VERSION ""

NS_ :

BS_:

BU_: TCM iBooster HCU CIM SCM Right_Hand_Control Left_Hand_Control GPS VCM IC_2 XM GMRS Radio_CANtool Diagnostic_Tool_Digital_Wrench Information_System_Controller_1 STEERING_CONTROLLER VEHICLE_SECURITY RADIO_Hub ABS Battery_Management_Cntrl_2 Battery_Management_Cntrl_1 Auxiliary_Power_Unit_2 Auxiliary_Power_Unit_1 Electric_Propulsion_Cntrl_Unit_4 Electric_Propulsion_Cntrl_Unit_3 Electric_Propulsion_Cntrl_Unit_2 Electric_Propulsion_Cntrl_Unit_1 ECM IC

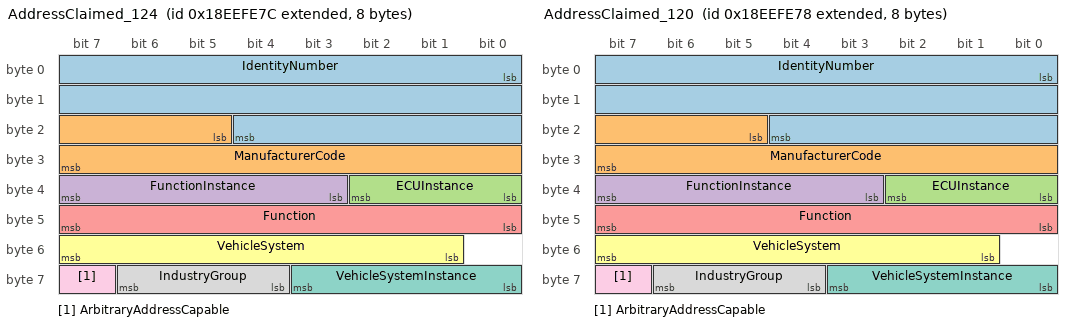
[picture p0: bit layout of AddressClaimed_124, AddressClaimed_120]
BO_ 2565799548 AddressClaimed_124: 8 GMRS
 SG_ IdentityNumber : 0|21@1+ (1,0) [0|2097151] "" Vector__XXX
 SG_ ManufacturerCode : 21|11@1+ (1,0) [0|2047] "" Vector__XXX
 SG_ ECUInstance : 32|3@1+ (1,0) [0|7] "" Vector__XXX
 SG_ FunctionInstance : 35|5@1+ (1,0) [0|31] "" Vector__XXX
 SG_ Function : 40|8@1+ (1,0) [0|255] "" Vector__XXX
 SG_ VehicleSystem : 49|7@1+ (1,0) [0|127] "" Vector__XXX
 SG_ VehicleSystemInstance : 56|4@1+ (1,0) [0|15] "" Vector__XXX
 SG_ IndustryGroup : 60|3@1+ (1,0) [0|7] "" Vector__XXX
 SG_ ArbitraryAddressCapable : 63|1@1+ (1,0) [0|0] "" Vector__XXX

BO_ 2565799544 AddressClaimed_120: 8 Radio_CANtool
 SG_ IdentityNumber : 0|21@1+ (1,0) [0|2097151] "" Vector__XXX
 SG_ ManufacturerCode : 21|11@1+ (1,0) [0|2047] "" Vector__XXX
 SG_ ECUInstance : 32|3@1+ (1,0) [0|7] "" Vector__XXX
 SG_ FunctionInstance : 35|5@1+ (1,0) [0|31] "" Vector__XXX
 SG_ Function : 40|8@1+ (1,0) [0|255] "" Vector__XXX
 SG_ VehicleSystem : 49|7@1+ (1,0) [0|127] "" Vector__XXX
 SG_ VehicleSystemInstance : 56|4@1+ (1,0) [0|15] "" Vector__XXX
 SG_ IndustryGroup : 60|3@1+ (1,0) [0|7] "" Vector__XXX
 SG_ ArbitraryAddressCapable : 63|1@1+ (1,0) [0|0] "" Vector__XXX

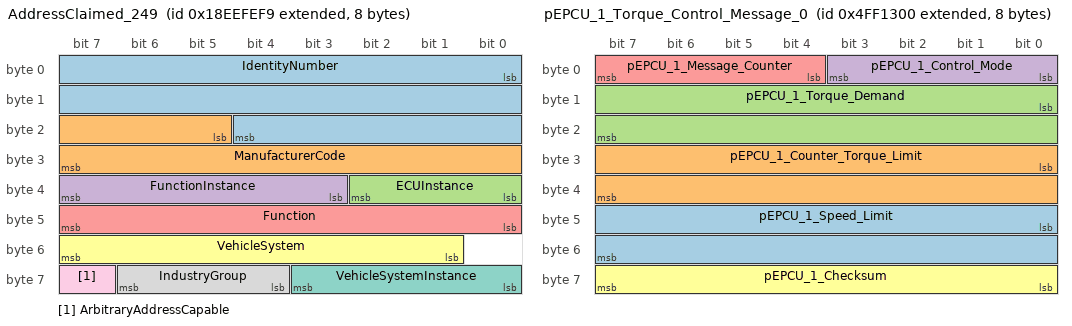
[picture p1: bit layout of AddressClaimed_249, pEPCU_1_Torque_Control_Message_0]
BO_ 2565799673 AddressClaimed_249: 8 Diagnostic_Tool_Digital_Wrench
 SG_ IdentityNumber : 0|21@1+ (1,0) [0|2097151] "" Vector__XXX
 SG_ ManufacturerCode : 21|11@1+ (1,0) [0|2047] "" Vector__XXX
 SG_ ECUInstance : 32|3@1+ (1,0) [0|7] "" Vector__XXX
 SG_ FunctionInstance : 35|5@1+ (1,0) [0|31] "" Vector__XXX
 SG_ Function : 40|8@1+ (1,0) [0|255] "" Vector__XXX
 SG_ VehicleSystem : 49|7@1+ (1,0) [0|127] "" Vector__XXX
 SG_ VehicleSystemInstance : 56|4@1+ (1,0) [0|15] "" Vector__XXX
 SG_ IndustryGroup : 60|3@1+ (1,0) [0|7] "" Vector__XXX
 SG_ ArbitraryAddressCapable : 63|1@1+ (1,0) [0|0] "" Vector__XXX

BO_ 2231309056 pEPCU_1_Torque_Control_Message_0: 8 ECM
 SG_ pEPCU_1_Speed_Limit : 40|16@1+ (1,-32768) [-32768|31488] "rpm" Vector__XXX
 SG_ pEPCU_1_Counter_Torque_Limit : 24|16@1+ (0.1,-3276.8) [-3276.8|3276.7] "Nm" Vector__XXX
 SG_ pEPCU_1_Torque_Demand : 8|16@1+ (0.1,-3276.8) [-3276.8|3276.7] "Nm" Vector__XXX
 SG_ pEPCU_1_Control_Mode : 0|4@1+ (1,0) [0|15] "" Vector__XXX
 SG_ pEPCU_1_Message_Counter : 4|4@1+ (1,0) [0|15] "" Vector__XXX
 SG_ pEPCU_1_Checksum : 56|8@1+ (1,0) [0|255] "" Vector__XXX

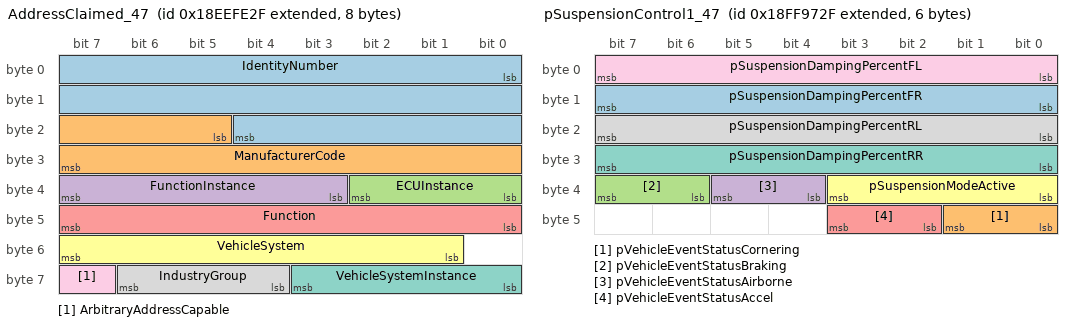
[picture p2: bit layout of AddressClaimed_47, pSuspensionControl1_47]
BO_ 2565799471 AddressClaimed_47: 8 SCM
 SG_ IdentityNumber : 0|21@1+ (1,0) [0|2097151] "" Vector__XXX
 SG_ ManufacturerCode : 21|11@1+ (1,0) [0|2047] "" Vector__XXX
 SG_ ECUInstance : 32|3@1+ (1,0) [0|7] "" Vector__XXX
 SG_ FunctionInstance : 35|5@1+ (1,0) [0|31] "" Vector__XXX
 SG_ Function : 40|8@1+ (1,0) [0|255] "" Vector__XXX
 SG_ VehicleSystem : 49|7@1+ (1,0) [0|127] "" Vector__XXX
 SG_ VehicleSystemInstance : 56|4@1+ (1,0) [0|15] "" Vector__XXX
 SG_ IndustryGroup : 60|3@1+ (1,0) [0|7] "" Vector__XXX
 SG_ ArbitraryAddressCapable : 63|1@1+ (1,0) [0|0] "" Vector__XXX

BO_ 2566887215 pSuspensionControl1_47: 6 SCM
 SG_ pSuspensionDampingPercentFR : 8|8@1+ (0.4,0) [0|100] "%" Vector__XXX
 SG_ pVehicleEventStatusCornering : 40|2@1+ (1,0) [0|3] "status" Vector__XXX
 SG_ pVehicleEventStatusBraking : 38|2@1+ (1,0) [0|3] "status" Vector__XXX
 SG_ pVehicleEventStatusAirborne : 36|2@1+ (1,0) [0|3] "status" Vector__XXX
 SG_ pVehicleEventStatusAccel : 42|2@1+ (1,0) [0|3] "status" Vector__XXX
 SG_ pSuspensionModeActive : 32|4@1+ (1,0) [0|15] "status" Vector__XXX
 SG_ pSuspensionDampingPercentRR : 24|8@1+ (0.4,0) [0|100] "%" Vector__XXX
 SG_ pSuspensionDampingPercentRL : 16|8@1+ (0.4,0) [0|100] "%" Vector__XXX
 SG_ pSuspensionDampingPercentFL : 0|8@1+ (0.4,0) [0|100] "%" Vector__XXX

BO_ 2432656705 pOperatorSwitchStatus_65: 8 Information_System_Controller_1
 SG_ pOperatorButton29 : 58|2@1+ (1,0) [0|3] "" Vector__XXX
 SG_ pOperatorButton1 : 0|2@1+ (1,0) [0|3] "" Vector__XXX
 SG_ pOperatorButton2 : 2|2@1+ (1,0) [0|3] "" Vector__XXX
 SG_ pOperatorButton3 : 4|2@1+ (1,0) [0|3] "" Vector__XXX
 SG_ pOperatorButton4 : 6|2@1+ (1,0) [0|3] "" Vector__XXX
 SG_ pOperatorButton5 : 8|2@1+ (1,0) [0|3] "" Vector__XXX
 SG_ pOperatorButton6 : 10|2@1+ (1,0) [0|3] "" Vector__XXX
 SG_ pOperatorButton7 : 12|2@1+ (1,0) [0|3] "" Vector__XXX
 SG_ pOperatorButton8 : 14|2@1+ (1,0) [0|3] "" Vector__XXX
 SG_ pOperatorButton9 : 16|2@1+ (1,0) [0|3] "" Vector__XXX
 SG_ pOperatorButton10 : 18|2@1+ (1,0) [0|3] "" Vector__XXX
 SG_ pOperatorButton11 : 20|2@1+ (1,0) [0|3] "" Vector__XXX
 SG_ pOperatorButton12 : 22|2@1+ (1,0) [0|3] "" Vector__XXX
 SG_ pOperatorButton13 : 24|2@1+ (1,0) [0|3] "" Vector__XXX
 SG_ pOperatorButton14 : 26|2@1+ (1,0) [0|3] "" Vector__XXX
 SG_ pOperatorButton15 : 28|2@1+ (1,0) [0|3] "" Vector__XXX
 SG_ pOperatorButton16 : 30|2@1+ (1,0) [0|3] "" Vector__XXX
 SG_ pOperatorButton17 : 32|2@1+ (1,0) [0|3] "" Vector__XXX
 SG_ pOperatorButton18 : 34|2@1+ (1,0) [0|3] "" Vector__XXX
 SG_ pOperatorButton19 : 36|2@1+ (1,0) [0|3] "" Vector__XXX
 SG_ pOperatorButton20 : 38|2@1+ (1,0) [0|3] "" Vector__XXX
 SG_ pOperatorButton21 : 40|2@1+ (1,0) [0|3] "" Vector__XXX
 SG_ pOperatorButton22 : 42|2@1+ (1,0) [0|3] "" Vector__XXX
 SG_ pOperatorButton23 : 44|2@1+ (1,0) [0|3] "" Vector__XXX
 SG_ pOperatorButton24 : 46|2@1+ (1,0) [0|3] "" Vector__XXX
 SG_ pOperatorButton25 : 48|2@1+ (1,0) [0|3] "" Vector__XXX
 SG_ pOperatorButton26 : 50|2@1+ (1,0) [0|3] "" Vector__XXX
 SG_ pOperatorButton27 : 52|2@1+ (1,0) [0|3] "" Vector__XXX
 SG_ pOperatorButton28 : 54|2@1+ (1,0) [0|3] "" Vector__XXX
 SG_ pSideStandStatus : 56|2@1+ (1,0) [0|3] "" Vector__XXX

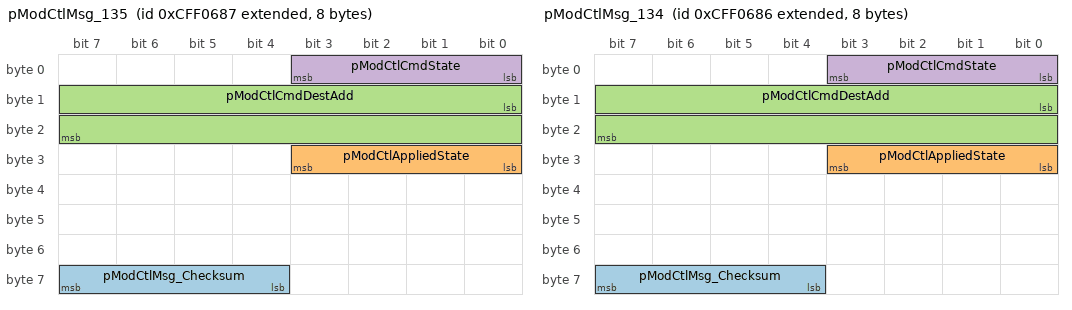
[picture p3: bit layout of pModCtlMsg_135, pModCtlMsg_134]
BO_ 2365523591 pModCtlMsg_135: 8 Left_Hand_Control
 SG_ pModCtlMsg_Checksum : 60|4@1+ (1,0) [0|0] "" Vector__XXX
 SG_ pModCtlAppliedState : 24|4@1+ (1,0) [0|0] "" Vector__XXX
 SG_ pModCtlCmdDestAdd : 8|16@1+ (1,0) [0|65535] "Address" Vector__XXX
 SG_ pModCtlCmdState : 0|4@1+ (1,0) [0|15] "" Vector__XXX

BO_ 2365523590 pModCtlMsg_134: 8 Right_Hand_Control
 SG_ pModCtlMsg_Checksum : 60|4@1+ (1,0) [0|0] "" Vector__XXX
 SG_ pModCtlAppliedState : 24|4@1+ (1,0) [0|0] "" Vector__XXX
 SG_ pModCtlCmdDestAdd : 8|16@1+ (1,0) [0|65535] "Address" Vector__XXX
 SG_ pModCtlCmdState : 0|4@1+ (1,0) [0|15] "" Vector__XXX

BO_ 2566844807 CruiseControlVehSpeed_135: 8 Left_Hand_Control
 SG_ pCruiseCntrlCounter : 50|4@1+ (1,0) [0|15] "" Vector__XXX
 SG_ TwoSpeedAxleSwitch : 0|2@1+ (1,0) [0|3] "" Vector__XXX
 SG_ ParkingBrakeSwitch : 2|2@1+ (1,0) [0|3] "" Vector__XXX
 SG_ Wheel_BasedVehicleSpeed : 8|16@1+ (0.00390625,0) [0|251] "km/h" Vector__XXX
 SG_ CruiseCtrlActive : 24|2@1+ (1,0) [0|3] "" Vector__XXX
 SG_ CruiseCtrlEnableSwitch : 26|2@1+ (1,0) [0|3] "" Vector__XXX
 SG_ BrakeSwitch : 28|2@1+ (1,0) [0|3] "" Vector__XXX
 SG_ ClutchSwitch : 30|2@1+ (1,0) [0|3] "" Vector__XXX
 SG_ CruiseCtrlSetSwitch : 32|2@1+ (1,0) [0|3] "" Vector__XXX
 SG_ CruiseCtrlCoastSwitch : 34|2@1+ (1,0) [0|3] "" Vector__XXX
 SG_ CruiseCtrlResumeSwitch : 36|2@1+ (1,0) [0|3] "" Vector__XXX
 SG_ CruiseCtrlAccelerateSwitch : 38|2@1+ (1,0) [0|3] "" Vector__XXX
 SG_ CruiseCtrlSetSpeed : 40|8@1+ (1,0) [0|250] "km/h" Vector__XXX
 SG_ pOdometerDriveBit : 6|2@1+ (1,0) [0|3] "" Vector__XXX
 SG_ CruiseCtrlPauseSw : 4|2@1+ (1,0) [0|3] "" Vector__XXX
 SG_ pCCChecksum : 56|8@1+ (1,0) [0|255] "" Vector__XXX
 SG_ pCruiseEnableStatus : 48|4@1+ (1,0) [0|15] "" Vector__XXX

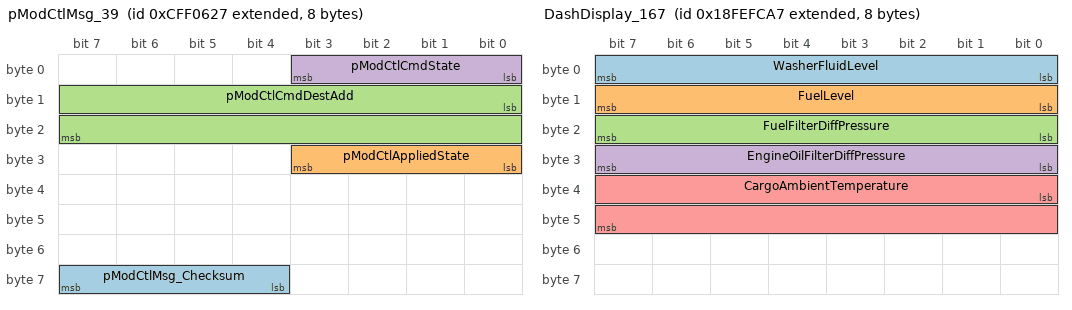
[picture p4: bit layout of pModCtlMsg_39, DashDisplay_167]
BO_ 2365523495 pModCtlMsg_39: 8 VCM
 SG_ pModCtlMsg_Checksum : 60|4@1+ (1,0) [0|0] "" Vector__XXX
 SG_ pModCtlAppliedState : 24|4@1+ (1,0) [0|0] "" Vector__XXX
 SG_ pModCtlCmdDestAdd : 8|16@1+ (1,0) [0|65535] "Address" Vector__XXX
 SG_ pModCtlCmdState : 0|4@1+ (1,0) [0|15] "" Vector__XXX

BO_ 2563833511 CabIlluminationMessage_167: 8 IC_2
 SG_ IlluminationBrightnessPercent : 0|8@1+ (0.4,0) [0|100] "%" Vector__XXX
 SG_ SwitchBacklightIlluminPercent : 8|8@1+ (0.4,0) [0|100] "%" Vector__XXX

BO_ 2566847655 DashDisplay_167: 8 IC_2
 SG_ WasherFluidLevel : 0|8@1+ (0.4,0) [0|100] "%" Vector__XXX
 SG_ FuelLevel : 8|8@1+ (0.4,0) [0|100] "%" Vector__XXX
 SG_ FuelFilterDiffPressure : 16|8@1+ (2,0) [0|500] "kPa" Vector__XXX
 SG_ EngineOilFilterDiffPressure : 24|8@1+ (0.5,0) [0|125] "kPa" Vector__XXX
 SG_ CargoAmbientTemperature : 32|16@1+ (0.03125,-273) [-273|1735] "°C" Vector__XXX

BO_ 2566834727 DM1_39: 22 VCM
 SG_ DTC5 : 144|32@1+ (1,0) [0|4294967295] "" Vector__XXX
 SG_ DTC4 : 112|32@1+ (1,0) [0|4294967295] "" Vector__XXX
 SG_ DTC3 : 80|32@1+ (1,0) [0|4294967295] "" Vector__XXX
 SG_ DTC2 : 48|32@1+ (1,0) [0|4294967295] "" Vector__XXX
 SG_ DTC1 : 16|32@1+ (1,0) [0|4294967295] "" Vector__XXX
 SG_ DM_FlashRedStopLamp : 12|2@1+ (1,0) [0|3] "" Vector__XXX
 SG_ DM_FlashProtectLamp : 8|2@1+ (1,0) [0|3] "" Vector__XXX
 SG_ DM_FlashMalfuncIndicatorLamp : 14|2@1+ (1,0) [0|3] "" Vector__XXX
 SG_ DM_FlashAmberWarningLamp : 10|2@1+ (1,0) [0|3] "" Vector__XXX
 SG_ DM_ProtectLampStatus : 0|2@1+ (1,0) [0|3] "" Vector__XXX
 SG_ DM_RedStopLampState : 4|2@1+ (1,0) [0|3] "" Vector__XXX
 SG_ DM_AmberWrningLmpStatus : 2|2@1+ (1,0) [0|3] "" Vector__XXX
 SG_ DM_MalfuncnIndicatorLampStatus : 6|2@1+ (1,0) [0|3] "" Vector__XXX

BO_ 2566832449 HiResVehicleDist_65_65: 8 Information_System_Controller_1
 SG_ HighResolTotalVehicleDistance : 0|32@1+ (0.005,0) [0|21055406] "km" Vector__XXX
 SG_ HighResolTripDistance : 32|32@1+ (0.005,0) [0|21055406] "km" Vector__XXX

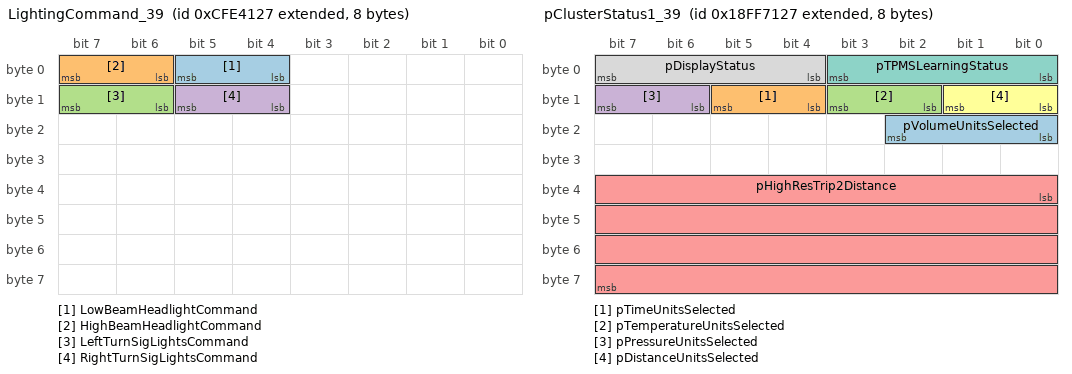
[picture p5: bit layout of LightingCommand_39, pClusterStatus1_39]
BO_ 2365473063 LightingCommand_39: 8 VCM
 SG_ LowBeamHeadlightCommand : 4|2@1+ (1,0) [0|3] "" Vector__XXX
 SG_ HighBeamHeadlightCommand : 6|2@1+ (1,0) [0|3] "" Vector__XXX
 SG_ LeftTurnSigLightsCommand : 14|2@1+ (1,0) [0|3] "" Vector__XXX
 SG_ RightTurnSigLightsCommand : 12|2@1+ (1,0) [0|3] "" Vector__XXX

BO_ 2633883431 FrontWheelDriveStatus_39: 8 VCM
 SG_ FrtWheelDriveActuatorStatus : 0|2@1+ (1,0) [0|3] "" Vector__XXX

BO_ 2566877479 pClusterStatus1_39: 8 VCM
 SG_ pVolumeUnitsSelected : 16|3@1+ (1,0) [0|7] "" Vector__XXX
 SG_ pTimeUnitsSelected : 12|2@1+ (1,0) [0|3] "" Vector__XXX
 SG_ pTemperatureUnitsSelected : 10|2@1+ (1,0) [0|3] "" Vector__XXX
 SG_ pPressureUnitsSelected : 14|2@1+ (1,0) [0|3] "" Vector__XXX
 SG_ pHighResTrip2Distance : 32|32@1+ (0.005,0) [0|21055406] "km" Vector__XXX
 SG_ pDistanceUnitsSelected : 8|2@1+ (1,0) [0|3] "" Vector__XXX
 SG_ pTPMSLearningStatus : 0|4@1+ (1,0) [0|15] "" Vector__XXX
 SG_ pDisplayStatus : 4|4@1+ (1,0) [0|15] "" Vector__XXX

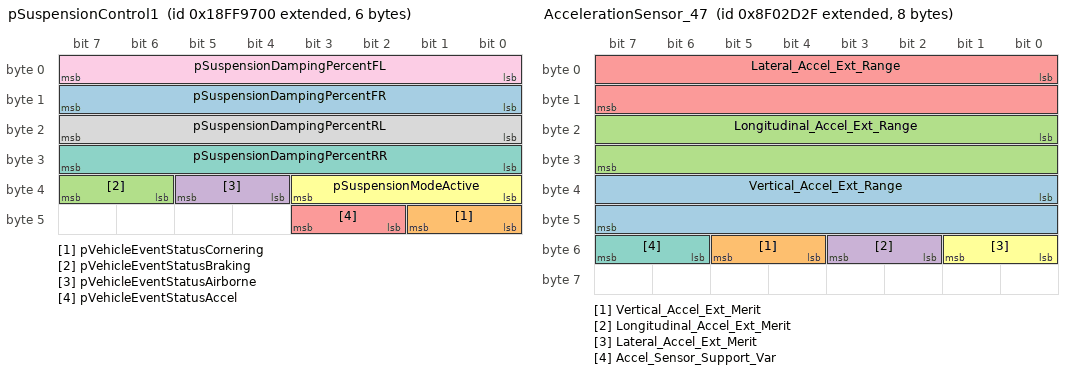
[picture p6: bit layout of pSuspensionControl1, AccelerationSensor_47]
BO_ 2566887168 pSuspensionControl1: 6 ECM
 SG_ pSuspensionDampingPercentFR : 8|8@1+ (0.4,0) [0|100] "%" Vector__XXX
 SG_ pVehicleEventStatusCornering : 40|2@1+ (1,0) [0|3] "status" Vector__XXX
 SG_ pVehicleEventStatusBraking : 38|2@1+ (1,0) [0|3] "status" Vector__XXX
 SG_ pVehicleEventStatusAirborne : 36|2@1+ (1,0) [0|3] "status" Vector__XXX
 SG_ pVehicleEventStatusAccel : 42|2@1+ (1,0) [0|3] "status" Vector__XXX
 SG_ pSuspensionModeActive : 32|4@1+ (1,0) [0|15] "status" Vector__XXX
 SG_ pSuspensionDampingPercentRR : 24|8@1+ (0.4,0) [0|100] "%" Vector__XXX
 SG_ pSuspensionDampingPercentRL : 16|8@1+ (0.4,0) [0|100] "%" Vector__XXX
 SG_ pSuspensionDampingPercentFL : 0|8@1+ (0.4,0) [0|100] "%" Vector__XXX

BO_ 2431708455 EngineStartCtl_ENGSC: 8 VCM
 SG_ MessageCounter_EngStartCtl : 53|4@1+ (1,0) [0|15] "Count" Vector__XXX
 SG_ MessageChecksum_EngStartCtl : 56|8@1+ (1,0) [0|255] "" Vector__XXX
 SG_ EngineStarter2Feedback : 13|3@1+ (1,0) [0|7] "" Vector__XXX
 SG_ EngineStarter1Feedback : 10|3@1+ (1,0) [0|7] "" Vector__XXX
 SG_ EngineStartAbortReq : 8|2@1+ (1,0) [0|3] "" Vector__XXX
 SG_ TransShiftSelectRequVehDir : 5|3@1+ (1,0) [0|7] "" Vector__XXX
 SG_ EngineStartReq : 0|2@1+ (1,0) [0|3] "" Vector__XXX
 SG_ EngineStartConsent : 2|3@1+ (1,0) [0|7] "" Vector__XXX

BO_ 2297441583 AccelerationSensor_47: 8 SCM
 SG_ Vertical_Accel_Ext_Range : 32|16@1+ (0.01,-320) [-320|322.55] "m/s2" Vector__XXX
 SG_ Vertical_Accel_Ext_Merit : 52|2@1+ (1,0) [0|3] "" Vector__XXX
 SG_ Longitudinal_Accel_Ext_Range : 16|16@1+ (0.01,-320) [-320|322.55] "m/s2" Vector__XXX
 SG_ Longitudinal_Accel_Ext_Merit : 50|2@1+ (1,0) [0|3] "" Vector__XXX
 SG_ Lateral_Accel_Ext_Range : 0|16@1+ (0.01,-320) [-320|322.55] "m/s2" Vector__XXX
 SG_ Lateral_Accel_Ext_Merit : 48|2@1+ (1,0) [0|3] "" Vector__XXX
 SG_ Accel_Sensor_Support_Var : 54|2@1+ (1,0) [0|3] "" Vector__XXX

BO_ 2432656774 pOperatorSwitchStatus_134: 8 Right_Hand_Control
 SG_ pOperatorButton29 : 58|2@1+ (1,0) [0|3] "" Vector__XXX
 SG_ pOperatorButton1 : 0|2@1+ (1,0) [0|3] "" Vector__XXX
 SG_ pOperatorButton2 : 2|2@1+ (1,0) [0|3] "" Vector__XXX
 SG_ pOperatorButton3 : 4|2@1+ (1,0) [0|3] "" Vector__XXX
 SG_ pOperatorButton4 : 6|2@1+ (1,0) [0|3] "" Vector__XXX
 SG_ pOperatorButton5 : 8|2@1+ (1,0) [0|3] "" Vector__XXX
 SG_ pOperatorButton6 : 10|2@1+ (1,0) [0|3] "" Vector__XXX
 SG_ pOperatorButton7 : 12|2@1+ (1,0) [0|3] "" Vector__XXX
 SG_ pOperatorButton8 : 14|2@1+ (1,0) [0|3] "" Vector__XXX
 SG_ pOperatorButton9 : 16|2@1+ (1,0) [0|3] "" Vector__XXX
 SG_ pOperatorButton10 : 18|2@1+ (1,0) [0|3] "" Vector__XXX
 SG_ pOperatorButton11 : 20|2@1+ (1,0) [0|3] "" Vector__XXX
 SG_ pOperatorButton12 : 22|2@1+ (1,0) [0|3] "" Vector__XXX
 SG_ pOperatorButton13 : 24|2@1+ (1,0) [0|3] "" Vector__XXX
 SG_ pOperatorButton14 : 26|2@1+ (1,0) [0|3] "" Vector__XXX
 SG_ pOperatorButton15 : 28|2@1+ (1,0) [0|3] "" Vector__XXX
 SG_ pOperatorButton16 : 30|2@1+ (1,0) [0|3] "" Vector__XXX
 SG_ pOperatorButton17 : 32|2@1+ (1,0) [0|3] "" Vector__XXX
 SG_ pOperatorButton18 : 34|2@1+ (1,0) [0|3] "" Vector__XXX
 SG_ pOperatorButton19 : 36|2@1+ (1,0) [0|3] "" Vector__XXX
 SG_ pOperatorButton20 : 38|2@1+ (1,0) [0|3] "" Vector__XXX
 SG_ pOperatorButton21 : 40|2@1+ (1,0) [0|3] "" Vector__XXX
 SG_ pOperatorButton22 : 42|2@1+ (1,0) [0|3] "" Vector__XXX
 SG_ pOperatorButton23 : 44|2@1+ (1,0) [0|3] "" Vector__XXX
 SG_ pOperatorButton24 : 46|2@1+ (1,0) [0|3] "" Vector__XXX
 SG_ pOperatorButton25 : 48|2@1+ (1,0) [0|3] "" Vector__XXX
 SG_ pOperatorButton26 : 50|2@1+ (1,0) [0|3] "" Vector__XXX
 SG_ pOperatorButton27 : 52|2@1+ (1,0) [0|3] "" Vector__XXX
 SG_ pOperatorButton28 : 54|2@1+ (1,0) [0|3] "" Vector__XXX
 SG_ pSideStandStatus : 56|2@1+ (1,0) [0|3] "" Vector__XXX

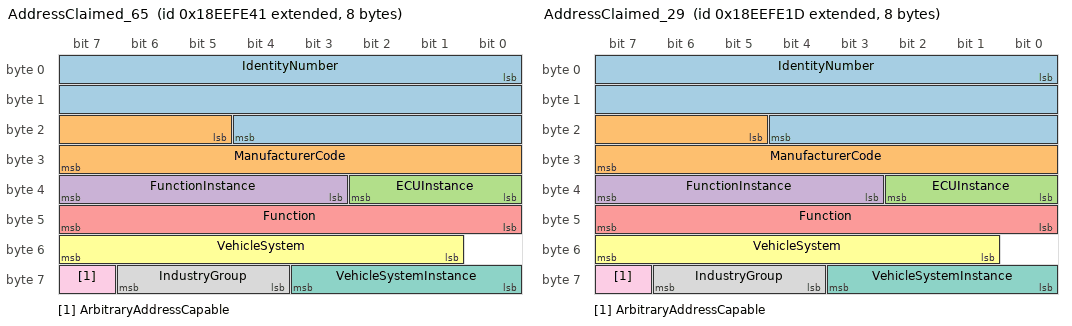
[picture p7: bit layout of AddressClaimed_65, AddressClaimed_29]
BO_ 2565799489 AddressClaimed_65: 8 Information_System_Controller_1
 SG_ IdentityNumber : 0|21@1+ (1,0) [0|2097151] "" Vector__XXX
 SG_ ManufacturerCode : 21|11@1+ (1,0) [0|2047] "" Vector__XXX
 SG_ ECUInstance : 32|3@1+ (1,0) [0|7] "" Vector__XXX
 SG_ FunctionInstance : 35|5@1+ (1,0) [0|31] "" Vector__XXX
 SG_ Function : 40|8@1+ (1,0) [0|255] "" Vector__XXX
 SG_ VehicleSystem : 49|7@1+ (1,0) [0|127] "" Vector__XXX
 SG_ VehicleSystemInstance : 56|4@1+ (1,0) [0|15] "" Vector__XXX
 SG_ IndustryGroup : 60|3@1+ (1,0) [0|7] "" Vector__XXX
 SG_ ArbitraryAddressCapable : 63|1@1+ (1,0) [0|0] "" Vector__XXX

BO_ 2565799453 AddressClaimed_29: 8 VEHICLE_SECURITY
 SG_ IdentityNumber : 0|21@1+ (1,0) [0|2097151] "" Vector__XXX
 SG_ ManufacturerCode : 21|11@1+ (1,0) [0|2047] "" Vector__XXX
 SG_ ECUInstance : 32|3@1+ (1,0) [0|7] "" Vector__XXX
 SG_ FunctionInstance : 35|5@1+ (1,0) [0|31] "" Vector__XXX
 SG_ Function : 40|8@1+ (1,0) [0|255] "" Vector__XXX
 SG_ VehicleSystem : 49|7@1+ (1,0) [0|127] "" Vector__XXX
 SG_ VehicleSystemInstance : 56|4@1+ (1,0) [0|15] "" Vector__XXX
 SG_ IndustryGroup : 60|3@1+ (1,0) [0|7] "" Vector__XXX
 SG_ ArbitraryAddressCapable : 63|1@1+ (1,0) [0|0] "" Vector__XXX

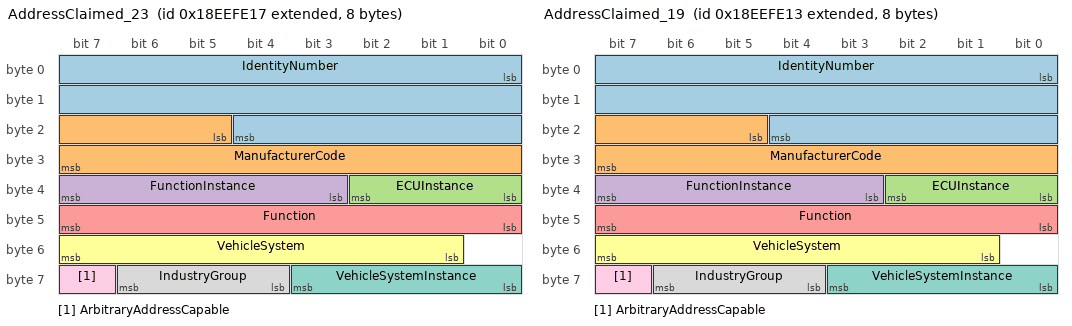
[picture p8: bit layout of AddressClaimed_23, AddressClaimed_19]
BO_ 2565799447 AddressClaimed_23: 8 IC
 SG_ IdentityNumber : 0|21@1+ (1,0) [0|2097151] "" Vector__XXX
 SG_ ManufacturerCode : 21|11@1+ (1,0) [0|2047] "" Vector__XXX
 SG_ ECUInstance : 32|3@1+ (1,0) [0|7] "" Vector__XXX
 SG_ FunctionInstance : 35|5@1+ (1,0) [0|31] "" Vector__XXX
 SG_ Function : 40|8@1+ (1,0) [0|255] "" Vector__XXX
 SG_ VehicleSystem : 49|7@1+ (1,0) [0|127] "" Vector__XXX
 SG_ VehicleSystemInstance : 56|4@1+ (1,0) [0|15] "" Vector__XXX
 SG_ IndustryGroup : 60|3@1+ (1,0) [0|7] "" Vector__XXX
 SG_ ArbitraryAddressCapable : 63|1@1+ (1,0) [0|0] "" Vector__XXX

BO_ 2565799443 AddressClaimed_19: 8 STEERING_CONTROLLER
 SG_ IdentityNumber : 0|21@1+ (1,0) [0|2097151] "" Vector__XXX
 SG_ ManufacturerCode : 21|11@1+ (1,0) [0|2047] "" Vector__XXX
 SG_ ECUInstance : 32|3@1+ (1,0) [0|7] "" Vector__XXX
 SG_ FunctionInstance : 35|5@1+ (1,0) [0|31] "" Vector__XXX
 SG_ Function : 40|8@1+ (1,0) [0|255] "" Vector__XXX
 SG_ VehicleSystem : 49|7@1+ (1,0) [0|127] "" Vector__XXX
 SG_ VehicleSystemInstance : 56|4@1+ (1,0) [0|15] "" Vector__XXX
 SG_ IndustryGroup : 60|3@1+ (1,0) [0|7] "" Vector__XXX
 SG_ ArbitraryAddressCapable : 63|1@1+ (1,0) [0|0] "" Vector__XXX

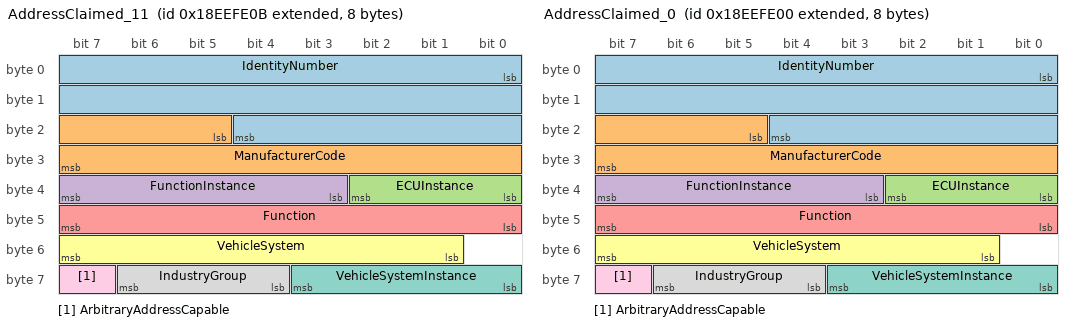
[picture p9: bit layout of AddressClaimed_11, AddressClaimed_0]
BO_ 2565799435 AddressClaimed_11: 8 ABS
 SG_ IdentityNumber : 0|21@1+ (1,0) [0|2097151] ""  Auxiliary_Power_Unit_1
 SG_ ManufacturerCode : 21|11@1+ (1,0) [0|2047] ""  Auxiliary_Power_Unit_1
 SG_ ECUInstance : 32|3@1+ (1,0) [0|7] ""  Auxiliary_Power_Unit_1
 SG_ FunctionInstance : 35|5@1+ (1,0) [0|31] ""  Auxiliary_Power_Unit_1
 SG_ Function : 40|8@1+ (1,0) [0|255] ""  Auxiliary_Power_Unit_1
 SG_ VehicleSystem : 49|7@1+ (1,0) [0|127] ""  Auxiliary_Power_Unit_1
 SG_ VehicleSystemInstance : 56|4@1+ (1,0) [0|15] ""  Auxiliary_Power_Unit_1
 SG_ IndustryGroup : 60|3@1+ (1,0) [0|7] ""  Auxiliary_Power_Unit_1
 SG_ ArbitraryAddressCapable : 63|1@1+ (1,0) [0|0] ""  Auxiliary_Power_Unit_1

BO_ 2565799424 AddressClaimed_0: 8 ECM
 SG_ IdentityNumber : 0|21@1+ (1,0) [0|2097151] "" Vector__XXX
 SG_ ManufacturerCode : 21|11@1+ (1,0) [0|2047] "" Vector__XXX
 SG_ ECUInstance : 32|3@1+ (1,0) [0|7] "" Vector__XXX
 SG_ FunctionInstance : 35|5@1+ (1,0) [0|31] "" Vector__XXX
 SG_ Function : 40|8@1+ (1,0) [0|255] "" Vector__XXX
 SG_ VehicleSystem : 49|7@1+ (1,0) [0|127] "" Vector__XXX
 SG_ VehicleSystemInstance : 56|4@1+ (1,0) [0|15] "" Vector__XXX
 SG_ IndustryGroup : 60|3@1+ (1,0) [0|7] "" Vector__XXX
 SG_ ArbitraryAddressCapable : 63|1@1+ (1,0) [0|0] "" Vector__XXX

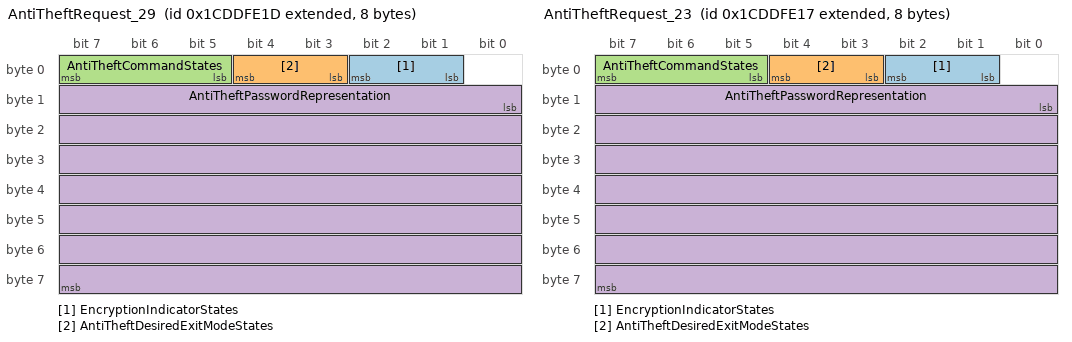
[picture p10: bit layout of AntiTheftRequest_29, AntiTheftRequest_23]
BO_ 2631794205 AntiTheftRequest_29: 8 VEHICLE_SECURITY
 SG_ EncryptionIndicatorStates : 1|2@1+ (1,0) [0|3] "" Vector__XXX
 SG_ AntiTheftDesiredExitModeStates : 3|2@1+ (1,0) [0|3] "" Vector__XXX
 SG_ AntiTheftCommandStates : 5|3@1+ (1,0) [0|7] "" Vector__XXX
 SG_ AntiTheftPasswordRepresentation : 8|56@1+ (1,0) [0|0] "" Vector__XXX

BO_ 2631794199 AntiTheftRequest_23: 8 IC
 SG_ EncryptionIndicatorStates : 1|2@1+ (1,0) [0|3] "" Vector__XXX
 SG_ AntiTheftDesiredExitModeStates : 3|2@1+ (1,0) [0|3] "" Vector__XXX
 SG_ AntiTheftCommandStates : 5|3@1+ (1,0) [0|7] "" Vector__XXX
 SG_ AntiTheftPasswordRepresentation : 8|56@1+ (1,0) [0|0] "" Vector__XXX

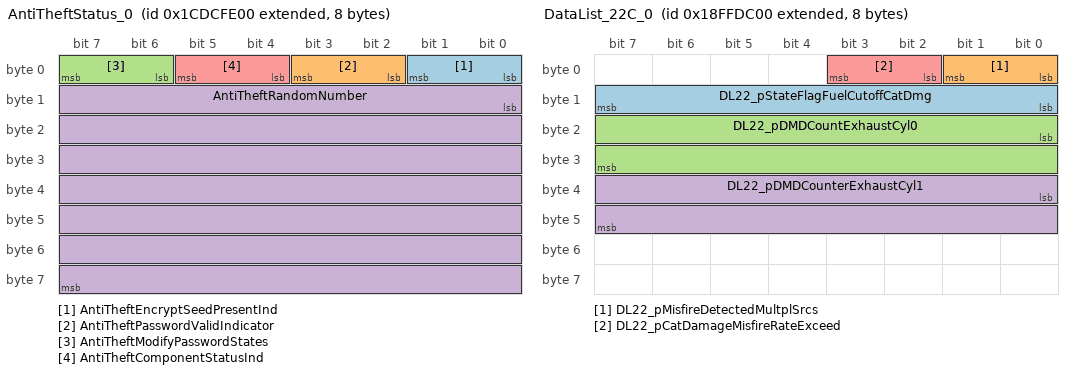
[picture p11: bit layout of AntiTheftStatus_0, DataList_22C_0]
BO_ 2631728640 AntiTheftStatus_0: 8 ECM
 SG_ AntiTheftEncryptSeedPresentInd : 0|2@1+ (1,0) [0|3] "" Vector__XXX
 SG_ AntiTheftPasswordValidIndicator : 2|2@1+ (1,0) [0|3] "" Vector__XXX
 SG_ AntiTheftModifyPasswordStates : 6|2@1+ (1,0) [0|3] "" Vector__XXX
 SG_ AntiTheftRandomNumber : 8|56@1+ (1,0) [0|0] "" Vector__XXX
 SG_ AntiTheftComponentStatusInd : 4|2@1+ (1,0) [0|3] "" Vector__XXX

BO_ 2561212031 TextDisplay_127: 8 RADIO_Hub
 SG_ TextDisplayInstructions : 0|4@1+ (1,0) [0|15] "" Vector__XXX
 SG_ TextDisplayCharacter : 24|40@1+ (1,0) [0|1099511627800] "ASCII" Vector__XXX
 SG_ TextDisplayIndex : 16|8@1+ (1,0) [0|250] "Count" Vector__XXX

BO_ 2566905088 DataList_21_00: 8 ECM
 SG_ DL21_pCyl1WeightedCatMisfireDmg : 16|16@1+ (1,0) [0|65535] "" Vector__XXX
 SG_ DL21_pCyl0WeightedCatMisfireDmg : 0|16@1+ (1,0) [0|65535] "" Vector__XXX

BO_ 2566904832 DataList_22C_0: 8 ECM
 SG_ DL22_pStateFlagFuelCutoffCatDmg : 8|8@1+ (1,0) [0|255] "Count" Vector__XXX
 SG_ DL22_pMisfireDetectedMultplSrcs : 0|2@1+ (1,0) [0|3] "" Vector__XXX
 SG_ DL22_pDMDCountExhaustCyl0 : 16|16@1+ (1,0) [0|65535] "" Vector__XXX
 SG_ DL22_pDMDCounterExhaustCyl1 : 32|16@1+ (1,0) [0|65535] "" Vector__XXX
 SG_ DL22_pCatDamageMisfireRateExceed : 2|2@1+ (1,0) [0|3] "" Vector__XXX

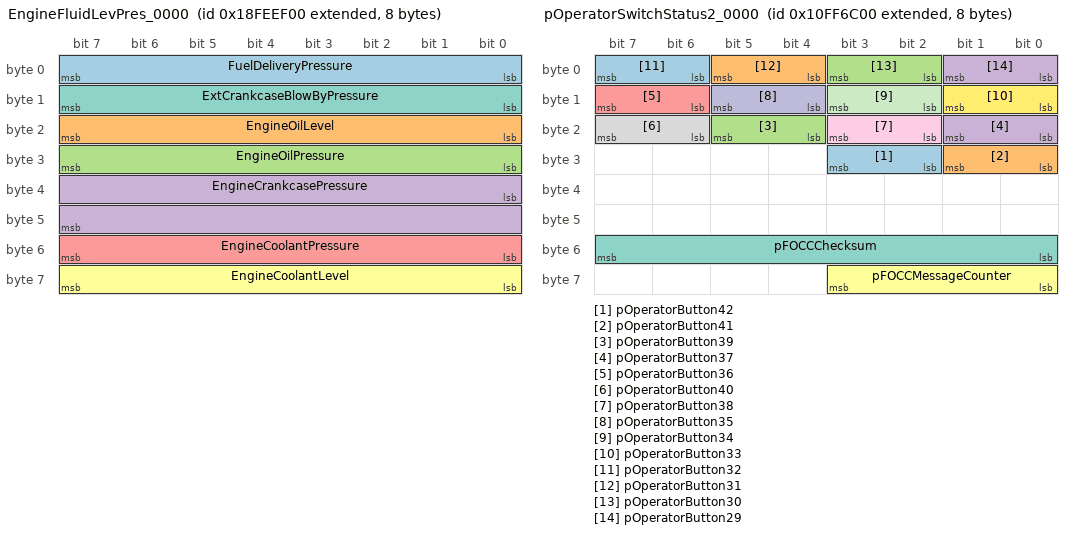
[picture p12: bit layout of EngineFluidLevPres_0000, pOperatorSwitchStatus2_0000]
BO_ 2566844160 EngineFluidLevPres_0000: 8 ECM
 SG_ FuelDeliveryPressure : 0|8@1+ (4,0) [0|1000] "kPa" Vector__XXX
 SG_ EngineOilLevel : 16|8@1+ (0.4,0) [0|100] "%" Vector__XXX
 SG_ EngineOilPressure : 24|8@1+ (4,0) [0|1000] "kPa" Vector__XXX
 SG_ EngineCrankcasePressure : 32|16@1+ (0.0078125,-250) [-250|251.99] "kPa" Vector__XXX
 SG_ EngineCoolantPressure : 48|8@1+ (2,0) [0|500] "kPa" Vector__XXX
 SG_ EngineCoolantLevel : 56|8@1+ (0.4,0) [0|100] "%" Vector__XXX
 SG_ ExtCrankcaseBlowByPressure : 8|8@1+ (0.05,0) [0|12.5] "kPa" Vector__XXX

BO_ 2432658432 pOperatorSwitchStatus2_0000: 8 ECM
 SG_ pOperatorButton42 : 26|2@1+ (1,0) [0|3] "" Vector__XXX
 SG_ pOperatorButton41 : 24|2@1+ (1,0) [0|3] "" Vector__XXX
 SG_ pOperatorButton39 : 20|2@1+ (1,0) [0|3] "" Vector__XXX
 SG_ pOperatorButton37 : 16|2@1+ (1,0) [0|3] "" Vector__XXX
 SG_ pOperatorButton36 : 14|2@1+ (1,0) [0|3] "" Vector__XXX
 SG_ pFOCCMessageCounter : 56|4@1+ (1,0) [0|15] "" Vector__XXX
 SG_ pFOCCChecksum : 48|8@1+ (1,0) [0|255] "" Vector__XXX
 SG_ pOperatorButton40 : 22|2@1+ (1,0) [0|3] "" Vector__XXX
 SG_ pOperatorButton38 : 18|2@1+ (1,0) [0|3] "" Vector__XXX
 SG_ pOperatorButton35 : 12|2@1+ (1,0) [0|3] "" Vector__XXX
 SG_ pOperatorButton34 : 10|2@1+ (1,0) [0|3] "" Vector__XXX
 SG_ pOperatorButton33 : 8|2@1+ (1,0) [0|3] "" Vector__XXX
 SG_ pOperatorButton32 : 6|2@1+ (1,0) [0|3] "" Vector__XXX
 SG_ pOperatorButton31 : 4|2@1+ (1,0) [0|3] "" Vector__XXX
 SG_ pOperatorButton30 : 2|2@1+ (1,0) [0|3] "" Vector__XXX
 SG_ pOperatorButton29 : 0|2@1+ (1,0) [0|3] "" Vector__XXX

BO_ 2633984512 pDriveSystemStatus_0: 8 ECM
 SG_ pHeatedGripEnable : 48|2@1+ (1,0) [0|3] "" Vector__XXX
 SG_ pSideStandStatus : 36|2@1+ (1,0) [0|3] "" Vector__XXX
 SG_ pTetherSwitchStatus : 46|2@1+ (1,0) [0|3] "" Vector__XXX
 SG_ pLowFuelIndicatorStatus : 10|2@1+ (1,0) [0|3] "" Vector__XXX
 SG_ pOperatorNotInOperatingStation : 38|2@1+ (1,0) [0|3] "" Vector__XXX
 SG_ pParkBrakeIndicatorStatus : 40|3@1+ (1,0) [0|7] "" Vector__XXX
 SG_ pADCRequested : 34|2@1+ (1,0) [0|3] "" Vector__XXX
 SG_ pAWDModeRequested : 32|2@1+ (1,0) [0|3] "" Vector__XXX
 SG_ pRWDModeRequested : 30|2@1+ (1,0) [0|3] "" Vector__XXX
 SG_ pTurfModeRequested : 28|2@1+ (1,0) [0|3] "" Vector__XXX
 SG_ pADCStatus : 0|2@1+ (1,0) [0|3] "" Vector__XXX
 SG_ pTreadleNeutralStatus : 2|2@1+ (1,0) [0|3] "" Vector__XXX
 SG_ pTreadleReverseStatus : 4|2@1+ (1,0) [0|3] "" Vector__XXX
 SG_ pSecurityLightStatus : 6|2@1+ (1,0) [0|3] "" Vector__XXX
 SG_ pHighBeamIndicatorStatus : 8|2@1+ (1,0) [0|3] "" Vector__XXX
 SG_ pHeatedGripsPercentage : 16|8@1+ (0.4,0) [0|100] "%" Vector__XXX
 SG_ pCruiseControlSetStatus : 24|2@1+ (1,0) [0|3] "" Vector__XXX
 SG_ pSeatBeltIndicatorStatus : 12|3@1+ (1,0) [0|7] "" Vector__XXX

BO_ 2566847511 DashDisplay_23: 8 IC
 SG_ WasherFluidLevel : 0|8@1+ (0.4,0) [0|100] "%" Vector__XXX
 SG_ FuelLevel : 8|8@1+ (0.4,0) [0|100] "%" Vector__XXX
 SG_ FuelFilterDiffPressure : 16|8@1+ (2,0) [0|500] "kPa" Vector__XXX
 SG_ EngineOilFilterDiffPressure : 24|8@1+ (0.5,0) [0|125] "kPa" Vector__XXX
 SG_ CargoAmbientTemperature : 32|16@1+ (0.03125,-273) [-273|1735] "°C" Vector__XXX

BO_ 2566845719 AmbientConditions_23: 8 IC
 SG_ DL_BarometricPressure : 0|16@1+ (0.007813,0) [0|511.99] "kPa" Vector__XXX
 SG_ CabInteriorTemperature : 8|16@1+ (0.03125,-273) [-273|1735] "°C" Vector__XXX
 SG_ AmbientAirTemperature : 24|16@1+ (0.03125,-273) [-273|1735] "°C" Vector__XXX
 SG_ EngineAirInletTemperature : 40|8@1+ (1,-40) [-40|210] "°C" Vector__XXX
 SG_ RoadSurfaceTemperature : 48|16@1+ (0.03125,-273) [-273|1734.96875] "°C" Vector__XXX

BO_ 2566847488 DashDisplay_0: 8 ECM
 SG_ WasherFluidLevel : 0|8@1+ (0.4,0) [0|100] "%" Vector__XXX
 SG_ FuelLevel : 8|8@1+ (0.4,0) [0|100] "%" Vector__XXX
 SG_ FuelFilterDiffPressure : 16|8@1+ (2,0) [0|500] "kPa" Vector__XXX
 SG_ EngineOilFilterDiffPressure : 24|8@1+ (0.5,0) [0|125] "kPa" Vector__XXX
 SG_ CargoAmbientTemperature : 32|16@1+ (0.03125,-273) [-273|1735] "°C" Vector__XXX

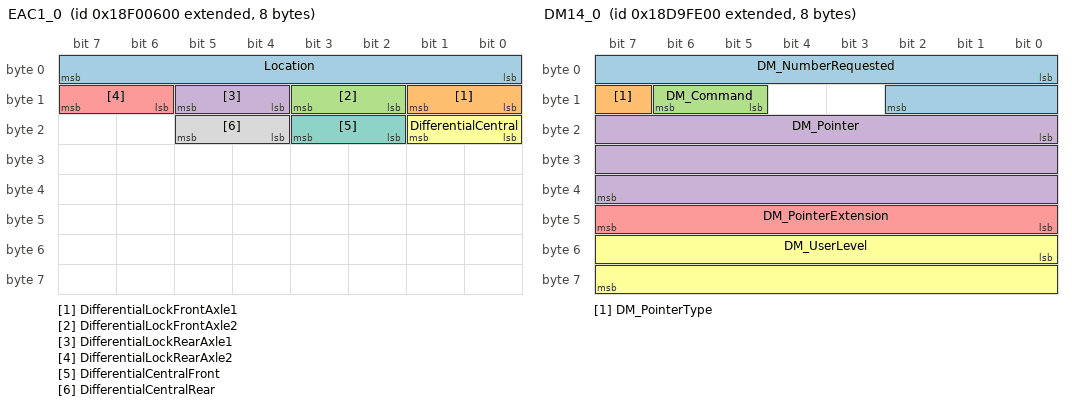
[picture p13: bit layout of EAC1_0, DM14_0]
BO_ 2565867008 EAC1_0: 8 ECM
 SG_ Location : 0|8@1+ (1,0) [0|255] "" Vector__XXX
 SG_ DifferentialLockFrontAxle1 : 8|2@1+ (1,0) [0|3] "" Vector__XXX
 SG_ DifferentialLockFrontAxle2 : 10|2@1+ (1,0) [0|3] "" Vector__XXX
 SG_ DifferentialLockRearAxle1 : 12|2@1+ (1,0) [0|3] "" Vector__XXX
 SG_ DifferentialLockRearAxle2 : 14|2@1+ (1,0) [0|3] "" Vector__XXX
 SG_ DifferentialCentral : 16|2@1+ (1,0) [0|3] "" Vector__XXX
 SG_ DifferentialCentralFront : 18|2@1+ (1,0) [0|3] "" Vector__XXX
 SG_ DifferentialCentralRear : 20|2@1+ (1,0) [0|3] "" Vector__XXX

BO_ 2566841600 EngineHoursRevolutions_0: 8 ECM
 SG_ EngTotalHoursOfOper : 0|32@1+ (0.05,0) [0|210554060.75] "h" Vector__XXX
 SG_ TotalEngineRevolutions : 32|32@1+ (1000,0) [0|4211081215000] "r" Vector__XXX

BO_ 2566832407 HiResVehicleDist_23: 8 IC
 SG_ HighResolTotalVehicleDistance : 0|32@1+ (0.005,0) [0|21055406] "km" Vector__XXX
 SG_ HighResolTripDistance : 32|32@1+ (0.005,0) [0|21055406] "km" Vector__XXX

BO_ 2566834688 DM1_0: 22 ECM
 SG_ DM_ProtectLampStatus : 0|2@1+ (1,0) [0|3] "" Vector__XXX
 SG_ DM_RedStopLampState : 4|2@1+ (1,0) [0|3] "" Vector__XXX
 SG_ DM_AmberWrningLmpStatus : 2|2@1+ (1,0) [0|3] "" Vector__XXX
 SG_ DM_MalfuncnIndicatorLampStatus : 6|2@1+ (1,0) [0|3] "" Vector__XXX
 SG_ DM_FlashRedStopLamp : 12|2@1+ (1,0) [0|3] "" Vector__XXX
 SG_ DM_FlashMalfuncIndicatorLamp : 14|2@1+ (1,0) [0|3] "" Vector__XXX
 SG_ DTC5 : 144|32@1+ (1,0) [0|4294967295] "" Vector__XXX
 SG_ DTC4 : 112|32@1+ (1,0) [0|4294967295] "" Vector__XXX
 SG_ DTC3 : 80|32@1+ (1,0) [0|4294967295] "" Vector__XXX
 SG_ DTC2 : 48|32@1+ (1,0) [0|4294967295] "" Vector__XXX
 SG_ DTC1 : 16|32@1+ (1,0) [0|4294967295] "" Vector__XXX
 SG_ DM_FlashProtectLamp : 8|2@1+ (1,0) [0|3] "" Vector__XXX
 SG_ DM_FlashAmberWarningLamp : 10|2@1+ (1,0) [0|3] "" Vector__XXX

BO_ 2564423168 DM14_0: 8 ECM
 SG_ DM_NumberRequested : 0|11@1+ (1,0) [0|2047] "" Vector__XXX
 SG_ DM_PointerType : 15|1@1+ (1,0) [0|1] "" Vector__XXX
 SG_ DM_Command : 13|2@1+ (1,0) [0|3] "" Vector__XXX
 SG_ DM_Pointer : 16|24@1+ (1,0) [0|16777215] "" Vector__XXX
 SG_ DM_PointerExtension : 40|8@1+ (1,0) [0|255] "" Vector__XXX
 SG_ DM_UserLevel : 48|16@1+ (1,0) [0|65535] "" Vector__XXX

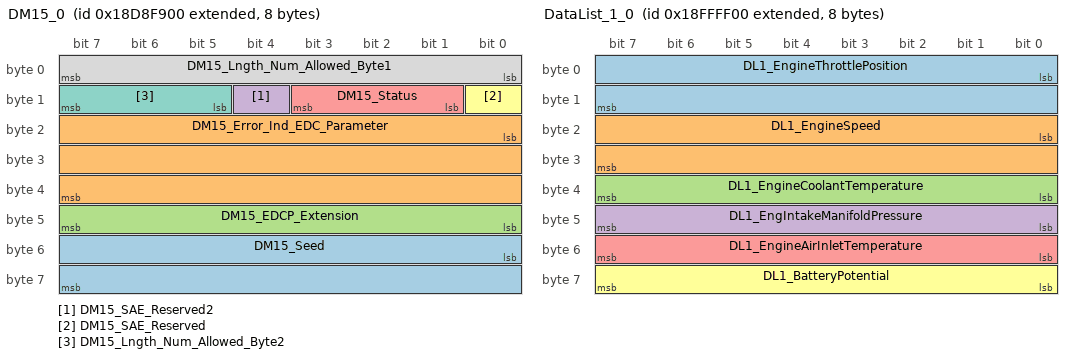
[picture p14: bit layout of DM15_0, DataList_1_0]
BO_ 2564356352 DM15_0: 8 ECM
 SG_ DM15_Seed : 48|16@1+ (1,0) [0|65535] "" Vector__XXX
 SG_ DM15_Error_Ind_EDC_Parameter : 16|24@1+ (1,0) [0|16777215] "" Vector__XXX
 SG_ DM15_EDCP_Extension : 40|8@1+ (1,0) [0|255] "" Vector__XXX
 SG_ DM15_SAE_Reserved2 : 12|1@1+ (1,0) [1|1] "" Vector__XXX
 SG_ DM15_Status : 9|3@1+ (1,0) [0|7] "" Vector__XXX
 SG_ DM15_SAE_Reserved : 8|1@1+ (1,0) [1|1] "" Vector__XXX
 SG_ DM15_Lngth_Num_Allowed_Byte2 : 13|3@1+ (1,0) [0|7] "" Vector__XXX
 SG_ DM15_Lngth_Num_Allowed_Byte1 : 0|8@1+ (1,0) [0|255] "" Vector__XXX

BO_ 2633883392 FrontWheelDriveStatus_0: 8 ECM
 SG_ FrtWheelDriveActuatorStatus : 0|2@1+ (1,0) [0|3] "" Vector__XXX

BO_ 2432656640 pOperatorSwitchStatus_0: 8 ECM
 SG_ pOperatorButton29 : 58|2@1+ (1,0) [0|3] "" Vector__XXX
 SG_ pOperatorButton1 : 0|2@1+ (1,0) [0|3] "" Vector__XXX
 SG_ pOperatorButton2 : 2|2@1+ (1,0) [0|3] "" Vector__XXX
 SG_ pOperatorButton3 : 4|2@1+ (1,0) [0|3] "" Vector__XXX
 SG_ pOperatorButton4 : 6|2@1+ (1,0) [0|3] "" Vector__XXX
 SG_ pOperatorButton5 : 8|2@1+ (1,0) [0|3] "" Vector__XXX
 SG_ pOperatorButton6 : 10|2@1+ (1,0) [0|3] "" Vector__XXX
 SG_ pOperatorButton7 : 12|2@1+ (1,0) [0|3] "" Vector__XXX
 SG_ pOperatorButton8 : 14|2@1+ (1,0) [0|3] "" Vector__XXX
 SG_ pOperatorButton9 : 16|2@1+ (1,0) [0|3] "" Vector__XXX
 SG_ pOperatorButton10 : 18|2@1+ (1,0) [0|3] "" Vector__XXX
 SG_ pOperatorButton11 : 20|2@1+ (1,0) [0|3] "" Vector__XXX
 SG_ pOperatorButton12 : 22|2@1+ (1,0) [0|3] "" Vector__XXX
 SG_ pOperatorButton13 : 24|2@1+ (1,0) [0|3] "" Vector__XXX
 SG_ pOperatorButton14 : 26|2@1+ (1,0) [0|3] "" Vector__XXX
 SG_ pOperatorButton15 : 28|2@1+ (1,0) [0|3] "" Vector__XXX
 SG_ pOperatorButton16 : 30|2@1+ (1,0) [0|3] "" Vector__XXX
 SG_ pOperatorButton17 : 32|2@1+ (1,0) [0|3] "" Vector__XXX
 SG_ pOperatorButton18 : 34|2@1+ (1,0) [0|3] "" Vector__XXX
 SG_ pOperatorButton19 : 36|2@1+ (1,0) [0|3] "" Vector__XXX
 SG_ pOperatorButton20 : 38|2@1+ (1,0) [0|3] "" Vector__XXX
 SG_ pOperatorButton21 : 40|2@1+ (1,0) [0|3] "" Vector__XXX
 SG_ pOperatorButton22 : 42|2@1+ (1,0) [0|3] "" Vector__XXX
 SG_ pOperatorButton23 : 44|2@1+ (1,0) [0|3] "" Vector__XXX
 SG_ pOperatorButton24 : 46|2@1+ (1,0) [0|3] "" Vector__XXX
 SG_ pOperatorButton25 : 48|2@1+ (1,0) [0|3] "" Vector__XXX
 SG_ pOperatorButton26 : 50|2@1+ (1,0) [0|3] "" Vector__XXX
 SG_ pOperatorButton27 : 52|2@1+ (1,0) [0|3] "" Vector__XXX
 SG_ pOperatorButton28 : 54|2@1+ (1,0) [0|3] "" Vector__XXX
 SG_ pSideStandStatus : 56|2@1+ (1,0) [0|3] "" Vector__XXX

BO_ 2365548032 pEngICS_0: 8 ECM
 SG_ pHighIdleState : 18|2@1+ (1,0) [0|3] "" Vector__XXX
 SG_ pEngineSpeed : 0|16@1+ (1,0) [0|64255] "rpm" Vector__XXX
 SG_ pStuckThrottle : 16|2@1+ (1,0) [0|3] "" Vector__XXX
 SG_ pFuelRange : 24|16@1+ (1,0) [0|64255] "km" Vector__XXX

BO_ 2566913792 DataList_1_0: 8 ECM
 SG_ DL1_EngineThrottlePosition : 0|16@1+ (0.01,0) [0|655.35] "V" Vector__XXX
 SG_ DL1_EngineSpeed : 16|16@1+ (1,0) [0|65535] "rpm" Vector__XXX
 SG_ DL1_EngineCoolantTemperature : 32|8@1+ (0.025,0) [0|6.375] "V" Vector__XXX
 SG_ DL1_EngIntakeManifoldPressure : 40|8@1+ (0.025,0) [0|6.375] "V" Vector__XXX
 SG_ DL1_EngineAirInletTemperature : 48|8@1+ (0.025,0) [0|6.375] "V" Vector__XXX
 SG_ DL1_BatteryPotential : 56|8@1+ (0.1,0) [0|25.5] "V" Vector__XXX

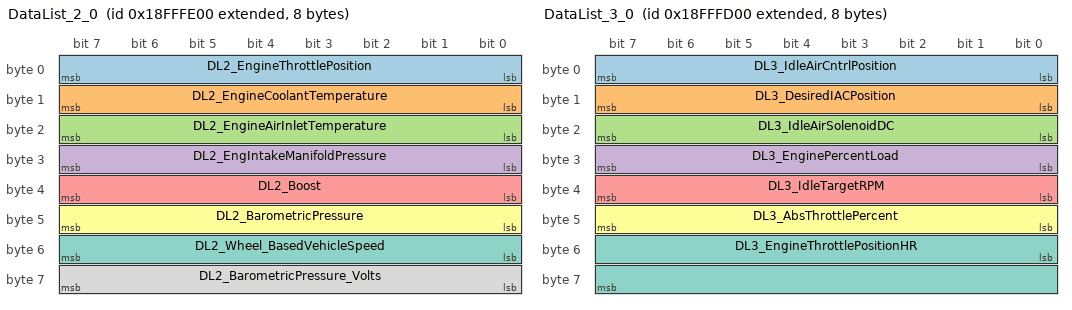
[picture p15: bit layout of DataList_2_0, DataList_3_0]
BO_ 2566913536 DataList_2_0: 8 ECM
 SG_ DL2_EngineThrottlePosition : 0|8@1+ (0.4,0) [0|100] "%" Vector__XXX
 SG_ DL2_EngineCoolantTemperature : 8|8@1+ (1,-40) [-40|210] "°C" Vector__XXX
 SG_ DL2_EngineAirInletTemperature : 16|8@1+ (1,-40) [-40|210] "°C" Vector__XXX
 SG_ DL2_EngIntakeManifoldPressure : 24|8@1+ (2,0) [0|500] "kPa" Vector__XXX
 SG_ DL2_Boost : 32|8@1+ (2,0) [0|500] "kPa" Vector__XXX
 SG_ DL2_BarometricPressure : 40|8@1+ (0.5,0) [0|125] "kPa" Vector__XXX
 SG_ DL2_Wheel_BasedVehicleSpeed : 48|8@1+ (1,0) [0|255] "km/h" Vector__XXX
 SG_ DL2_BarometricPressure_Volts : 56|8@1+ (0.025,0) [0|6.375] "V" Vector__XXX

BO_ 2566913280 DataList_3_0: 8 ECM
 SG_ DL3_IdleAirCntrlPosition : 0|8@1+ (1,0) [0|255] "Step" Vector__XXX
 SG_ DL3_DesiredIACPosition : 8|8@1+ (1,0) [0|255] "Step" Vector__XXX
 SG_ DL3_IdleAirSolenoidDC : 16|8@1+ (0.4,0) [0|102] "%" Vector__XXX
 SG_ DL3_EnginePercentLoad : 24|8@1+ (0.4,0) [0|102] "%" Vector__XXX
 SG_ DL3_IdleTargetRPM : 32|8@1+ (10,0) [0|2550] "RPM" Vector__XXX
 SG_ DL3_AbsThrottlePercent : 40|8@1+ (0.4,0) [0|102] "%" Vector__XXX
 SG_ DL3_EngineThrottlePositionHR : 48|16@1+ (0.001,0) [0|65.535] "V" Vector__XXX

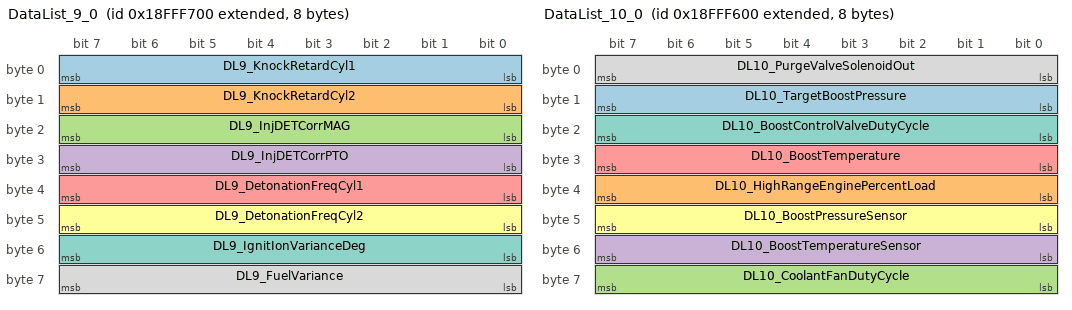
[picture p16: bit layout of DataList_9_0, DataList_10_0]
BO_ 2566911744 DataList_9_0: 8 ECM
 SG_ DL9_KnockRetardCyl1 : 0|8@1+ (1,0) [0|255] "Deg" Vector__XXX
 SG_ DL9_KnockRetardCyl2 : 8|8@1+ (1,0) [0|255] "Deg" Vector__XXX
 SG_ DL9_InjDETCorrMAG : 16|8@1+ (0.1,100) [100|125.5] "%" Vector__XXX
 SG_ DL9_InjDETCorrPTO : 24|8@1+ (0.1,100) [100|125.5] "%" Vector__XXX
 SG_ DL9_DetonationFreqCyl1 : 32|8@1+ (0.4,0) [0|102] "%" Vector__XXX
 SG_ DL9_DetonationFreqCyl2 : 40|8@1+ (0.4,0) [0|102] "%" Vector__XXX
 SG_ DL9_IgnitIonVarianceDeg : 48|8@1+ (0.2,-10) [-10|41] "Deg" Vector__XXX
 SG_ DL9_FuelVariance : 56|8@1+ (1,0) [0|255] "%" Vector__XXX

BO_ 2566911488 DataList_10_0: 8 ECM
 SG_ DL10_TargetBoostPressure : 8|8@1+ (2,0) [0|510] "kPa" Vector__XXX
 SG_ DL10_HighRangeEnginePercentLoad : 32|8@1+ (2,0) [0|510] "%" Vector__XXX
 SG_ DL10_CoolantFanDutyCycle : 56|8@1+ (0.4,0) [0|102] "%" Vector__XXX
 SG_ DL10_BoostTemperatureSensor : 48|8@1+ (0.025,0) [0|6.375] "Volts" Vector__XXX
 SG_ DL10_BoostTemperature : 24|8@1+ (1,-40) [-40|215] "degC" Vector__XXX
 SG_ DL10_BoostPressureSensor : 40|8@1+ (0.025,0) [0|6.375] "Volts" Vector__XXX
 SG_ DL10_BoostControlValveDutyCycle : 16|8@1+ (0.4,0) [0|102] "%" Vector__XXX
 SG_ DL10_PurgeValveSolenoidOut : 0|8@1+ (0.4,0) [0|102] "%" Vector__XXX

BO_ 2566909952 DataList_11_0: 8 ECM
 SG_ DL11_InterFanDriver1DutyCycle : 48|8@1+ (0.4,0) [0|102] "%" Vector__XXX
 SG_ DL11_EngineOilPressureSensor : 40|8@1+ (0.025,0) [0|6.375] "Volts" Vector__XXX
 SG_ DL11_EngineOilPressure : 32|8@1+ (4,0) [0|1020] "kPa" Vector__XXX
 SG_ DL11_EngRunTime : 0|16@1+ (2,0) [0|131070] "Min" Vector__XXX
 SG_ DL11_EngRunTimeKeyOn : 16|16@1+ (2,0) [0|131070] "Min" Vector__XXX

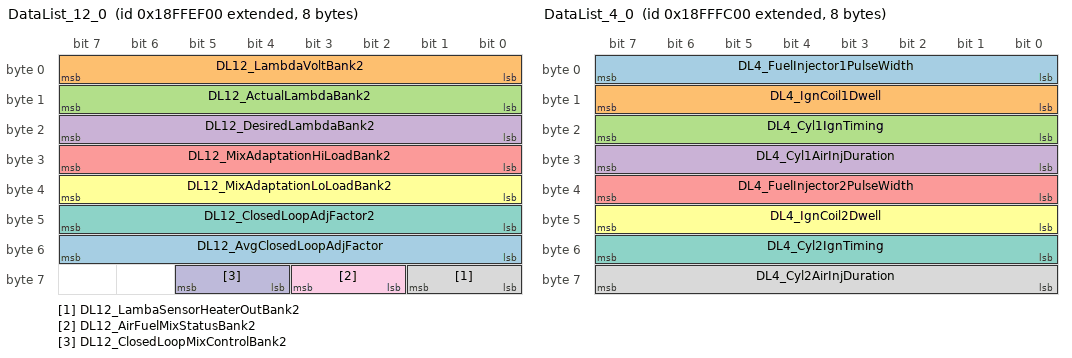
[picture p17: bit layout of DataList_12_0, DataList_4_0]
BO_ 2566909696 DataList_12_0: 8 ECM
 SG_ DL12_AvgClosedLoopAdjFactor : 48|8@1+ (0.0078125,0) [0|1.9921875] "" Vector__XXX
 SG_ DL12_LambdaVoltBank2 : 0|8@1+ (0.02,0) [0|5] "V" Vector__XXX
 SG_ DL12_ActualLambdaBank2 : 8|8@1+ (0.0078125,0) [0|1.95] "Ratio" Vector__XXX
 SG_ DL12_DesiredLambdaBank2 : 16|8@1+ (0.0078125,0) [0|1.9921875] "Ratio" Vector__XXX
 SG_ DL12_MixAdaptationHiLoadBank2 : 24|8@1+ (0.0078125,0) [0|1.9921875] "" Vector__XXX
 SG_ DL12_MixAdaptationLoLoadBank2 : 32|8@1+ (1,0) [0|0] "" Vector__XXX
 SG_ DL12_ClosedLoopAdjFactor2 : 40|8@1+ (0.0078125,0) [0|1.9921875] "Ratio" Vector__XXX
 SG_ DL12_LambaSensorHeaterOutBank2 : 56|2@1+ (1,0) [0|3] "" Vector__XXX
 SG_ DL12_AirFuelMixStatusBank2 : 58|2@1+ (1,0) [0|3] "" Vector__XXX
 SG_ DL12_ClosedLoopMixControlBank2 : 60|2@1+ (1,0) [0|3] "" Vector__XXX

BO_ 2566909440 DataList_13_0: 8 ECM
 SG_ DL13_PortInjector1Time : 0|16@1+ (1,0) [0|65535] "us" Vector__XXX
 SG_ DL13_CaseInjector1Time : 16|16@1+ (1,0) [0|65535] "us" Vector__XXX
 SG_ DL13_Cyl1IgnTiming : 32|8@1+ (1,-125) [-125|130] "Deg-BTDC" Vector__XXX
 SG_ DL13_Cyl1BaseIgnTiming : 40|8@1+ (1,-125) [-125|130] "Deg-BTDC" Vector__XXX
 SG_ DL13_Cyl1IgnCoilDwell : 48|16@1+ (1,0) [0|65535] "us" Vector__XXX

BO_ 2566909184 DataList_14_0: 8 ECM
 SG_ DL14_PortInjector2Time : 0|16@1+ (1,0) [0|65535] "us" Vector__XXX
 SG_ DL14_CaseInjector2Time : 16|16@1+ (1,0) [0|65535] "us" Vector__XXX
 SG_ DL14_Cyl2IgnTiming : 32|8@1+ (1,-125) [-125|130] "Deg-BTDC" Vector__XXX
 SG_ DL14_Cyl2BaseIgnTiming : 40|8@1+ (1,-125) [-125|130] "Deg-BTDC" Vector__XXX
 SG_ DL14_Cyl2IgnCoilDwell : 48|16@1+ (1,0) [0|65535] "us" Vector__XXX

BO_ 2566908928 DataList_15_0: 8 ECM
 SG_ DL15_ExhaustValveSetPWM : 32|8@1+ (0.4,0) [0|102] "%" Vector__XXX
 SG_ DL15_ExhaustTemperature : 0|16@1+ (1,0) [0|65535] "°C" Vector__XXX
 SG_ DL15_InjectorIgnitionSupplyVolt : 16|8@1+ (0.1,0) [0|25.5] "V" Vector__XXX
 SG_ DL15_ElecStartOptBattVolt : 24|8@1+ (0.1,0) [0|25.5] "V" Vector__XXX

BO_ 2566908672 DataList_16_0: 8 ECM
 SG_ DL16_PedalPosSensor1 : 0|16@1+ (0.01,0) [0|655.35] "V" Vector__XXX
 SG_ DL16_PedalPosSensor2 : 16|16@1+ (0.01,0) [0|655.35] "V" Vector__XXX

BO_ 2566913024 DataList_4_0: 8 ECM
 SG_ DL4_FuelInjector1PulseWidth : 0|8@1+ (1,0) [0|255] "ms" Vector__XXX
 SG_ DL4_IgnCoil1Dwell : 8|8@1+ (0.1,0) [0|25.5] "ms" Vector__XXX
 SG_ DL4_Cyl1IgnTiming : 16|8@1+ (1,-128) [-128|127] "Deg" Vector__XXX
 SG_ DL4_Cyl1AirInjDuration : 24|8@1+ (1,0) [0|255] "ms" Vector__XXX
 SG_ DL4_FuelInjector2PulseWidth : 32|8@1+ (1,0) [0|255] "ms" Vector__XXX
 SG_ DL4_IgnCoil2Dwell : 40|8@1+ (0.1,0) [0|25.5] "ms" Vector__XXX
 SG_ DL4_Cyl2IgnTiming : 48|8@1+ (1,-128) [-128|127] "Deg" Vector__XXX
 SG_ DL4_Cyl2AirInjDuration : 56|8@1+ (1,0) [0|255] "ms" Vector__XXX

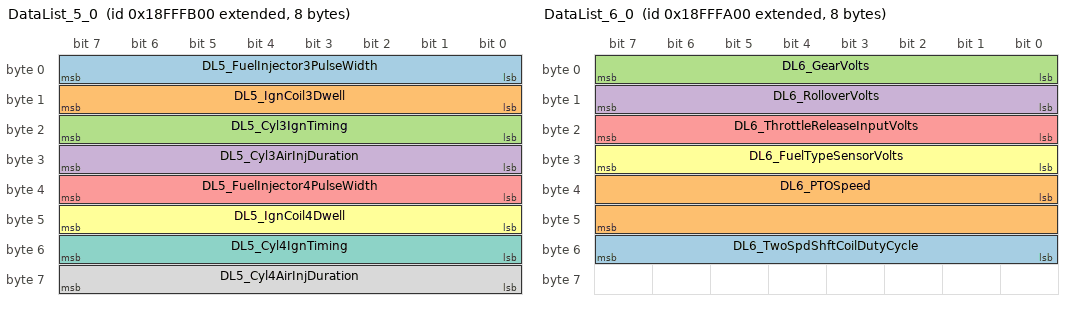
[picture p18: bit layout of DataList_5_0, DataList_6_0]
BO_ 2566912768 DataList_5_0: 8 ECM
 SG_ DL5_FuelInjector3PulseWidth : 0|8@1+ (1,0) [0|255] "ms" Vector__XXX
 SG_ DL5_IgnCoil3Dwell : 8|8@1+ (0.1,0) [0|25.5] "ms" Vector__XXX
 SG_ DL5_Cyl3IgnTiming : 16|8@1+ (1,-128) [-128|127] "Deg" Vector__XXX
 SG_ DL5_Cyl3AirInjDuration : 24|8@1+ (1,0) [0|255] "ms" Vector__XXX
 SG_ DL5_FuelInjector4PulseWidth : 32|8@1+ (1,0) [0|255] "ms" Vector__XXX
 SG_ DL5_IgnCoil4Dwell : 40|8@1+ (0.1,0) [0|25.5] "ms" Vector__XXX
 SG_ DL5_Cyl4IgnTiming : 48|8@1+ (1,-128) [-128|127] "Deg" Vector__XXX
 SG_ DL5_Cyl4AirInjDuration : 56|8@1+ (1,0) [0|255] "ms" Vector__XXX

BO_ 2566912512 DataList_6_0: 8 ECM
 SG_ DL6_TwoSpdShftCoilDutyCycle : 48|8@1+ (0.4,0) [0|100] "%" Vector__XXX
 SG_ DL6_PTOSpeed : 32|16@1+ (1,0) [0|65535] "RPM" Vector__XXX
 SG_ DL6_GearVolts : 0|8@1+ (0.1,0) [0|25.5] "V" Vector__XXX
 SG_ DL6_RolloverVolts : 8|8@1+ (0.025,0) [0|6.375] "V" Vector__XXX
 SG_ DL6_ThrottleReleaseInputVolts : 16|8@1+ (0.1,0) [0|25.5] "V" Vector__XXX
 SG_ DL6_FuelTypeSensorVolts : 24|8@1+ (0.1,0) [0|25.5] "V" Vector__XXX

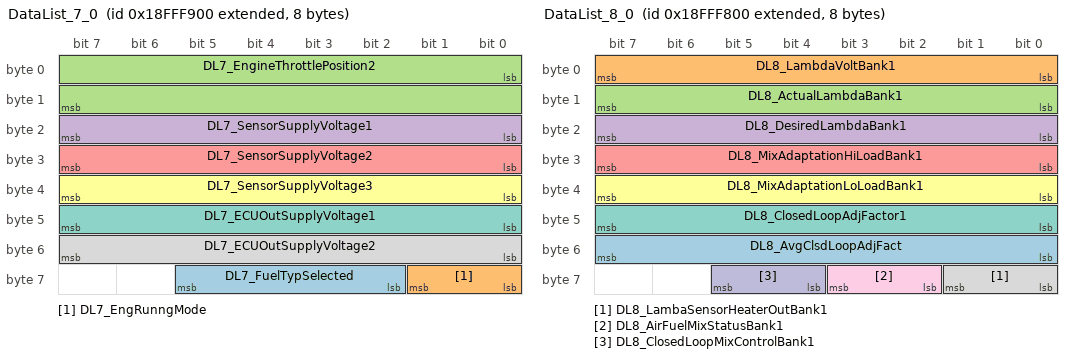
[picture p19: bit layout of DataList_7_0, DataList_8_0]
BO_ 2566912256 DataList_7_0: 8 ECM
 SG_ DL7_FuelTypSelected : 58|4@1+ (1,0) [0|15] "" Vector__XXX
 SG_ DL7_EngRunngMode : 56|2@1- (1,0) [0|3] "" Vector__XXX
 SG_ DL7_EngineThrottlePosition2 : 0|16@1+ (0.01,0) [0|655.35] "V" Vector__XXX
 SG_ DL7_SensorSupplyVoltage1 : 16|8@1+ (0.05,0) [0|12.75] "V" Vector__XXX
 SG_ DL7_SensorSupplyVoltage2 : 24|8@1+ (0.05,0) [0|12.75] "V" Vector__XXX
 SG_ DL7_SensorSupplyVoltage3 : 32|8@1+ (0.05,0) [0|12.75] "V" Vector__XXX
 SG_ DL7_ECUOutSupplyVoltage1 : 40|8@1+ (0.05,0) [0|12.75] "V" Vector__XXX
 SG_ DL7_ECUOutSupplyVoltage2 : 48|8@1+ (0.05,0) [0|12.75] "V" Vector__XXX

BO_ 2566912000 DataList_8_0: 8 ECM
 SG_ DL8_AvgClsdLoopAdjFact : 48|8@1+ (0.0078125,0) [0|1.9921875] "Ratio" Vector__XXX
 SG_ DL8_LambdaVoltBank1 : 0|8@1+ (0.02,0) [0|5.1] "" Vector__XXX
 SG_ DL8_ActualLambdaBank1 : 8|8@1+ (0.0078125,0) [0|1.9921875] "Ratio" Vector__XXX
 SG_ DL8_DesiredLambdaBank1 : 16|8@1+ (0.0078125,0) [0|1.9921875] "Ratio" Vector__XXX
 SG_ DL8_MixAdaptationHiLoadBank1 : 24|8@1+ (0.0078125,0) [0|1.9921875] "" Vector__XXX
 SG_ DL8_MixAdaptationLoLoadBank1 : 32|8@1+ (0.0078125,0) [0|1.9921875] "" Vector__XXX
 SG_ DL8_ClosedLoopAdjFactor1 : 40|8@1+ (0.0078125,0) [0|1.9921875] "Ratio" Vector__XXX
 SG_ DL8_LambaSensorHeaterOutBank1 : 56|2@1+ (1,0) [0|3] "" Vector__XXX
 SG_ DL8_AirFuelMixStatusBank1 : 58|2@1+ (1,0) [0|3] "" Vector__XXX
 SG_ DL8_ClosedLoopMixControlBank1 : 60|2@1+ (1,0) [0|3] "" Vector__XXX

BO_ 2566911232 FlagItems_1_0: 8 ECM
 SG_ FI1_IntercoolerPumpDriverCircuit : 46|2@1+ (1,0) [0|3] "" Vector__XXX
 SG_ FI1_FuelPullSolenoidStatus : 60|2@1+ (1,0) [0|3] "" Vector__XXX
 SG_ FI1_ClutchSwitchInput2 : 62|2@1+ (1,0) [0|3] "" Vector__XXX
 SG_ FI1_FuelPumpDriverCkt : 0|2@1+ (1,0) [0|3] "" Vector__XXX
 SG_ FI1_RolloverSwitch : 2|2@1+ (1,0) [0|3] "" Vector__XXX
 SG_ FI1_CrankSensorSignal : 4|2@1+ (1,0) [0|3] "" Vector__XXX
 SG_ FI1_CamSensorSignal : 6|2@1+ (1,0) [0|3] "" Vector__XXX
 SG_ FI1_RPMLimitActive : 8|2@1+ (1,0) [0|3] "" Vector__XXX
 SG_ FI1_IdleSwitch : 10|2@1+ (1,0) [0|3] "" Vector__XXX
 SG_ FI1_CycleSynchro : 12|2@1+ (1,0) [0|3] "" Vector__XXX
 SG_ FI1_IdleSpeedControlStatus : 14|2@1+ (1,0) [0|3] "" Vector__XXX
 SG_ FI1_IgnitionSwitchInput : 16|2@1+ (1,0) [0|3] "" Vector__XXX
 SG_ FI1_RunStopSwitchInput : 18|2@1+ (1,0) [0|3] "" Vector__XXX
 SG_ FI1_StartSwitchInput : 20|2@1+ (1,0) [0|3] "" Vector__XXX
 SG_ FI1_ThrottleSafetySwInput : 22|2@1+ (1,0) [0|3] "" Vector__XXX
 SG_ FI1_FanRelayOutput : 24|2@1+ (1,0) [0|3] "" Vector__XXX
 SG_ FI1_IntercoolerFanOutput : 26|2@1+ (1,0) [0|3] "" Vector__XXX
 SG_ FI1_ReverseAlarmOutput : 28|2@1+ (1,0) [0|3] "" Vector__XXX
 SG_ FI1_MainRelayOutput : 30|2@1+ (1,0) [0|3] "" Vector__XXX
 SG_ FI1_StartSolenoidOutput : 32|2@1+ (1,0) [0|3] "" Vector__XXX
 SG_ FI1_IgnitionRelayOutput : 34|2@1+ (1,0) [0|3] "" Vector__XXX
 SG_ FI1_ChassisRelayOutput : 36|2@1+ (1,0) [0|3] "" Vector__XXX
 SG_ FI1_StarterEnableOutput : 38|2@1+ (1,0) [0|3] "" Vector__XXX
 SG_ FI1_ExhaustValveOutput : 40|2@1+ (1,0) [0|3] "" Vector__XXX
 SG_ FI1_BatteryChargeRelayOutput : 42|2@1+ (1,0) [0|3] "" Vector__XXX
 SG_ FI1_HeaterAccRelay : 44|2@1+ (1,0) [0|3] "" Vector__XXX
 SG_ FI1_ClutchSwitchInput : 56|2@1+ (1,0) [0|3] "" Vector__XXX
 SG_ FI1_MILLampOutput : 48|2@1+ (1,0) [0|3] "" Vector__XXX
 SG_ FI1_OverTempLampOutput : 50|2@1+ (1,0) [0|3] "" Vector__XXX
 SG_ FI1_KnockDetLampOutput : 52|2@1+ (1,0) [0|3] "" Vector__XXX
 SG_ FI1_ElecOilPumpDrvrCirc : 58|2@1+ (1,0) [0|3] "" Vector__XXX

CM_ BO_ 2565799548 "Used to claim an address by a module.";
CM_ BO_ 2565799544 "Used to claim an address by a module.";
CM_ BO_ 2565799673 "Used to claim an address by a module.";
CM_ SG_ 2231309056 pEPCU_1_Speed_Limit "Checksum ensures data is valid before use.";
CM_ SG_ 2231309056 pEPCU_1_Counter_Torque_Limit "Checksum ensures data is valid before use.";
CM_ SG_ 2231309056 pEPCU_1_Torque_Demand "Checksum ensures data is valid before use.";
CM_ SG_ 2231309056 pEPCU_1_Control_Mode "Checksum ensures data is valid before use.";
CM_ SG_ 2231309056 pEPCU_1_Message_Counter "Checksum ensures data is valid before use.";
CM_ SG_ 2231309056 pEPCU_1_Checksum "Checksum ensures data is valid before use.";
CM_ BO_ 2565799471 "Used to claim an address by a module.";
CM_ SG_ 2566887215 pVehicleEventStatusCornering "Vehicle cornering event detection status.";
CM_ SG_ 2566887215 pVehicleEventStatusBraking "Vehicle braking event detection status.";
CM_ SG_ 2566887215 pVehicleEventStatusAirborne "Vehicle airborne event detection status.";
CM_ SG_ 2566887215 pVehicleEventStatusAccel "Vehicle airborne event detection status.";
CM_ SG_ 2566887215 pSuspensionModeActive "Indicates which suspension mode is active.";
CM_ SG_ 2566887215 pSuspensionDampingPercentRR "The calculated percent of full damping range commanded to the rear right shock.";
CM_ SG_ 2566887215 pSuspensionDampingPercentRL "The calculated percent of full damping range commanded to the rear left shock.";
CM_ SG_ 2566887215 pSuspensionDampingPercentFL "The calculated percent of full damping range commanded to the front left shock.";
CM_ BO_ 2432656705 "Indicates the status of multiple operator controlled switches.";
CM_ SG_ 2432656705 pOperatorButton29 "Drive Mode - 1()";
CM_ SG_ 2432656705 pOperatorButton1 "Instrument Cluster Control - 1";
CM_ SG_ 2432656705 pOperatorButton2 "Instrument Cluster Control  - 2";
CM_ SG_ 2432656705 pOperatorButton3 "Headlamp - 1 (Low)";
CM_ SG_ 2432656705 pOperatorButton4 "Headlamp - 2 (High)";
CM_ SG_ 2432656705 pOperatorButton5 "Headlamp - 3 (Driving)";
CM_ SG_ 2432656705 pOperatorButton6 "Turn - 1 (Left)";
CM_ SG_ 2432656705 pOperatorButton7 "Turn - 2 (Right)";
CM_ SG_ 2432656705 pOperatorButton8 "Turn - 3 (Cancel)";
CM_ SG_ 2432656705 pOperatorButton9 "Hazard";
CM_ SG_ 2432656705 pOperatorButton10 "Cruise - 1 (On)";
CM_ SG_ 2432656705 pOperatorButton11 "Cruise - 2 (Set)";
CM_ SG_ 2432656705 pOperatorButton12 "Cruise - 3 (Accel)";
CM_ SG_ 2432656705 pOperatorButton13 "Horn";
CM_ SG_ 2432656705 pOperatorButton14 "Start";
CM_ SG_ 2432656705 pOperatorButton15 "Warmer - 1";
CM_ SG_ 2432656705 pOperatorButton16 "Warmer - 2";
CM_ SG_ 2432656705 pOperatorButton17 "Warmer - 3";
CM_ SG_ 2432656705 pOperatorButton18 "Warmer - 4";
CM_ SG_ 2432656705 pOperatorButton19 "Windshield Wiper";
CM_ SG_ 2432656705 pOperatorButton20 "Engine On";
CM_ SG_ 2432656705 pOperatorButton21 "Reverse";
CM_ SG_ 2432656705 pOperatorButton22 "Homelink 1";
CM_ SG_ 2432656705 pOperatorButton23 "Homelink 2";
CM_ SG_ 2432656705 pOperatorButton24 "Throttle Safety Switch - 1";
CM_ SG_ 2432656705 pOperatorButton25 "Windshield - 1 (Up)";
CM_ SG_ 2432656705 pOperatorButton26 "Windshield - 2 (Down)";
CM_ SG_ 2432656705 pOperatorButton27 "Hand Brake Switch";
CM_ SG_ 2432656705 pOperatorButton28 "Clutch Switch";
CM_ SG_ 2432656705 pSideStandStatus "Status of the side stand switch of a motorcycle";
CM_ SG_ 2365523591 pModCtlCmdState "The commanded control mode that the EPS unit will operate in";
CM_ SG_ 2365523590 pModCtlCmdState "The commanded control mode that the EPS unit will operate in";
CM_ BO_ 2566844807 "Cruise Control Status and Vehicle Speed Information";
CM_ SG_ 2566844807 pCruiseCntrlCounter "Rolling Counter (ensures updated message is used).";
CM_ SG_ 2566844807 TwoSpeedAxleSwitch "Switch signal which indicates the current axle range.";
CM_ SG_ 2566844807 ParkingBrakeSwitch "Switch signal which indicates when the parking brake is set. In general the switch actuated by the operator's park brake control,
whether a pedal, lever, or other control mechanism.";
CM_ SG_ 2566844807 Wheel_BasedVehicleSpeed "Speed of the vehicle as calculated from wheel or tailshaft speed.";
CM_ SG_ 2566844807 CruiseCtrlActive "Cruise control is switched on.  It is not ensured that the engine is controlled by cruise control, as in the case of a large driver's demand the engine is controlled by the driver while
cruise control is active.";
CM_ SG_ 2566844807 CruiseCtrlEnableSwitch "Switch signal which indicates that it is possible to manage the cruise control function";
CM_ SG_ 2566844807 BrakeSwitch "Switch signal which indicates that the driver operated brake foot pedal is being pressed";
CM_ SG_ 2566844807 ClutchSwitch "Switch signal which indicates that the clutch pedal is being pressed.  It is necessary for a safe drivetrain behavior that the clutch switch is set before the clutch is opened (cruise control function).";
CM_ SG_ 2566844807 CruiseCtrlSetSwitch "Switch signal of the cruise control activator which indicates that the activator is in the position 'set'.";
CM_ SG_ 2566844807 CruiseCtrlCoastSwitch "Switch signal of the cruise control activator which indicates that the activator is in the position 'coast'";
CM_ SG_ 2566844807 CruiseCtrlResumeSwitch "Switch signal of the cruise control activator which indicates that the activator is in the position 'resume'";
CM_ SG_ 2566844807 CruiseCtrlAccelerateSwitch "Switch signal of the cruise control activator which indicates that the activator is in the position 'accelerate'";
CM_ SG_ 2566844807 CruiseCtrlSetSpeed "Value of set (chosen) velocity of velocity control system.";
CM_ SG_ 2566844807 pOdometerDriveBit "Alternate state (A->B, B->A) each time the vehicle has moved a defined distance (currently 40m).";
CM_ SG_ 2566844807 CruiseCtrlPauseSw "Switch signal which indicates the positon of the Cruise Control Pause Switch used on Remote Cruise Control applications. The Cruise Control Pause Switch signal temporarily
disables the Cruise Control function.";
CM_ SG_ 2566844807 pCCChecksum "XOR of bytes 0-6 (ensures data is valid before use)";
CM_ SG_ 2566844807 pCruiseEnableStatus "The Cruise Control System has been enabled by the operator.  (Amber Light)";
CM_ SG_ 2365523495 pModCtlCmdState "The commanded control mode that the EPS unit will operate in";
CM_ BO_ 2563833511 "This message contains information that controls illumination devices inside the vehicle's cab.";
CM_ SG_ 2563833511 IlluminationBrightnessPercent "Commanded backlight brightness level for all cab displays.";
CM_ SG_ 2563833511 SwitchBacklightIlluminPercent "Commanded switch backlight brightness level for all operator control switches. This is separate from the cab display
illumination Brightness Percent parameter.";
CM_ SG_ 2566847655 WasherFluidLevel "Not approved for use at Polaris at this time.";
CM_ SG_ 2566847655 FuelLevel "Ratio of volume of fuel to the total volume of fuel storage container.";
CM_ SG_ 2566847655 FuelFilterDiffPressure "Not approved for use at Polaris at this time.";
CM_ SG_ 2566847655 EngineOilFilterDiffPressure "Not approved for use at Polaris at this time.";
CM_ SG_ 2566847655 CargoAmbientTemperature "Not approved for use at Polaris at this time.";
CM_ BO_ 2566834727 "Active diagnostic trouble codes";
CM_ SG_ 2566834727 DTC5 "Diagnostic Trouble Code";
CM_ SG_ 2566834727 DTC4 "Diagnostic Trouble Code";
CM_ SG_ 2566834727 DTC3 "Diagnostic Trouble Code";
CM_ SG_ 2566834727 DTC2 "Diagnostic Trouble Code";
CM_ SG_ 2566834727 DTC1 "Diagnostic Trouble Code";
CM_ SG_ 2566834727 DM_FlashRedStopLamp "Flash status of the Red Stop Lamp";
CM_ SG_ 2566834727 DM_FlashProtectLamp "Flash status of the Stop Protect Lamp";
CM_ SG_ 2566834727 DM_FlashMalfuncIndicatorLamp "Flash status of the Malfunction Indicator Lamp";
CM_ SG_ 2566834727 DM_FlashAmberWarningLamp "Flash status of the Amber Warning Lamp";
CM_ SG_ 2566834727 DM_ProtectLampStatus "This lamp is used to relay trouble code informatio that is reporting a problem with a vehicle system that is most
probably not electronic subsystem related.";
CM_ SG_ 2566834727 DM_RedStopLampState "This lamp is uesed to relay trouble code information that is of a severe enought condition that it warrants stopping the vehicle.";
CM_ SG_ 2566834727 DM_AmberWrningLmpStatus "This lamp is used to relay trouble code information that is reporting a problem with the vehicle system but the vehicle need
not be immediately stopped.";
CM_ SG_ 2566834727 DM_MalfuncnIndicatorLampStatus "A lamp used to relay only emissions-related trouble code information.";
CM_ BO_ 2566832449 "High Resolution Vehicle and Trip 1 distance";
CM_ SG_ 2566832449 HighResolTotalVehicleDistance "Accumulated distance traveled by the vehicle during its operation";
CM_ SG_ 2566832449 HighResolTripDistance "Distance traveled during all or part of a journey";
CM_ BO_ 2365473063 "The lighting command message has been defined as a global message from the vehicle to all lighting controllers on the
tractor and attached implements.";
CM_ SG_ 2365473063 LowBeamHeadlightCommand "Command to activate or de-activate the tractor low beam head light lamps.";
CM_ SG_ 2365473063 HighBeamHeadlightCommand "Command to activate or de-activate the tractor high beam head light lamps.";
CM_ SG_ 2365473063 LeftTurnSigLightsCommand "Command to activate or de-activate left turn signal lights";
CM_ SG_ 2365473063 RightTurnSigLightsCommand "Command to activate or de-activate right turn signal lights on the tractor and all connected implements";
CM_ BO_ 2633883431 "Front wheel drive ECU information.";
CM_ SG_ 2633883431 FrtWheelDriveActuatorStatus "Feedback on the front wheel drive actuator.";
CM_ BO_ 2566877479 "Instrument Cluster Information";
CM_ SG_ 2566877479 pVolumeUnitsSelected "Active display volume units beased on user selection or auto-configuration.";
CM_ SG_ 2566877479 pTimeUnitsSelected "Active display time units beased on user selection or auto-configuration.";
CM_ SG_ 2566877479 pTemperatureUnitsSelected "Active display temperature units beased on user selection or auto-configuration.";
CM_ SG_ 2566877479 pPressureUnitsSelected "Active display pressure units beased on user selection or auto-configuration.";
CM_ SG_ 2566877479 pHighResTrip2Distance "Secondary distance travled during all or part of a journey.";
CM_ SG_ 2566877479 pDistanceUnitsSelected "Active display distance units beased on user selection or auto-configuration.";
CM_ SG_ 2566877479 pTPMSLearningStatus "Status of the Tire Pressure Monitor System learning process.";
CM_ SG_ 2566877479 pDisplayStatus "Status of the radio display to the radio stating what the display is showing";
CM_ SG_ 2566887168 pVehicleEventStatusCornering "Vehicle cornering event detection status.";
CM_ SG_ 2566887168 pVehicleEventStatusBraking "Vehicle braking event detection status.";
CM_ SG_ 2566887168 pVehicleEventStatusAirborne "Vehicle airborne event detection status.";
CM_ SG_ 2566887168 pVehicleEventStatusAccel "Vehicle airborne event detection status.";
CM_ SG_ 2566887168 pSuspensionModeActive "Indicates which suspension mode is active.";
CM_ SG_ 2566887168 pSuspensionDampingPercentRR "The calculated percent of full damping range commanded to the rear right shock.";
CM_ SG_ 2566887168 pSuspensionDampingPercentRL "The calculated percent of full damping range commanded to the rear left shock.";
CM_ SG_ 2566887168 pSuspensionDampingPercentFL "The calculated percent of full damping range commanded to the front left shock.";
CM_ BO_ 2431708455 "Electronic engine controller #1";
CM_ SG_ 2431708455 MessageCounter_EngStartCtl "Message counter to allow detection of data integrity issues.";
CM_ SG_ 2431708455 MessageChecksum_EngStartCtl "The message checksum is used to verify the signal path from the transmitting device to the receiving device.";
CM_ SG_ 2431708455 EngineStarter2Feedback "There are several phases in a starting action and different reasons why a start cannot take place.";
CM_ SG_ 2431708455 EngineStarter1Feedback "There are several phases in a starting action and different reasons why a start cannot take place.";
CM_ SG_ 2431708455 EngineStartAbortReq "Indicates the sender’s desire to abort an engine start.";
CM_ SG_ 2431708455 TransShiftSelectRequVehDir "This parameter indicates the direction selected by the operator via the active transmission shift selector.";
CM_ SG_ 2431708455 EngineStartReq "Indicates the sender’s desire to start the engine.";
CM_ SG_ 2431708455 EngineStartConsent "Indicates the sender’s consent to start the engine for different start types.";
CM_ BO_ 2297441583 "The acceleration sensor message shall provide a measurement of the vehicle’s acceleration in the lateral, longitudinal, and vertical axes.";
CM_ BO_ 2432656774 "Indicates the status of multiple operator controlled switches.";
CM_ SG_ 2432656774 pOperatorButton29 "Drive Mode - 1()";
CM_ SG_ 2432656774 pOperatorButton1 "Instrument Cluster Control - 1";
CM_ SG_ 2432656774 pOperatorButton2 "Instrument Cluster Control  - 2";
CM_ SG_ 2432656774 pOperatorButton3 "Headlamp - 1 (Low)";
CM_ SG_ 2432656774 pOperatorButton4 "Headlamp - 2 (High)";
CM_ SG_ 2432656774 pOperatorButton5 "Headlamp - 3 (Driving)";
CM_ SG_ 2432656774 pOperatorButton6 "Turn - 1 (Left)";
CM_ SG_ 2432656774 pOperatorButton7 "Turn - 2 (Right)";
CM_ SG_ 2432656774 pOperatorButton8 "Turn - 3 (Cancel)";
CM_ SG_ 2432656774 pOperatorButton9 "Hazard";
CM_ SG_ 2432656774 pOperatorButton10 "Cruise - 1 (On)";
CM_ SG_ 2432656774 pOperatorButton11 "Cruise - 2 (Set)";
CM_ SG_ 2432656774 pOperatorButton12 "Cruise - 3 (Accel)";
CM_ SG_ 2432656774 pOperatorButton13 "Horn";
CM_ SG_ 2432656774 pOperatorButton14 "Start";
CM_ SG_ 2432656774 pOperatorButton15 "Warmer - 1";
CM_ SG_ 2432656774 pOperatorButton16 "Warmer - 2";
CM_ SG_ 2432656774 pOperatorButton17 "Warmer - 3";
CM_ SG_ 2432656774 pOperatorButton18 "Warmer - 4";
CM_ SG_ 2432656774 pOperatorButton19 "Windshield Wiper";
CM_ SG_ 2432656774 pOperatorButton20 "Engine On";
CM_ SG_ 2432656774 pOperatorButton21 "Reverse";
CM_ SG_ 2432656774 pOperatorButton22 "Homelink 1";
CM_ SG_ 2432656774 pOperatorButton23 "Homelink 2";
CM_ SG_ 2432656774 pOperatorButton24 "Throttle Safety Switch - 1";
CM_ SG_ 2432656774 pOperatorButton25 "Windshield - 1 (Up)";
CM_ SG_ 2432656774 pOperatorButton26 "Windshield - 2 (Down)";
CM_ SG_ 2432656774 pOperatorButton27 "Hand Brake Switch";
CM_ SG_ 2432656774 pOperatorButton28 "Clutch Switch";
CM_ SG_ 2432656774 pSideStandStatus "Status of the side stand switch of a motorcycle";
CM_ BO_ 2565799489 "Used to claim an address by a module.";
CM_ BO_ 2565799453 "Used to claim an address by a module.";
CM_ BO_ 2565799447 "Used to claim an address by a module.";
CM_ BO_ 2565799443 "Used to claim an address by a module.";
CM_ BO_ 2565799435 "Used to claim an address by a module.";
CM_ BO_ 2565799424 "Used to claim an address by a module.";
CM_ BO_ 2631794205 "Used by the interface device to lock or unlock the lockabe/unlockable device.";
CM_ SG_ 2631794205 EncryptionIndicatorStates "This parameter is used to indicate if a random number of seed is being requested, or if an encrypted password is being provided
to the component.";
CM_ SG_ 2631794205 AntiTheftDesiredExitModeStates "This parameter is used to specify the desired triggers that are to be used by the component  in deciding when
to transition to the locked states.";
CM_ SG_ 2631794205 AntiTheftCommandStates "This parameter is used to identify the specific requests being sent to the component.";
CM_ SG_ 2631794205 AntiTheftPasswordRepresentation "This parameter is the 7-byte numeric code that is generated based on the encryption algorithm,
the password supplied by the end user, and the random number seed giben by the component.
";
CM_ BO_ 2631794199 "Used by the interface device to lock or unlock the lockabe/unlockable device.";
CM_ SG_ 2631794199 EncryptionIndicatorStates "This parameter is used to indicate if a random number of seed is being requested, or if an encrypted password is being provided
to the component.";
CM_ SG_ 2631794199 AntiTheftDesiredExitModeStates "This parameter is used to specify the desired triggers that are to be used by the component  in deciding when
to transition to the locked states.";
CM_ SG_ 2631794199 AntiTheftCommandStates "This parameter is used to identify the specific requests being sent to the component.";
CM_ SG_ 2631794199 AntiTheftPasswordRepresentation "This parameter is the 7-byte numeric code that is generated based on the encryption algorithm,
the password supplied by the end user, and the random number seed giben by the component.
";
CM_ BO_ 2631728640 "Used by the device to be locked/unlocked to communicate status and lock/unlock the device.";
CM_ SG_ 2631728640 AntiTheftEncryptSeedPresentInd "Indicates the presence of the encryption seed random number.";
CM_ SG_ 2631728640 AntiTheftPasswordValidIndicator "Indicates the presence of a validated password.";
CM_ SG_ 2631728640 AntiTheftModifyPasswordStates "This parameter is used to indicate whether a password request was successfully performed, or if the
request could not be perform due to system constraints or if the request was not a valid request.";
CM_ SG_ 2631728640 AntiTheftRandomNumber "A 7-byte random numeric code provieded by the component in response to an anti-theft request.";
CM_ SG_ 2631728640 AntiTheftComponentStatusInd "Indicates wheter or not the component can be started.";
CM_ BO_ 2561212031 "Text Display";
CM_ SG_ 2561212031 TextDisplayInstructions "This parameter describes the status for the display how to show the information.";
CM_ SG_ 2561212031 TextDisplayCharacter "From 1 up to 200 characters to be presented on a display. Up to 4 characters can be displayed without using Transport
Protocol.";
CM_ SG_ 2561212031 TextDisplayIndex "Used for overwriting consecutive bytes of a displayed string when byte 1 Text Display Instructions state is set for
overwrite substring mode.";
CM_ BO_ 2566844160 "Engine Fluid Pressures and Levels";
CM_ SG_ 2566844160 FuelDeliveryPressure "Not approved for use at Polaris at this time.";
CM_ SG_ 2566844160 EngineOilLevel "Ratio of current volume of engine sump oil to maximum required volume.";
CM_ SG_ 2566844160 EngineOilPressure "Gauge pressure of the oil in the engine lubrication system as provided by the oil pump.";
CM_ SG_ 2566844160 EngineCrankcasePressure "Gauge pressure inside engine crankcase.";
CM_ SG_ 2566844160 EngineCoolantPressure "Gauge pressure of liquid found in engine cooling system.";
CM_ SG_ 2566844160 EngineCoolantLevel "Ratio of volume of liquid found in engine cooling system to total cooling system volume. Typical monitoring locatin is in the coolant expansion tank.";
CM_ SG_ 2566844160 ExtCrankcaseBlowByPressure "Not approved for use at Polaris at this time.

(Differential crankcase blow-by pressure as measured through a tube with a venturi.)";
CM_ BO_ 2432658432 "Indicates the status of multiple operator controlled switches.";
CM_ SG_ 2432658432 pOperatorButton42 "Momentary Driveline Right Press";
CM_ SG_ 2432658432 pOperatorButton41 "Momentary Driveline Left Press";
CM_ SG_ 2432658432 pOperatorButton39 "Work Mode Switch Status";
CM_ SG_ 2432658432 pOperatorButton37 "Work Group Switch Status";
CM_ SG_ 2432658432 pOperatorButton36 "Tilt Lock Switch Status";
CM_ SG_ 2432658432 pFOCCMessageCounter "Rolling Counter (ensures updated message is used).";
CM_ SG_ 2432658432 pFOCCChecksum "XOR of bytes 0-6 (ensures data is valid before use). ";
CM_ SG_ 2432658432 pOperatorButton40 "Foot On Cruise Control Switch";
CM_ SG_ 2432658432 pOperatorButton38 "Operator Present Switch";
CM_ SG_ 2432658432 pOperatorButton35 "Driver's Net Engagement";
CM_ SG_ 2432658432 pOperatorButton34 "Driver's Seatbelt Engagement";
CM_ SG_ 2432658432 pOperatorButton33 "PTO Mode Switch (RPM control)";
CM_ SG_ 2432658432 pOperatorButton32 "Drive Mode - 4()";
CM_ SG_ 2432658432 pOperatorButton31 "Drive Mode - 3()";
CM_ SG_ 2432658432 pOperatorButton30 "Drive Mode - 2()";
CM_ SG_ 2432658432 pOperatorButton29 "Drive Mode - 1()";
CM_ BO_ 2633984512 "Status of Drive System Information";
CM_ SG_ 2633984512 pHeatedGripEnable "Indicates if the controller broadcasting this SPN is calibrated to support vehicle speed limit 3";
CM_ SG_ 2633984512 pSideStandStatus "Status of the side stand switch of a motorcycle";
CM_ SG_ 2633984512 pTetherSwitchStatus "Status of the Tether Switch";
CM_ SG_ 2633984512 pLowFuelIndicatorStatus "Broadcasting the status of the fuel level for user indication.";
CM_ SG_ 2633984512 pOperatorNotInOperatingStation "Status of Operator presence in a vehicle";
CM_ SG_ 2633984512 pParkBrakeIndicatorStatus "Broadcasting the status of the park brake for user indication";
CM_ SG_ 2633984512 pADCRequested "Broadcasting the status of the users request for ADC mode";
CM_ SG_ 2633984512 pAWDModeRequested "Broadcasting the status of the users request for AWD mode";
CM_ SG_ 2633984512 pRWDModeRequested "Broadcasting the status of the users request for RWD mode";
CM_ SG_ 2633984512 pTurfModeRequested "Broadcasting the status of the users request for TURF mode";
CM_ SG_ 2633984512 pADCStatus "Broadcasting the status of the ADC (active indicates the solenoid is powered)";
CM_ SG_ 2633984512 pTreadleNeutralStatus "Broadcasting the status of the switch indicating the treadle is/is not in the Neutral position";
CM_ SG_ 2633984512 pTreadleReverseStatus "Broadcasting the status of the switch indicating the treadle is/is not in the Reverse position";
CM_ SG_ 2633984512 pSecurityLightStatus "Broadcasting the status of the security system for user indication";
CM_ SG_ 2633984512 pHighBeamIndicatorStatus "Broadcasting the status of the high beam headlight for user indication";
CM_ SG_ 2633984512 pHeatedGripsPercentage "Heated Grips Percent On, 0% is Off and 100% is the maximum heat";
CM_ SG_ 2633984512 pCruiseControlSetStatus "Broadcasting the status of the Cruise Control Set Status for user indication";
CM_ SG_ 2633984512 pSeatBeltIndicatorStatus "Broadcasting the status of the seat belt for user indication";
CM_ SG_ 2566847511 WasherFluidLevel "Not approved for use at Polaris at this time.";
CM_ SG_ 2566847511 FuelLevel "Ratio of volume of fuel to the total volume of fuel storage container.";
CM_ SG_ 2566847511 FuelFilterDiffPressure "Not approved for use at Polaris at this time.";
CM_ SG_ 2566847511 EngineOilFilterDiffPressure "Not approved for use at Polaris at this time.";
CM_ SG_ 2566847511 CargoAmbientTemperature "Not approved for use at Polaris at this time.";
CM_ SG_ 2566845719 CabInteriorTemperature "Not approved for use at Polaris at this time.";
CM_ SG_ 2566845719 AmbientAirTemperature "Temperature of air surrounding vehicle.";
CM_ SG_ 2566845719 EngineAirInletTemperature "Temperature of air entering vehicle air induction system.";
CM_ SG_ 2566845719 RoadSurfaceTemperature "Indicated temperature of road surface over which the vehicle is operating.";
CM_ SG_ 2566847488 WasherFluidLevel "Not approved for use at Polaris at this time.";
CM_ SG_ 2566847488 FuelLevel "Ratio of volume of fuel to the total volume of fuel storage container.";
CM_ SG_ 2566847488 FuelFilterDiffPressure "Not approved for use at Polaris at this time.";
CM_ SG_ 2566847488 EngineOilFilterDiffPressure "Not approved for use at Polaris at this time.";
CM_ SG_ 2566847488 CargoAmbientTemperature "Not approved for use at Polaris at this time.";
CM_ BO_ 2565867008 "Electronic Axle Controller 1";
CM_ SG_ 2565867008 Location "To identify to which of several similar devices the information applies";
CM_ SG_ 2565867008 DifferentialLockFrontAxle1 "State used which indicates the condition of the front axle 1 differential lock. The differential locks are located as defined in firuge SPN564_A.";
CM_ SG_ 2565867008 DifferentialLockFrontAxle2 "Not approved for use at Polaris at this time.";
CM_ SG_ 2565867008 DifferentialLockRearAxle1 "Sate used which indicates the condition of the rear axle 1 differential lock. The differential locks are located as defined in figure SPN 564_A.";
CM_ SG_ 2565867008 DifferentialLockRearAxle2 "Not approved for use at Polaris at this time.";
CM_ SG_ 2565867008 DifferentialCentral "State used which indicates the condition of the central differential lock. The differential locks are located as defined in attached figure SPN564_A.";
CM_ SG_ 2565867008 DifferentialCentralFront "Not approved for use at Polaris at this time.";
CM_ SG_ 2565867008 DifferentialCentralRear "Not approved for use at Polaris at this time.";
CM_ SG_ 2566841600 EngTotalHoursOfOper "Accumulated time of operation of engine";
CM_ SG_ 2566841600 TotalEngineRevolutions "(Accumulated number of revolutions of engine crankshaft during its operation)";
CM_ SG_ 2566832407 HighResolTotalVehicleDistance "Accumulated distance traveled by the vehicle during its operation";
CM_ SG_ 2566832407 HighResolTripDistance "Distance traveled during all or part of a journey";
CM_ BO_ 2566834688 "Active diagnostic trouble codes";
CM_ SG_ 2566834688 DM_ProtectLampStatus "This lamp is used to relay trouble code informatio that is reporting a problem with a vehicle system that is most
probably not electronic subsystem related.";
CM_ SG_ 2566834688 DM_RedStopLampState "This lamp is uesed to relay trouble code information that is of a severe enought condition that it warrants stopping the vehicle.";
CM_ SG_ 2566834688 DM_AmberWrningLmpStatus "This lamp is used to relay trouble code information that is reporting a problem with the vehicle system but the vehicle need
not be immediately stopped.";
CM_ SG_ 2566834688 DM_MalfuncnIndicatorLampStatus "A lamp used to relay only emissions-related trouble code information.";
CM_ SG_ 2566834688 DM_FlashRedStopLamp "Flash status of the Red Stop Lamp";
CM_ SG_ 2566834688 DM_FlashMalfuncIndicatorLamp "Flash status of the Malfunction Indicator Lamp";
CM_ SG_ 2566834688 DTC5 "Diagnostic Trouble Code";
CM_ SG_ 2566834688 DTC4 "Diagnostic Trouble Code";
CM_ SG_ 2566834688 DTC3 "Diagnostic Trouble Code";
CM_ SG_ 2566834688 DTC2 "Diagnostic Trouble Code";
CM_ SG_ 2566834688 DTC1 "Diagnostic Trouble Code";
CM_ SG_ 2566834688 DM_FlashProtectLamp "Flash status of the Stop Protect Lamp";
CM_ SG_ 2566834688 DM_FlashAmberWarningLamp "Flash status of the Amber Warning Lamp";
CM_ BO_ 2564423168 "Memory Access Request";
CM_ SG_ 2564423168 DM_NumberRequested "Length/Number Requested";
CM_ SG_ 2564423168 DM_UserLevel "Key/User Level";
CM_ BO_ 2564356352 "Memory Access Response / Output State Control";
CM_ BO_ 2633883392 "Front wheel drive ECU information.";
CM_ SG_ 2633883392 FrtWheelDriveActuatorStatus "Feedback on the front wheel drive actuator.";
CM_ BO_ 2432656640 "Indicates the status of multiple operator controlled switches.";
CM_ SG_ 2432656640 pOperatorButton29 "Drive Mode - 1()";
CM_ SG_ 2432656640 pOperatorButton1 "Instrument Cluster Control - 1";
CM_ SG_ 2432656640 pOperatorButton2 "Instrument Cluster Control  - 2";
CM_ SG_ 2432656640 pOperatorButton3 "Headlamp - 1 (Low)";
CM_ SG_ 2432656640 pOperatorButton4 "Headlamp - 2 (High)";
CM_ SG_ 2432656640 pOperatorButton5 "Headlamp - 3 (Driving)";
CM_ SG_ 2432656640 pOperatorButton6 "Turn - 1 (Left)";
CM_ SG_ 2432656640 pOperatorButton7 "Turn - 2 (Right)";
CM_ SG_ 2432656640 pOperatorButton8 "Turn - 3 (Cancel)";
CM_ SG_ 2432656640 pOperatorButton9 "Hazard";
CM_ SG_ 2432656640 pOperatorButton10 "Cruise - 1 (On)";
CM_ SG_ 2432656640 pOperatorButton11 "Cruise - 2 (Set)";
CM_ SG_ 2432656640 pOperatorButton12 "Cruise - 3 (Accel)";
CM_ SG_ 2432656640 pOperatorButton13 "Horn";
CM_ SG_ 2432656640 pOperatorButton14 "Start";
CM_ SG_ 2432656640 pOperatorButton15 "Warmer - 1";
CM_ SG_ 2432656640 pOperatorButton16 "Warmer - 2";
CM_ SG_ 2432656640 pOperatorButton17 "Warmer - 3";
CM_ SG_ 2432656640 pOperatorButton18 "Warmer - 4";
CM_ SG_ 2432656640 pOperatorButton19 "Windshield Wiper";
CM_ SG_ 2432656640 pOperatorButton20 "Engine On";
CM_ SG_ 2432656640 pOperatorButton21 "Reverse";
CM_ SG_ 2432656640 pOperatorButton22 "Homelink 1";
CM_ SG_ 2432656640 pOperatorButton23 "Homelink 2";
CM_ SG_ 2432656640 pOperatorButton24 "Throttle Safety Switch - 1";
CM_ SG_ 2432656640 pOperatorButton25 "Windshield - 1 (Up)";
CM_ SG_ 2432656640 pOperatorButton26 "Windshield - 2 (Down)";
CM_ SG_ 2432656640 pOperatorButton27 "Hand Brake Switch";
CM_ SG_ 2432656640 pOperatorButton28 "Clutch Switch";
CM_ SG_ 2432656640 pSideStandStatus "Status of the side stand switch of a motorcycle";
CM_ BO_ 2365548032 "Engine Instrument Cluster Fast Update";
CM_ SG_ 2365548032 pHighIdleState "Indicates whether or not the engine control module has deliberately increased the idle RPM in order to boost system voltage.";
CM_ SG_ 2365548032 pEngineSpeed "Engine speed which includes RPM > 8000 rpm.";
CM_ SG_ 2365548032 pStuckThrottle "Signal which indicates whether or not the throttle is stuck open.";
CM_ SG_ 2365548032 pFuelRange "Distance vehicle can travel on fuel remaining in fuel tank";
CM_ BO_ 2566913792 "ECU Data List 1";
CM_ SG_ 2566913792 DL1_EngineThrottlePosition "The position of the valve used to regulate the supply of a fluid, usually air or fuel/air mixture, to an engine.";
CM_ SG_ 2566913792 DL1_EngineSpeed "Actual engine speed which is calculated over a minimum crankshaft angle of 720 degrees divided by
the number of cylinders";
CM_ SG_ 2566913792 DL1_EngineCoolantTemperature "Temperature of liquid found in engine coolant system.";
CM_ SG_ 2566913792 DL1_EngIntakeManifoldPressure "Pressure of pre-combustion air found in intake manifold of engine air supply system.";
CM_ SG_ 2566913792 DL1_EngineAirInletTemperature "Temperature of air entering vehicle air induction system.";
CM_ SG_ 2566913792 DL1_BatteryPotential "This parameter measures the first souce of battery potential as measured at the input of the ECM/actuator etc. coming from one or more batteries, irrespective of the distance between the component
and the battery.";
CM_ BO_ 2566913536 "ECU Data List 2";
CM_ SG_ 2566913536 DL2_EngineThrottlePosition "The position of the valve used to regulatethe supply of a fluid, usually air or fuel/air mixture, to an engine.";
CM_ SG_ 2566913536 DL2_EngineCoolantTemperature "Temperature of liquid found in engine coolant system.";
CM_ SG_ 2566913536 DL2_EngineAirInletTemperature "Temperature of air entering vehicle air induction system.";
CM_ SG_ 2566913536 DL2_EngIntakeManifoldPressure "Pressure of pre-combustion air found in intake manifold of engine air supply system.";
CM_ SG_ 2566913536 DL2_Boost "Gage pressure of air measured downstream on the compressor discharge side of the turbocharger.";
CM_ SG_ 2566913536 DL2_BarometricPressure "Absolute air pressure of the atmosphere.";
CM_ SG_ 2566913536 DL2_Wheel_BasedVehicleSpeed "Speed of the vehicle as calculated from wheel or tailshaft speed.";
CM_ SG_ 2566913536 DL2_BarometricPressure_Volts "Absolute air pressure of the atmosphere.";
CM_ BO_ 2566913280 "ECU Data List 3";
CM_ SG_ 2566913280 DL3_IdleAirCntrlPosition "Current position of the idle air control stepper motor.";
CM_ SG_ 2566913280 DL3_DesiredIACPosition "Desired position of the idle air control stepper motor (IAC).";
CM_ SG_ 2566913280 DL3_EnginePercentLoad "Engine percent load.";
CM_ SG_ 2566913280 DL3_IdleTargetRPM "Target RPM for idle.";
CM_ SG_ 2566913280 DL3_EngineThrottlePositionHR "The position of the valve used to regulate the supply of a fluid, usually air or fuel/air mixture, to an engine.";
CM_ BO_ 2566911744 "ECU Data List 9";
CM_ BO_ 2566911488 "ECU Data List 10";
CM_ BO_ 2566909952 "ECU Data List 11";
CM_ SG_ 2566909952 DL11_EngRunTime "Engine lifetime run time accumulator.";
CM_ SG_ 2566909952 DL11_EngRunTimeKeyOn "Engine run time since last key on.";
CM_ BO_ 2566909696 "ECU Data List 12";
CM_ BO_ 2566909440 "ECU Data List 13";
CM_ BO_ 2566909184 "ECU Data List 14";
CM_ BO_ 2566908928 "ECU Data List 15";
CM_ BO_ 2566908672 "ECU Data List 16";
CM_ BO_ 2566913024 "ECU Data List 4";
CM_ BO_ 2566912768 "ECU Data List 2";
CM_ BO_ 2566912512 "ECU Data List 6";
CM_ BO_ 2566912256 "ECU Data List 7";
CM_ SG_ 2566912256 DL7_FuelTypSelected "Fuel Type Selected";
CM_ SG_ 2566912256 DL7_EngRunngMode "Data List - Engine Running Mode";
CM_ SG_ 2566912256 DL7_EngineThrottlePosition2 "The position of the valve used to regulate the supply of a fluid, usually air or fuel/air mixture, to an engine.";
CM_ SG_ 2566912256 DL7_SensorSupplyVoltage1 "Snow: DC-SDI includes TPS & TMAP PWR; DI is TPS1";
CM_ SG_ 2566912256 DL7_SensorSupplyVoltage2 "Snow: DC-SDI is Ground Speed Sensor PWR; DI includes TPS2, BAP & TMAP PWR";
CM_ SG_ 2566912256 DL7_SensorSupplyVoltage3 "Snow: DI Ground Speed Sensor Power";
CM_ SG_ 2566912256 DL7_ECUOutSupplyVoltage1 "Snow: DI Ignition Supply PWR";
CM_ SG_ 2566912256 DL7_ECUOutSupplyVoltage2 "Snow: DC-SDI Injection Supply PWR";
CM_ BO_ 2566912000 "ECU Data List 8";
BA_DEF_ SG_  "GenSigSendType" ENUM  "Cyclic","OnWrite","OnWriteWithRepetition","OnChange","OnChangeWithRepetition","IfActive","IfActiveWithRepetition","NoSigSendType";
BA_DEF_ SG_  "GenSigStartValue" INT 0 10000;
BA_DEF_ SG_  "GenSigEVName" STRING ;
BA_DEF_ SG_  "SPN" INT 0 524287;
BA_DEF_ SG_  "SigType" ENUM  "Default","Range","RangeSigned","ASCII","Discrete","Control","ReferencePGN","DTC","StringDelimiter","StringLength","StringLengthControl","MessageCounter","MessageChecksum";
BA_DEF_ SG_  "GenSigILSupport" ENUM  "No","Yes";
BA_DEF_ BO_  "GenMsgCycleTimeFast" INT 0 3600000;
BA_DEF_ BO_  "GenMsgILSupport" ENUM  "No","Yes";
BA_DEF_ BO_  "J1939PGNameSecSrc0Dest3" STRING ;
BA_DEF_ BO_  "J1939PGRelationDest3Src0" INT 0 254;
BA_DEF_ BO_  "J1939PGtoECUSrc0Dest3" INT 0 254;
BA_DEF_ BO_  "J1939PGtoWSMSrc0Dest3" INT 0 254;
BA_DEF_ BO_  "J1939PGRelationSrc0Dest3" INT 0 254;
BA_DEF_ BO_  "J1939PGRepTypeSrc0Dest3" INT 0 4;
BA_DEF_ BO_  "J1939PGRepCycleSrc0Dest3" INT -1 65535;
BA_DEF_ BO_  "J1939PGPrioSrc0Dest3" INT 0 7;
BA_DEF_ BO_  "J1939PGRepetitionType" ENUM  "always","when active","on request";
BA_DEF_ BO_  "J1939PGRepetitionCycle" INT 0 65535;
BA_DEF_ BO_  "J1939PGPrio" INT 0 7;
BA_DEF_ BO_  "VFrameFormat" ENUM  "StandardCAN","ExtendedCAN","reserved","J1939PG";
BA_DEF_ BO_  "GenMsgCycleTime" INT 0 3600000;
BA_DEF_ BO_  "GenMsgRequestable" INT 0 1;
BA_DEF_ BO_  "GenMsgSendType" ENUM  "cyclic","spontaneous","cyclicIfActive","spontaneousWithDelay","cyclicAndSpontaneous","cyclicAndSpontaneousWithDelay","spontaneousWithRepetition","cyclicIfActiveAndSpontaneousWD";
BA_DEF_DEF_  "GenSigSendType" "NoSigSendType";
BA_DEF_DEF_  "GenSigStartValue" 0;
BA_DEF_DEF_  "GenSigEVName" "Env@Nodename_@Signame";
BA_DEF_DEF_  "SPN" 0;
BA_DEF_DEF_  "SigType" "Default";
BA_DEF_DEF_  "GenSigILSupport" "Yes";
BA_DEF_DEF_  "GenMsgCycleTimeFast" 0;
BA_DEF_DEF_  "GenMsgILSupport" "Yes";
BA_DEF_DEF_  "J1939PGNameSecSrc0Dest3" "(null)";
BA_DEF_DEF_  "J1939PGRelationDest3Src0" 254;
BA_DEF_DEF_  "J1939PGtoECUSrc0Dest3" -1;
BA_DEF_DEF_  "J1939PGtoWSMSrc0Dest3" -1;
BA_DEF_DEF_  "J1939PGRelationSrc0Dest3" 254;
BA_DEF_DEF_  "J1939PGRepTypeSrc0Dest3" 3;
BA_DEF_DEF_  "J1939PGRepCycleSrc0Dest3" -1;
BA_DEF_DEF_  "J1939PGPrioSrc0Dest3" 6;
BA_DEF_DEF_  "J1939PGRepetitionType" "always";
BA_DEF_DEF_  "J1939PGRepetitionCycle" 100;
BA_DEF_DEF_  "J1939PGPrio" 6;
BA_DEF_DEF_  "VFrameFormat" "J1939PG";
BA_DEF_DEF_  "GenMsgCycleTime" 0;
BA_DEF_DEF_  "GenMsgRequestable" 1;
BA_DEF_DEF_  "GenMsgSendType" "cyclic";
BA_ "GenMsgCycleTime" BO_ 2565799548 100;
BA_ "GenMsgCycleTime" BO_ 2565799544 100;
BA_ "GenMsgCycleTime" BO_ 2565799673 100;
BA_ "GenMsgCycleTime" BO_ 2231309056 5000;
BA_ "GenMsgSendType" BO_ 2231309056 4;
BA_ "GenMsgCycleTime" BO_ 2565799471 100;
BA_ "GenMsgCycleTimeFast" BO_ 2566887215 100;
BA_ "GenMsgCycleTime" BO_ 2566887215 100;
BA_ "GenMsgSendType" BO_ 2566887215 4;
BA_ "GenMsgCycleTime" BO_ 2432656705 100;
BA_ "GenMsgCycleTime" BO_ 2365523591 5000;
BA_ "GenMsgSendType" BO_ 2365523591 4;
BA_ "GenMsgCycleTime" BO_ 2365523590 5000;
BA_ "GenMsgSendType" BO_ 2365523590 4;
BA_ "GenMsgCycleTime" BO_ 2566844807 100;
BA_ "GenMsgCycleTime" BO_ 2365523495 5000;
BA_ "GenMsgSendType" BO_ 2365523495 4;
BA_ "GenMsgCycleTime" BO_ 2563833511 100;
BA_ "GenMsgCycleTime" BO_ 2566847655 1000;
BA_ "GenMsgCycleTime" BO_ 2566834727 100;
BA_ "GenMsgCycleTime" BO_ 2566832449 1000;
BA_ "GenMsgCycleTime" BO_ 2365473063 100;
BA_ "GenMsgCycleTime" BO_ 2633883431 500;
BA_ "GenMsgCycleTime" BO_ 2566877479 1000;
BA_ "GenMsgCycleTimeFast" BO_ 2566887168 100;
BA_ "GenMsgCycleTime" BO_ 2566887168 100;
BA_ "GenMsgSendType" BO_ 2566887168 4;
BA_ "GenMsgCycleTimeFast" BO_ 2431708455 20;
BA_ "GenMsgCycleTime" BO_ 2431708455 250;
BA_ "GenMsgSendType" BO_ 2431708455 4;
BA_ "J1939PGRepetitionCycle" BO_ 2297441583 10;
BA_ "GenMsgCycleTime" BO_ 2297441583 10;
BA_ "GenMsgCycleTime" BO_ 2432656774 100;
BA_ "GenMsgCycleTime" BO_ 2565799489 100;
BA_ "GenMsgCycleTime" BO_ 2565799453 100;
BA_ "GenMsgCycleTime" BO_ 2565799447 100;
BA_ "GenMsgCycleTime" BO_ 2565799443 100;
BA_ "GenMsgCycleTime" BO_ 2565799435 100;
BA_ "GenMsgCycleTime" BO_ 2565799424 100;
BA_ "GenMsgCycleTime" BO_ 2631794205 100;
BA_ "GenMsgCycleTime" BO_ 2631794199 100;
BA_ "GenMsgCycleTime" BO_ 2631728640 100;
BA_ "GenMsgCycleTime" BO_ 2561212031 100;
BA_ "GenMsgCycleTime" BO_ 2566844160 500;
BA_ "GenMsgCycleTime" BO_ 2432658432 100;
BA_ "GenMsgCycleTime" BO_ 2633984512 100;
BA_ "GenMsgCycleTime" BO_ 2566847511 1000;
BA_ "GenMsgCycleTime" BO_ 2566845719 1000;
BA_ "GenMsgCycleTime" BO_ 2566847488 1000;
BA_ "GenMsgCycleTime" BO_ 2565867008 500;
BA_ "GenMsgCycleTime" BO_ 2566841600 100;
BA_ "GenMsgCycleTime" BO_ 2566832407 1000;
BA_ "GenMsgCycleTime" BO_ 2566834688 100;
BA_ "GenMsgCycleTime" BO_ 2564423168 100;
BA_ "GenMsgCycleTime" BO_ 2564356352 100;
BA_ "GenMsgCycleTime" BO_ 2633883392 500;
BA_ "GenMsgCycleTime" BO_ 2432656640 100;
BA_ "GenMsgCycleTime" BO_ 2365548032 100;
BA_ "SPN" SG_ 2565799548 IdentityNumber 2837;
BA_ "SigType" SG_ 2565799548 IdentityNumber 1.7E-308;
BA_ "SPN" SG_ 2565799548 ManufacturerCode 2838;
BA_ "SigType" SG_ 2565799548 ManufacturerCode 1.7E-308;
BA_ "SPN" SG_ 2565799548 ECUInstance 2840;
BA_ "SigType" SG_ 2565799548 ECUInstance 1.7E-308;
BA_ "SPN" SG_ 2565799548 FunctionInstance 2839;
BA_ "SigType" SG_ 2565799548 FunctionInstance 1.7E-308;
BA_ "SPN" SG_ 2565799548 Function 2841;
BA_ "SigType" SG_ 2565799548 Function 1.7E-308;
BA_ "SPN" SG_ 2565799548 VehicleSystem 2842;
BA_ "SigType" SG_ 2565799548 VehicleSystem 1.7E-308;
BA_ "SPN" SG_ 2565799548 VehicleSystemInstance 2843;
BA_ "SigType" SG_ 2565799548 VehicleSystemInstance 1.7E-308;
BA_ "SPN" SG_ 2565799548 IndustryGroup 2846;
BA_ "SigType" SG_ 2565799548 IndustryGroup 1.7E-308;
BA_ "SPN" SG_ 2565799548 ArbitraryAddressCapable 2844;
BA_ "SigType" SG_ 2565799548 ArbitraryAddressCapable 1.7E-308;
BA_ "SPN" SG_ 2565799544 IdentityNumber 2837;
BA_ "SigType" SG_ 2565799544 IdentityNumber 1.7E-308;
BA_ "SPN" SG_ 2565799544 ManufacturerCode 2838;
BA_ "SigType" SG_ 2565799544 ManufacturerCode 1.7E-308;
BA_ "SPN" SG_ 2565799544 ECUInstance 2840;
BA_ "SigType" SG_ 2565799544 ECUInstance 1.7E-308;
BA_ "SPN" SG_ 2565799544 FunctionInstance 2839;
BA_ "SigType" SG_ 2565799544 FunctionInstance 1.7E-308;
BA_ "SPN" SG_ 2565799544 Function 2841;
BA_ "SigType" SG_ 2565799544 Function 1.7E-308;
BA_ "SPN" SG_ 2565799544 VehicleSystem 2842;
BA_ "SigType" SG_ 2565799544 VehicleSystem 1.7E-308;
BA_ "SPN" SG_ 2565799544 VehicleSystemInstance 2843;
BA_ "SigType" SG_ 2565799544 VehicleSystemInstance 1.7E-308;
BA_ "SPN" SG_ 2565799544 IndustryGroup 2846;
BA_ "SigType" SG_ 2565799544 IndustryGroup 1.7E-308;
BA_ "SPN" SG_ 2565799544 ArbitraryAddressCapable 2844;
BA_ "SigType" SG_ 2565799544 ArbitraryAddressCapable 1.7E-308;
BA_ "SPN" SG_ 2565799673 IdentityNumber 2837;
BA_ "SigType" SG_ 2565799673 IdentityNumber 1.7E-308;
BA_ "SPN" SG_ 2565799673 ManufacturerCode 2838;
BA_ "SigType" SG_ 2565799673 ManufacturerCode 1.7E-308;
BA_ "SPN" SG_ 2565799673 ECUInstance 2840;
BA_ "SigType" SG_ 2565799673 ECUInstance 1.7E-308;
BA_ "SPN" SG_ 2565799673 FunctionInstance 2839;
BA_ "SigType" SG_ 2565799673 FunctionInstance 1.7E-308;
BA_ "SPN" SG_ 2565799673 Function 2841;
BA_ "SigType" SG_ 2565799673 Function 1.7E-308;
BA_ "SPN" SG_ 2565799673 VehicleSystem 2842;
BA_ "SigType" SG_ 2565799673 VehicleSystem 1.7E-308;
BA_ "SPN" SG_ 2565799673 VehicleSystemInstance 2843;
BA_ "SigType" SG_ 2565799673 VehicleSystemInstance 1.7E-308;
BA_ "SPN" SG_ 2565799673 IndustryGroup 2846;
BA_ "SigType" SG_ 2565799673 IndustryGroup 1.7E-308;
BA_ "SPN" SG_ 2565799673 ArbitraryAddressCapable 2844;
BA_ "SigType" SG_ 2565799673 ArbitraryAddressCapable 1.7E-308;
BA_ "SPN" SG_ 2231309056 pEPCU_1_Speed_Limit 524251;
BA_ "SPN" SG_ 2231309056 pEPCU_1_Counter_Torque_Limit 524251;
BA_ "SPN" SG_ 2231309056 pEPCU_1_Torque_Demand 524251;
BA_ "SPN" SG_ 2231309056 pEPCU_1_Control_Mode 524251;
BA_ "SPN" SG_ 2231309056 pEPCU_1_Message_Counter 524251;
BA_ "SPN" SG_ 2231309056 pEPCU_1_Checksum 524251;
BA_ "SPN" SG_ 2565799471 IdentityNumber 2837;
BA_ "SigType" SG_ 2565799471 IdentityNumber 1.7E-308;
BA_ "SPN" SG_ 2565799471 ManufacturerCode 2838;
BA_ "SigType" SG_ 2565799471 ManufacturerCode 1.7E-308;
BA_ "SPN" SG_ 2565799471 ECUInstance 2840;
BA_ "SigType" SG_ 2565799471 ECUInstance 1.7E-308;
BA_ "SPN" SG_ 2565799471 FunctionInstance 2839;
BA_ "SigType" SG_ 2565799471 FunctionInstance 1.7E-308;
BA_ "SPN" SG_ 2565799471 Function 2841;
BA_ "SigType" SG_ 2565799471 Function 1.7E-308;
BA_ "SPN" SG_ 2565799471 VehicleSystem 2842;
BA_ "SigType" SG_ 2565799471 VehicleSystem 1.7E-308;
BA_ "SPN" SG_ 2565799471 VehicleSystemInstance 2843;
BA_ "SigType" SG_ 2565799471 VehicleSystemInstance 1.7E-308;
BA_ "SPN" SG_ 2565799471 IndustryGroup 2846;
BA_ "SigType" SG_ 2565799471 IndustryGroup 1.7E-308;
BA_ "SPN" SG_ 2565799471 ArbitraryAddressCapable 2844;
BA_ "SigType" SG_ 2565799471 ArbitraryAddressCapable 1.7E-308;
BA_ "SPN" SG_ 2566887215 pSuspensionDampingPercentFR 524285;
BA_ "SPN" SG_ 2566887215 pVehicleEventStatusCornering 524283;
BA_ "SPN" SG_ 2566887215 pVehicleEventStatusBraking 524188;
BA_ "SPN" SG_ 2566887215 pVehicleEventStatusAirborne 524187;
BA_ "SPN" SG_ 2566887215 pVehicleEventStatusAccel 524187;
BA_ "SPN" SG_ 2566887215 pSuspensionModeActive 524186;
BA_ "SPN" SG_ 2566887215 pSuspensionDampingPercentRR 524287;
BA_ "SPN" SG_ 2566887215 pSuspensionDampingPercentRL 524286;
BA_ "SPN" SG_ 2566887215 pSuspensionDampingPercentFL 524284;
BA_ "SPN" SG_ 2432656705 pOperatorButton29 524060;
BA_ "SPN" SG_ 2432656705 pOperatorButton1 524059;
BA_ "SigType" SG_ 2432656705 pOperatorButton1 1.7E-308;
BA_ "SPN" SG_ 2432656705 pOperatorButton2 524058;
BA_ "SigType" SG_ 2432656705 pOperatorButton2 1.7E-308;
BA_ "SPN" SG_ 2432656705 pOperatorButton3 524057;
BA_ "SigType" SG_ 2432656705 pOperatorButton3 1.7E-308;
BA_ "SPN" SG_ 2432656705 pOperatorButton4 524056;
BA_ "SigType" SG_ 2432656705 pOperatorButton4 1.7E-308;
BA_ "SPN" SG_ 2432656705 pOperatorButton5 524055;
BA_ "SigType" SG_ 2432656705 pOperatorButton5 1.7E-308;
BA_ "SPN" SG_ 2432656705 pOperatorButton6 524054;
BA_ "SigType" SG_ 2432656705 pOperatorButton6 1.7E-308;
BA_ "SPN" SG_ 2432656705 pOperatorButton7 524053;
BA_ "SigType" SG_ 2432656705 pOperatorButton7 1.7E-308;
BA_ "SPN" SG_ 2432656705 pOperatorButton8 524052;
BA_ "SigType" SG_ 2432656705 pOperatorButton8 1.7E-308;
BA_ "SPN" SG_ 2432656705 pOperatorButton9 524051;
BA_ "SigType" SG_ 2432656705 pOperatorButton9 1.7E-308;
BA_ "SPN" SG_ 2432656705 pOperatorButton10 524050;
BA_ "SigType" SG_ 2432656705 pOperatorButton10 1.7E-308;
BA_ "SPN" SG_ 2432656705 pOperatorButton11 524049;
BA_ "SigType" SG_ 2432656705 pOperatorButton11 1.7E-308;
BA_ "SPN" SG_ 2432656705 pOperatorButton12 524048;
BA_ "SigType" SG_ 2432656705 pOperatorButton12 1.7E-308;
BA_ "SPN" SG_ 2432656705 pOperatorButton13 524047;
BA_ "SigType" SG_ 2432656705 pOperatorButton13 1.7E-308;
BA_ "SPN" SG_ 2432656705 pOperatorButton14 524046;
BA_ "SigType" SG_ 2432656705 pOperatorButton14 1.7E-308;
BA_ "SPN" SG_ 2432656705 pOperatorButton15 524045;
BA_ "SigType" SG_ 2432656705 pOperatorButton15 1.7E-308;
BA_ "SPN" SG_ 2432656705 pOperatorButton16 524044;
BA_ "SigType" SG_ 2432656705 pOperatorButton16 1.7E-308;
BA_ "SPN" SG_ 2432656705 pOperatorButton17 524043;
BA_ "SigType" SG_ 2432656705 pOperatorButton17 1.7E-308;
BA_ "SPN" SG_ 2432656705 pOperatorButton18 524042;
BA_ "SigType" SG_ 2432656705 pOperatorButton18 1.7E-308;
BA_ "SPN" SG_ 2432656705 pOperatorButton19 524041;
BA_ "SigType" SG_ 2432656705 pOperatorButton19 1.7E-308;
BA_ "SPN" SG_ 2432656705 pOperatorButton20 524040;
BA_ "SigType" SG_ 2432656705 pOperatorButton20 1.7E-308;
BA_ "SPN" SG_ 2432656705 pOperatorButton21 524039;
BA_ "SigType" SG_ 2432656705 pOperatorButton21 1.7E-308;
BA_ "SPN" SG_ 2432656705 pOperatorButton22 524038;
BA_ "SigType" SG_ 2432656705 pOperatorButton22 1.7E-308;
BA_ "SPN" SG_ 2432656705 pOperatorButton23 524037;
BA_ "SigType" SG_ 2432656705 pOperatorButton23 1.7E-308;
BA_ "SPN" SG_ 2432656705 pOperatorButton24 524036;
BA_ "SigType" SG_ 2432656705 pOperatorButton24 1.7E-308;
BA_ "SPN" SG_ 2432656705 pOperatorButton25 524035;
BA_ "SigType" SG_ 2432656705 pOperatorButton25 1.7E-308;
BA_ "SPN" SG_ 2432656705 pOperatorButton26 524034;
BA_ "SigType" SG_ 2432656705 pOperatorButton26 1.7E-308;
BA_ "SPN" SG_ 2432656705 pOperatorButton27 520322;
BA_ "SigType" SG_ 2432656705 pOperatorButton27 1.7E-308;
BA_ "SPN" SG_ 2432656705 pOperatorButton28 524032;
BA_ "SigType" SG_ 2432656705 pOperatorButton28 1.7E-308;
BA_ "SPN" SG_ 2432656705 pSideStandStatus 524098;
BA_ "SigType" SG_ 2432656705 pSideStandStatus 1.7E-308;
BA_ "SPN" SG_ 2365523591 pModCtlMsg_Checksum 516097;
BA_ "SPN" SG_ 2365523591 pModCtlAppliedState 516096;
BA_ "SPN" SG_ 2365523591 pModCtlCmdDestAdd 524185;
BA_ "SPN" SG_ 2365523591 pModCtlCmdState 524248;
BA_ "SPN" SG_ 2365523590 pModCtlMsg_Checksum 516097;
BA_ "SPN" SG_ 2365523590 pModCtlAppliedState 516096;
BA_ "SPN" SG_ 2365523590 pModCtlCmdDestAdd 524185;
BA_ "SPN" SG_ 2365523590 pModCtlCmdState 524248;
BA_ "GenSigStartValue" SG_ 2566844807 pCruiseCntrlCounter 7;
BA_ "SPN" SG_ 2566844807 pCruiseCntrlCounter 524080;
BA_ "SPN" SG_ 2566844807 TwoSpeedAxleSwitch 69;
BA_ "SigType" SG_ 2566844807 TwoSpeedAxleSwitch 1.7E-308;
BA_ "SPN" SG_ 2566844807 ParkingBrakeSwitch 70;
BA_ "SigType" SG_ 2566844807 ParkingBrakeSwitch 1.7E-308;
BA_ "SPN" SG_ 2566844807 Wheel_BasedVehicleSpeed 84;
BA_ "SigType" SG_ 2566844807 Wheel_BasedVehicleSpeed 1.7E-308;
BA_ "SPN" SG_ 2566844807 CruiseCtrlActive 595;
BA_ "SigType" SG_ 2566844807 CruiseCtrlActive 1.7E-308;
BA_ "SPN" SG_ 2566844807 CruiseCtrlEnableSwitch 596;
BA_ "SigType" SG_ 2566844807 CruiseCtrlEnableSwitch 1.7E-308;
BA_ "SPN" SG_ 2566844807 BrakeSwitch 597;
BA_ "SigType" SG_ 2566844807 BrakeSwitch 1.7E-308;
BA_ "SPN" SG_ 2566844807 ClutchSwitch 598;
BA_ "SigType" SG_ 2566844807 ClutchSwitch 1.7E-308;
BA_ "SPN" SG_ 2566844807 CruiseCtrlSetSwitch 599;
BA_ "SigType" SG_ 2566844807 CruiseCtrlSetSwitch 1.7E-308;
BA_ "SPN" SG_ 2566844807 CruiseCtrlCoastSwitch 600;
BA_ "SigType" SG_ 2566844807 CruiseCtrlCoastSwitch 1.7E-308;
BA_ "SPN" SG_ 2566844807 CruiseCtrlResumeSwitch 601;
BA_ "SigType" SG_ 2566844807 CruiseCtrlResumeSwitch 1.7E-308;
BA_ "SPN" SG_ 2566844807 CruiseCtrlAccelerateSwitch 602;
BA_ "SigType" SG_ 2566844807 CruiseCtrlAccelerateSwitch 1.7E-308;
BA_ "SPN" SG_ 2566844807 CruiseCtrlSetSpeed 86;
BA_ "SigType" SG_ 2566844807 CruiseCtrlSetSpeed 1.7E-308;
BA_ "SPN" SG_ 2566844807 pOdometerDriveBit 523994;
BA_ "SigType" SG_ 2566844807 pOdometerDriveBit 1.7E-308;
BA_ "SPN" SG_ 2566844807 CruiseCtrlPauseSw 1633;
BA_ "SigType" SG_ 2566844807 CruiseCtrlPauseSw 1.7E-308;
BA_ "SPN" SG_ 2566844807 pCCChecksum 524079;
BA_ "SigType" SG_ 2566844807 pCCChecksum 1.7E-308;
BA_ "SPN" SG_ 2566844807 pCruiseEnableStatus 524108;
BA_ "SigType" SG_ 2566844807 pCruiseEnableStatus 1.7E-308;
BA_ "SPN" SG_ 2365523495 pModCtlMsg_Checksum 516097;
BA_ "SPN" SG_ 2365523495 pModCtlAppliedState 516096;
BA_ "SPN" SG_ 2365523495 pModCtlCmdDestAdd 524185;
BA_ "SPN" SG_ 2365523495 pModCtlCmdState 524248;
BA_ "SPN" SG_ 2563833511 IlluminationBrightnessPercent 1487;
BA_ "SigType" SG_ 2563833511 IlluminationBrightnessPercent 1.7E-308;
BA_ "SPN" SG_ 2563833511 SwitchBacklightIlluminPercent 5532;
BA_ "SigType" SG_ 2563833511 SwitchBacklightIlluminPercent 1.7E-308;
BA_ "SPN" SG_ 2566847655 WasherFluidLevel 80;
BA_ "SigType" SG_ 2566847655 WasherFluidLevel 1.7E-308;
BA_ "SPN" SG_ 2566847655 FuelLevel 96;
BA_ "SigType" SG_ 2566847655 FuelLevel 1.7E-308;
BA_ "SPN" SG_ 2566847655 FuelFilterDiffPressure 95;
BA_ "SigType" SG_ 2566847655 FuelFilterDiffPressure 1.7E-308;
BA_ "SPN" SG_ 2566847655 EngineOilFilterDiffPressure 99;
BA_ "SigType" SG_ 2566847655 EngineOilFilterDiffPressure 1.7E-308;
BA_ "SPN" SG_ 2566847655 CargoAmbientTemperature 169;
BA_ "SigType" SG_ 2566847655 CargoAmbientTemperature 1.7E-308;
BA_ "SigType" SG_ 2566834727 DTC5 7;
BA_ "SigType" SG_ 2566834727 DTC4 7;
BA_ "SigType" SG_ 2566834727 DTC3 7;
BA_ "SigType" SG_ 2566834727 DTC2 7;
BA_ "SigType" SG_ 2566834727 DTC1 7;
BA_ "SPN" SG_ 2566834727 DM_FlashRedStopLamp 3039;
BA_ "SPN" SG_ 2566834727 DM_FlashProtectLamp 3041;
BA_ "SPN" SG_ 2566834727 DM_FlashMalfuncIndicatorLamp 3038;
BA_ "SPN" SG_ 2566834727 DM_FlashAmberWarningLamp 3040;
BA_ "SPN" SG_ 2566834727 DM_ProtectLampStatus 987;
BA_ "SigType" SG_ 2566834727 DM_ProtectLampStatus 1.7E-308;
BA_ "SPN" SG_ 2566834727 DM_RedStopLampState 623;
BA_ "SigType" SG_ 2566834727 DM_RedStopLampState 1.7E-308;
BA_ "SPN" SG_ 2566834727 DM_AmberWrningLmpStatus 624;
BA_ "SigType" SG_ 2566834727 DM_AmberWrningLmpStatus 1.7E-308;
BA_ "SPN" SG_ 2566834727 DM_MalfuncnIndicatorLampStatus 1213;
BA_ "SigType" SG_ 2566834727 DM_MalfuncnIndicatorLampStatus 1.7E-308;
BA_ "SPN" SG_ 2566832449 HighResolTotalVehicleDistance 917;
BA_ "SigType" SG_ 2566832449 HighResolTotalVehicleDistance 1.7E-308;
BA_ "SPN" SG_ 2566832449 HighResolTripDistance 918;
BA_ "SigType" SG_ 2566832449 HighResolTripDistance 1.7E-308;
BA_ "SPN" SG_ 2365473063 LowBeamHeadlightCommand 2349;
BA_ "SPN" SG_ 2365473063 HighBeamHeadlightCommand 2347;
BA_ "SPN" SG_ 2365473063 LeftTurnSigLightsCommand 2367;
BA_ "SigType" SG_ 2365473063 LeftTurnSigLightsCommand 1.7E-308;
BA_ "SPN" SG_ 2365473063 RightTurnSigLightsCommand 2369;
BA_ "SigType" SG_ 2365473063 RightTurnSigLightsCommand 1.7E-308;
BA_ "SPN" SG_ 2633883431 FrtWheelDriveActuatorStatus 2612;
BA_ "SigType" SG_ 2633883431 FrtWheelDriveActuatorStatus 1.7E-308;
BA_ "SPN" SG_ 2566877479 pVolumeUnitsSelected 524267;
BA_ "SPN" SG_ 2566877479 pTimeUnitsSelected 524268;
BA_ "SPN" SG_ 2566877479 pTemperatureUnitsSelected 524266;
BA_ "SPN" SG_ 2566877479 pPressureUnitsSelected 524269;
BA_ "SPN" SG_ 2566877479 pHighResTrip2Distance 524264;
BA_ "SPN" SG_ 2566877479 pDistanceUnitsSelected 524265;
BA_ "SPN" SG_ 2566877479 pTPMSLearningStatus 524104;
BA_ "SigType" SG_ 2566877479 pTPMSLearningStatus 1.7E-308;
BA_ "SPN" SG_ 2566877479 pDisplayStatus 524105;
BA_ "SigType" SG_ 2566877479 pDisplayStatus 1.7E-308;
BA_ "SPN" SG_ 2566887168 pSuspensionDampingPercentFR 524285;
BA_ "SPN" SG_ 2566887168 pVehicleEventStatusCornering 524283;
BA_ "SPN" SG_ 2566887168 pVehicleEventStatusBraking 524188;
BA_ "SPN" SG_ 2566887168 pVehicleEventStatusAirborne 524187;
BA_ "SPN" SG_ 2566887168 pVehicleEventStatusAccel 524187;
BA_ "SPN" SG_ 2566887168 pSuspensionModeActive 524186;
BA_ "SPN" SG_ 2566887168 pSuspensionDampingPercentRR 524287;
BA_ "SPN" SG_ 2566887168 pSuspensionDampingPercentRL 524286;
BA_ "SPN" SG_ 2566887168 pSuspensionDampingPercentFL 524284;
BA_ "SPN" SG_ 2431708455 MessageCounter_EngStartCtl 7750;
BA_ "SigType" SG_ 2431708455 MessageCounter_EngStartCtl 1.7E-308;
BA_ "SPN" SG_ 2431708455 MessageChecksum_EngStartCtl 7751;
BA_ "SigType" SG_ 2431708455 MessageChecksum_EngStartCtl 1.7E-308;
BA_ "SPN" SG_ 2431708455 EngineStarter2Feedback 7749;
BA_ "SigType" SG_ 2431708455 EngineStarter2Feedback 1.7E-308;
BA_ "SPN" SG_ 2431708455 EngineStarter1Feedback 7748;
BA_ "SigType" SG_ 2431708455 EngineStarter1Feedback 1.7E-308;
BA_ "SPN" SG_ 2431708455 EngineStartAbortReq 7747;
BA_ "SigType" SG_ 2431708455 EngineStartAbortReq 1.7E-308;
BA_ "SPN" SG_ 2431708455 TransShiftSelectRequVehDir 7788;
BA_ "SigType" SG_ 2431708455 TransShiftSelectRequVehDir 1.7E-308;
BA_ "SPN" SG_ 2431708455 EngineStartReq 7745;
BA_ "SigType" SG_ 2431708455 EngineStartReq 1.7E-308;
BA_ "SPN" SG_ 2431708455 EngineStartConsent 7746;
BA_ "SigType" SG_ 2431708455 EngineStartConsent 1.7E-308;
BA_ "SPN" SG_ 2297441583 Vertical_Accel_Ext_Range 5349;
BA_ "SPN" SG_ 2297441583 Vertical_Accel_Ext_Merit 5352;
BA_ "SPN" SG_ 2297441583 Longitudinal_Accel_Ext_Range 5348;
BA_ "SPN" SG_ 2297441583 Longitudinal_Accel_Ext_Merit 5351;
BA_ "SPN" SG_ 2297441583 Lateral_Accel_Ext_Range 5347;
BA_ "SPN" SG_ 2297441583 Lateral_Accel_Ext_Merit 5350;
BA_ "SPN" SG_ 2297441583 Accel_Sensor_Support_Var 5353;
BA_ "SPN" SG_ 2432656774 pOperatorButton29 524060;
BA_ "SPN" SG_ 2432656774 pOperatorButton1 524059;
BA_ "SigType" SG_ 2432656774 pOperatorButton1 1.7E-308;
BA_ "SPN" SG_ 2432656774 pOperatorButton2 524058;
BA_ "SigType" SG_ 2432656774 pOperatorButton2 1.7E-308;
BA_ "SPN" SG_ 2432656774 pOperatorButton3 524057;
BA_ "SigType" SG_ 2432656774 pOperatorButton3 1.7E-308;
BA_ "SPN" SG_ 2432656774 pOperatorButton4 524056;
BA_ "SigType" SG_ 2432656774 pOperatorButton4 1.7E-308;
BA_ "SPN" SG_ 2432656774 pOperatorButton5 524055;
BA_ "SigType" SG_ 2432656774 pOperatorButton5 1.7E-308;
BA_ "SPN" SG_ 2432656774 pOperatorButton6 524054;
BA_ "SigType" SG_ 2432656774 pOperatorButton6 1.7E-308;
BA_ "SPN" SG_ 2432656774 pOperatorButton7 524053;
BA_ "SigType" SG_ 2432656774 pOperatorButton7 1.7E-308;
BA_ "SPN" SG_ 2432656774 pOperatorButton8 524052;
BA_ "SigType" SG_ 2432656774 pOperatorButton8 1.7E-308;
BA_ "SPN" SG_ 2432656774 pOperatorButton9 524051;
BA_ "SigType" SG_ 2432656774 pOperatorButton9 1.7E-308;
BA_ "SPN" SG_ 2432656774 pOperatorButton10 524050;
BA_ "SigType" SG_ 2432656774 pOperatorButton10 1.7E-308;
BA_ "SPN" SG_ 2432656774 pOperatorButton11 524049;
BA_ "SigType" SG_ 2432656774 pOperatorButton11 1.7E-308;
BA_ "SPN" SG_ 2432656774 pOperatorButton12 524048;
BA_ "SigType" SG_ 2432656774 pOperatorButton12 1.7E-308;
BA_ "SPN" SG_ 2432656774 pOperatorButton13 524047;
BA_ "SigType" SG_ 2432656774 pOperatorButton13 1.7E-308;
BA_ "SPN" SG_ 2432656774 pOperatorButton14 524046;
BA_ "SigType" SG_ 2432656774 pOperatorButton14 1.7E-308;
BA_ "SPN" SG_ 2432656774 pOperatorButton15 524045;
BA_ "SigType" SG_ 2432656774 pOperatorButton15 1.7E-308;
BA_ "SPN" SG_ 2432656774 pOperatorButton16 524044;
BA_ "SigType" SG_ 2432656774 pOperatorButton16 1.7E-308;
BA_ "SPN" SG_ 2432656774 pOperatorButton17 524043;
BA_ "SigType" SG_ 2432656774 pOperatorButton17 1.7E-308;
BA_ "SPN" SG_ 2432656774 pOperatorButton18 524042;
BA_ "SigType" SG_ 2432656774 pOperatorButton18 1.7E-308;
BA_ "SPN" SG_ 2432656774 pOperatorButton19 524041;
BA_ "SigType" SG_ 2432656774 pOperatorButton19 1.7E-308;
BA_ "SPN" SG_ 2432656774 pOperatorButton20 524040;
BA_ "SigType" SG_ 2432656774 pOperatorButton20 1.7E-308;
BA_ "SPN" SG_ 2432656774 pOperatorButton21 524039;
BA_ "SigType" SG_ 2432656774 pOperatorButton21 1.7E-308;
BA_ "SPN" SG_ 2432656774 pOperatorButton22 524038;
BA_ "SigType" SG_ 2432656774 pOperatorButton22 1.7E-308;
BA_ "SPN" SG_ 2432656774 pOperatorButton23 524037;
BA_ "SigType" SG_ 2432656774 pOperatorButton23 1.7E-308;
BA_ "SPN" SG_ 2432656774 pOperatorButton24 524036;
BA_ "SigType" SG_ 2432656774 pOperatorButton24 1.7E-308;
BA_ "SPN" SG_ 2432656774 pOperatorButton25 524035;
BA_ "SigType" SG_ 2432656774 pOperatorButton25 1.7E-308;
BA_ "SPN" SG_ 2432656774 pOperatorButton26 524034;
BA_ "SigType" SG_ 2432656774 pOperatorButton26 1.7E-308;
BA_ "SPN" SG_ 2432656774 pOperatorButton27 520322;
BA_ "SigType" SG_ 2432656774 pOperatorButton27 1.7E-308;
BA_ "SPN" SG_ 2432656774 pOperatorButton28 524032;
BA_ "SigType" SG_ 2432656774 pOperatorButton28 1.7E-308;
BA_ "SPN" SG_ 2432656774 pSideStandStatus 524098;
BA_ "SigType" SG_ 2432656774 pSideStandStatus 1.7E-308;
BA_ "SPN" SG_ 2565799489 IdentityNumber 2837;
BA_ "SigType" SG_ 2565799489 IdentityNumber 1.7E-308;
BA_ "SPN" SG_ 2565799489 ManufacturerCode 2838;
BA_ "SigType" SG_ 2565799489 ManufacturerCode 1.7E-308;
BA_ "SPN" SG_ 2565799489 ECUInstance 2840;
BA_ "SigType" SG_ 2565799489 ECUInstance 1.7E-308;
BA_ "SPN" SG_ 2565799489 FunctionInstance 2839;
BA_ "SigType" SG_ 2565799489 FunctionInstance 1.7E-308;
BA_ "SPN" SG_ 2565799489 Function 2841;
BA_ "SigType" SG_ 2565799489 Function 1.7E-308;
BA_ "SPN" SG_ 2565799489 VehicleSystem 2842;
BA_ "SigType" SG_ 2565799489 VehicleSystem 1.7E-308;
BA_ "SPN" SG_ 2565799489 VehicleSystemInstance 2843;
BA_ "SigType" SG_ 2565799489 VehicleSystemInstance 1.7E-308;
BA_ "SPN" SG_ 2565799489 IndustryGroup 2846;
BA_ "SigType" SG_ 2565799489 IndustryGroup 1.7E-308;
BA_ "SPN" SG_ 2565799489 ArbitraryAddressCapable 2844;
BA_ "SigType" SG_ 2565799489 ArbitraryAddressCapable 1.7E-308;
BA_ "SPN" SG_ 2565799453 IdentityNumber 2837;
BA_ "SigType" SG_ 2565799453 IdentityNumber 1.7E-308;
BA_ "SPN" SG_ 2565799453 ManufacturerCode 2838;
BA_ "SigType" SG_ 2565799453 ManufacturerCode 1.7E-308;
BA_ "SPN" SG_ 2565799453 ECUInstance 2840;
BA_ "SigType" SG_ 2565799453 ECUInstance 1.7E-308;
BA_ "SPN" SG_ 2565799453 FunctionInstance 2839;
BA_ "SigType" SG_ 2565799453 FunctionInstance 1.7E-308;
BA_ "SPN" SG_ 2565799453 Function 2841;
BA_ "SigType" SG_ 2565799453 Function 1.7E-308;
BA_ "SPN" SG_ 2565799453 VehicleSystem 2842;
BA_ "SigType" SG_ 2565799453 VehicleSystem 1.7E-308;
BA_ "SPN" SG_ 2565799453 VehicleSystemInstance 2843;
BA_ "SigType" SG_ 2565799453 VehicleSystemInstance 1.7E-308;
BA_ "SPN" SG_ 2565799453 IndustryGroup 2846;
BA_ "SigType" SG_ 2565799453 IndustryGroup 1.7E-308;
BA_ "SPN" SG_ 2565799453 ArbitraryAddressCapable 2844;
BA_ "SigType" SG_ 2565799453 ArbitraryAddressCapable 1.7E-308;
BA_ "SPN" SG_ 2565799447 IdentityNumber 2837;
BA_ "SigType" SG_ 2565799447 IdentityNumber 1.7E-308;
BA_ "SPN" SG_ 2565799447 ManufacturerCode 2838;
BA_ "SigType" SG_ 2565799447 ManufacturerCode 1.7E-308;
BA_ "SPN" SG_ 2565799447 ECUInstance 2840;
BA_ "SigType" SG_ 2565799447 ECUInstance 1.7E-308;
BA_ "SPN" SG_ 2565799447 FunctionInstance 2839;
BA_ "SigType" SG_ 2565799447 FunctionInstance 1.7E-308;
BA_ "SPN" SG_ 2565799447 Function 2841;
BA_ "SigType" SG_ 2565799447 Function 1.7E-308;
BA_ "SPN" SG_ 2565799447 VehicleSystem 2842;
BA_ "SigType" SG_ 2565799447 VehicleSystem 1.7E-308;
BA_ "SPN" SG_ 2565799447 VehicleSystemInstance 2843;
BA_ "SigType" SG_ 2565799447 VehicleSystemInstance 1.7E-308;
BA_ "SPN" SG_ 2565799447 IndustryGroup 2846;
BA_ "SigType" SG_ 2565799447 IndustryGroup 1.7E-308;
BA_ "SPN" SG_ 2565799447 ArbitraryAddressCapable 2844;
BA_ "SigType" SG_ 2565799447 ArbitraryAddressCapable 1.7E-308;
BA_ "SPN" SG_ 2565799443 IdentityNumber 2837;
BA_ "SigType" SG_ 2565799443 IdentityNumber 1.7E-308;
BA_ "SPN" SG_ 2565799443 ManufacturerCode 2838;
BA_ "SigType" SG_ 2565799443 ManufacturerCode 1.7E-308;
BA_ "SPN" SG_ 2565799443 ECUInstance 2840;
BA_ "SigType" SG_ 2565799443 ECUInstance 1.7E-308;
BA_ "SPN" SG_ 2565799443 FunctionInstance 2839;
BA_ "SigType" SG_ 2565799443 FunctionInstance 1.7E-308;
BA_ "SPN" SG_ 2565799443 Function 2841;
BA_ "SigType" SG_ 2565799443 Function 1.7E-308;
BA_ "SPN" SG_ 2565799443 VehicleSystem 2842;
BA_ "SigType" SG_ 2565799443 VehicleSystem 1.7E-308;
BA_ "SPN" SG_ 2565799443 VehicleSystemInstance 2843;
BA_ "SigType" SG_ 2565799443 VehicleSystemInstance 1.7E-308;
BA_ "SPN" SG_ 2565799443 IndustryGroup 2846;
BA_ "SigType" SG_ 2565799443 IndustryGroup 1.7E-308;
BA_ "SPN" SG_ 2565799443 ArbitraryAddressCapable 2844;
BA_ "SigType" SG_ 2565799443 ArbitraryAddressCapable 1.7E-308;
BA_ "SPN" SG_ 2565799435 IdentityNumber 2837;
BA_ "SigType" SG_ 2565799435 IdentityNumber 1.7E-308;
BA_ "SPN" SG_ 2565799435 ManufacturerCode 2838;
BA_ "SigType" SG_ 2565799435 ManufacturerCode 1.7E-308;
BA_ "SPN" SG_ 2565799435 ECUInstance 2840;
BA_ "SigType" SG_ 2565799435 ECUInstance 1.7E-308;
BA_ "SPN" SG_ 2565799435 FunctionInstance 2839;
BA_ "SigType" SG_ 2565799435 FunctionInstance 1.7E-308;
BA_ "SPN" SG_ 2565799435 Function 2841;
BA_ "SigType" SG_ 2565799435 Function 1.7E-308;
BA_ "SPN" SG_ 2565799435 VehicleSystem 2842;
BA_ "SigType" SG_ 2565799435 VehicleSystem 1.7E-308;
BA_ "SPN" SG_ 2565799435 VehicleSystemInstance 2843;
BA_ "SigType" SG_ 2565799435 VehicleSystemInstance 1.7E-308;
BA_ "SPN" SG_ 2565799435 IndustryGroup 2846;
BA_ "SigType" SG_ 2565799435 IndustryGroup 1.7E-308;
BA_ "SPN" SG_ 2565799435 ArbitraryAddressCapable 2844;
BA_ "SigType" SG_ 2565799435 ArbitraryAddressCapable 1.7E-308;
BA_ "SPN" SG_ 2565799424 IdentityNumber 2837;
BA_ "SigType" SG_ 2565799424 IdentityNumber 1.7E-308;
BA_ "SPN" SG_ 2565799424 ManufacturerCode 2838;
BA_ "SigType" SG_ 2565799424 ManufacturerCode 1.7E-308;
BA_ "SPN" SG_ 2565799424 ECUInstance 2840;
BA_ "SigType" SG_ 2565799424 ECUInstance 1.7E-308;
BA_ "SPN" SG_ 2565799424 FunctionInstance 2839;
BA_ "SigType" SG_ 2565799424 FunctionInstance 1.7E-308;
BA_ "SPN" SG_ 2565799424 Function 2841;
BA_ "SigType" SG_ 2565799424 Function 1.7E-308;
BA_ "SPN" SG_ 2565799424 VehicleSystem 2842;
BA_ "SigType" SG_ 2565799424 VehicleSystem 1.7E-308;
BA_ "SPN" SG_ 2565799424 VehicleSystemInstance 2843;
BA_ "SigType" SG_ 2565799424 VehicleSystemInstance 1.7E-308;
BA_ "SPN" SG_ 2565799424 IndustryGroup 2846;
BA_ "SigType" SG_ 2565799424 IndustryGroup 1.7E-308;
BA_ "SPN" SG_ 2565799424 ArbitraryAddressCapable 2844;
BA_ "SigType" SG_ 2565799424 ArbitraryAddressCapable 1.7E-308;
BA_ "SPN" SG_ 2631794205 EncryptionIndicatorStates 1199;
BA_ "SigType" SG_ 2631794205 EncryptionIndicatorStates 1.7E-308;
BA_ "SPN" SG_ 2631794205 AntiTheftDesiredExitModeStates 1200;
BA_ "SigType" SG_ 2631794205 AntiTheftDesiredExitModeStates 1.7E-308;
BA_ "SPN" SG_ 2631794205 AntiTheftCommandStates 1201;
BA_ "SigType" SG_ 2631794205 AntiTheftCommandStates 1.7E-308;
BA_ "SPN" SG_ 2631794205 AntiTheftPasswordRepresentation 1202;
BA_ "SigType" SG_ 2631794205 AntiTheftPasswordRepresentation 1.7E-308;
BA_ "SPN" SG_ 2631794199 EncryptionIndicatorStates 1199;
BA_ "SigType" SG_ 2631794199 EncryptionIndicatorStates 1.7E-308;
BA_ "SPN" SG_ 2631794199 AntiTheftDesiredExitModeStates 1200;
BA_ "SigType" SG_ 2631794199 AntiTheftDesiredExitModeStates 1.7E-308;
BA_ "SPN" SG_ 2631794199 AntiTheftCommandStates 1201;
BA_ "SigType" SG_ 2631794199 AntiTheftCommandStates 1.7E-308;
BA_ "SPN" SG_ 2631794199 AntiTheftPasswordRepresentation 1202;
BA_ "SigType" SG_ 2631794199 AntiTheftPasswordRepresentation 1.7E-308;
BA_ "SPN" SG_ 2631728640 AntiTheftEncryptSeedPresentInd 1194;
BA_ "SigType" SG_ 2631728640 AntiTheftEncryptSeedPresentInd 1.7E-308;
BA_ "SPN" SG_ 2631728640 AntiTheftPasswordValidIndicator 1195;
BA_ "SigType" SG_ 2631728640 AntiTheftPasswordValidIndicator 1.7E-308;
BA_ "SPN" SG_ 2631728640 AntiTheftModifyPasswordStates 1197;
BA_ "SigType" SG_ 2631728640 AntiTheftModifyPasswordStates 1.7E-308;
BA_ "SPN" SG_ 2631728640 AntiTheftRandomNumber 1198;
BA_ "SigType" SG_ 2631728640 AntiTheftRandomNumber 1.7E-308;
BA_ "SPN" SG_ 2631728640 AntiTheftComponentStatusInd 1196;
BA_ "SigType" SG_ 2631728640 AntiTheftComponentStatusInd 1.7E-308;
BA_ "SPN" SG_ 2561212031 TextDisplayInstructions 3613;
BA_ "SigType" SG_ 2561212031 TextDisplayInstructions 1.7E-308;
BA_ "SPN" SG_ 2561212031 TextDisplayCharacter 3615;
BA_ "SigType" SG_ 2561212031 TextDisplayCharacter 1.7E-308;
BA_ "SPN" SG_ 2561212031 TextDisplayIndex 3614;
BA_ "SigType" SG_ 2561212031 TextDisplayIndex 1.7E-308;
BA_ "SPN" SG_ 2566844160 FuelDeliveryPressure 94;
BA_ "SigType" SG_ 2566844160 FuelDeliveryPressure 1.7E-308;
BA_ "SPN" SG_ 2566844160 EngineOilLevel 98;
BA_ "SigType" SG_ 2566844160 EngineOilLevel 1.7E-308;
BA_ "SPN" SG_ 2566844160 EngineOilPressure 100;
BA_ "SigType" SG_ 2566844160 EngineOilPressure 1.7E-308;
BA_ "SPN" SG_ 2566844160 EngineCrankcasePressure 101;
BA_ "SigType" SG_ 2566844160 EngineCrankcasePressure 1.7E-308;
BA_ "SPN" SG_ 2566844160 EngineCoolantPressure 109;
BA_ "SigType" SG_ 2566844160 EngineCoolantPressure 1.7E-308;
BA_ "SPN" SG_ 2566844160 EngineCoolantLevel 111;
BA_ "SigType" SG_ 2566844160 EngineCoolantLevel 1.7E-308;
BA_ "SPN" SG_ 2566844160 ExtCrankcaseBlowByPressure 22;
BA_ "SigType" SG_ 2566844160 ExtCrankcaseBlowByPressure 1.7E-308;
BA_ "SPN" SG_ 2432658432 pOperatorButton42 520468;
BA_ "SPN" SG_ 2432658432 pOperatorButton41 520467;
BA_ "SPN" SG_ 2432658432 pOperatorButton39 524071;
BA_ "SPN" SG_ 2432658432 pOperatorButton37 524069;
BA_ "SPN" SG_ 2432658432 pOperatorButton36 524068;
BA_ "SPN" SG_ 2432658432 pFOCCMessageCounter 524082;
BA_ "SPN" SG_ 2432658432 pFOCCChecksum 524081;
BA_ "SPN" SG_ 2432658432 pOperatorButton40 524072;
BA_ "SPN" SG_ 2432658432 pOperatorButton38 524070;
BA_ "SPN" SG_ 2432658432 pOperatorButton35 524066;
BA_ "SPN" SG_ 2432658432 pOperatorButton34 524065;
BA_ "SPN" SG_ 2432658432 pOperatorButton33 524064;
BA_ "SPN" SG_ 2432658432 pOperatorButton32 524063;
BA_ "SPN" SG_ 2432658432 pOperatorButton31 524062;
BA_ "SPN" SG_ 2432658432 pOperatorButton30 524061;
BA_ "SPN" SG_ 2432658432 pOperatorButton29 524060;
BA_ "SPN" SG_ 2633984512 pHeatedGripEnable 520366;
BA_ "SPN" SG_ 2633984512 pSideStandStatus 524098;
BA_ "SigType" SG_ 2633984512 pSideStandStatus 1.7E-308;
BA_ "SPN" SG_ 2633984512 pTetherSwitchStatus 520600;
BA_ "SPN" SG_ 2633984512 pLowFuelIndicatorStatus 524087;
BA_ "SPN" SG_ 2633984512 pOperatorNotInOperatingStation 2832;
BA_ "SPN" SG_ 2633984512 pParkBrakeIndicatorStatus 524271;
BA_ "SPN" SG_ 2633984512 pADCRequested 524139;
BA_ "SPN" SG_ 2633984512 pAWDModeRequested 524138;
BA_ "SPN" SG_ 2633984512 pRWDModeRequested 524137;
BA_ "SPN" SG_ 2633984512 pTurfModeRequested 524136;
BA_ "SPN" SG_ 2633984512 pADCStatus 524013;
BA_ "SigType" SG_ 2633984512 pADCStatus 1.7E-308;
BA_ "SPN" SG_ 2633984512 pTreadleNeutralStatus 524017;
BA_ "SigType" SG_ 2633984512 pTreadleNeutralStatus 1.7E-308;
BA_ "SPN" SG_ 2633984512 pTreadleReverseStatus 524018;
BA_ "SigType" SG_ 2633984512 pTreadleReverseStatus 1.7E-308;
BA_ "SPN" SG_ 2633984512 pSecurityLightStatus 524019;
BA_ "SigType" SG_ 2633984512 pSecurityLightStatus 1.7E-308;
BA_ "SPN" SG_ 2633984512 pHighBeamIndicatorStatus 524084;
BA_ "SigType" SG_ 2633984512 pHighBeamIndicatorStatus 1.7E-308;
BA_ "SPN" SG_ 2633984512 pHeatedGripsPercentage 524096;
BA_ "SigType" SG_ 2633984512 pHeatedGripsPercentage 1.7E-308;
BA_ "SPN" SG_ 2633984512 pCruiseControlSetStatus 524097;
BA_ "SigType" SG_ 2633984512 pCruiseControlSetStatus 1.7E-308;
BA_ "SPN" SG_ 2633984512 pSeatBeltIndicatorStatus 524092;
BA_ "SigType" SG_ 2633984512 pSeatBeltIndicatorStatus 1.7E-308;
BA_ "SPN" SG_ 2566847511 WasherFluidLevel 80;
BA_ "SigType" SG_ 2566847511 WasherFluidLevel 1.7E-308;
BA_ "SPN" SG_ 2566847511 FuelLevel 96;
BA_ "SigType" SG_ 2566847511 FuelLevel 1.7E-308;
BA_ "SPN" SG_ 2566847511 FuelFilterDiffPressure 95;
BA_ "SigType" SG_ 2566847511 FuelFilterDiffPressure 1.7E-308;
BA_ "SPN" SG_ 2566847511 EngineOilFilterDiffPressure 99;
BA_ "SigType" SG_ 2566847511 EngineOilFilterDiffPressure 1.7E-308;
BA_ "SPN" SG_ 2566847511 CargoAmbientTemperature 169;
BA_ "SigType" SG_ 2566847511 CargoAmbientTemperature 1.7E-308;
BA_ "SPN" SG_ 2566845719 DL_BarometricPressure 108;
BA_ "SigType" SG_ 2566845719 DL_BarometricPressure 1.7E-308;
BA_ "SPN" SG_ 2566845719 CabInteriorTemperature 170;
BA_ "SigType" SG_ 2566845719 CabInteriorTemperature 1.7E-308;
BA_ "SPN" SG_ 2566845719 AmbientAirTemperature 171;
BA_ "SigType" SG_ 2566845719 AmbientAirTemperature 1.7E-308;
BA_ "SPN" SG_ 2566845719 EngineAirInletTemperature 172;
BA_ "SigType" SG_ 2566845719 EngineAirInletTemperature 1.7E-308;
BA_ "SPN" SG_ 2566845719 RoadSurfaceTemperature 79;
BA_ "SigType" SG_ 2566845719 RoadSurfaceTemperature 1.7E-308;
BA_ "SPN" SG_ 2566847488 WasherFluidLevel 80;
BA_ "SigType" SG_ 2566847488 WasherFluidLevel 1.7E-308;
BA_ "SPN" SG_ 2566847488 FuelLevel 96;
BA_ "SigType" SG_ 2566847488 FuelLevel 1.7E-308;
BA_ "SPN" SG_ 2566847488 FuelFilterDiffPressure 95;
BA_ "SigType" SG_ 2566847488 FuelFilterDiffPressure 1.7E-308;
BA_ "SPN" SG_ 2566847488 EngineOilFilterDiffPressure 99;
BA_ "SigType" SG_ 2566847488 EngineOilFilterDiffPressure 1.7E-308;
BA_ "SPN" SG_ 2566847488 CargoAmbientTemperature 169;
BA_ "SigType" SG_ 2566847488 CargoAmbientTemperature 1.7E-308;
BA_ "SPN" SG_ 2565867008 Location 927;
BA_ "SigType" SG_ 2565867008 Location 1.7E-308;
BA_ "SPN" SG_ 2565867008 DifferentialLockFrontAxle1 567;
BA_ "SigType" SG_ 2565867008 DifferentialLockFrontAxle1 1.7E-308;
BA_ "SPN" SG_ 2565867008 DifferentialLockFrontAxle2 568;
BA_ "SigType" SG_ 2565867008 DifferentialLockFrontAxle2 1.7E-308;
BA_ "SPN" SG_ 2565867008 DifferentialLockRearAxle1 569;
BA_ "SigType" SG_ 2565867008 DifferentialLockRearAxle1 1.7E-308;
BA_ "SPN" SG_ 2565867008 DifferentialLockRearAxle2 570;
BA_ "SigType" SG_ 2565867008 DifferentialLockRearAxle2 1.7E-308;
BA_ "SPN" SG_ 2565867008 DifferentialCentral 564;
BA_ "SigType" SG_ 2565867008 DifferentialCentral 1.7E-308;
BA_ "SPN" SG_ 2565867008 DifferentialCentralFront 565;
BA_ "SigType" SG_ 2565867008 DifferentialCentralFront 1.7E-308;
BA_ "SPN" SG_ 2565867008 DifferentialCentralRear 566;
BA_ "SigType" SG_ 2565867008 DifferentialCentralRear 1.7E-308;
BA_ "SPN" SG_ 2566841600 EngTotalHoursOfOper 247;
BA_ "SigType" SG_ 2566841600 EngTotalHoursOfOper 1.7E-308;
BA_ "SPN" SG_ 2566841600 TotalEngineRevolutions 249;
BA_ "SigType" SG_ 2566841600 TotalEngineRevolutions 1.7E-308;
BA_ "SPN" SG_ 2566832407 HighResolTotalVehicleDistance 917;
BA_ "SigType" SG_ 2566832407 HighResolTotalVehicleDistance 1.7E-308;
BA_ "SPN" SG_ 2566832407 HighResolTripDistance 918;
BA_ "SigType" SG_ 2566832407 HighResolTripDistance 1.7E-308;
BA_ "SPN" SG_ 2566834688 DM_ProtectLampStatus 987;
BA_ "SigType" SG_ 2566834688 DM_ProtectLampStatus 1.7E-308;
BA_ "SPN" SG_ 2566834688 DM_RedStopLampState 623;
BA_ "SigType" SG_ 2566834688 DM_RedStopLampState 1.7E-308;
BA_ "SPN" SG_ 2566834688 DM_AmberWrningLmpStatus 624;
BA_ "SigType" SG_ 2566834688 DM_AmberWrningLmpStatus 1.7E-308;
BA_ "SPN" SG_ 2566834688 DM_MalfuncnIndicatorLampStatus 1213;
BA_ "SigType" SG_ 2566834688 DM_MalfuncnIndicatorLampStatus 1.7E-308;
BA_ "SPN" SG_ 2566834688 DM_FlashRedStopLamp 3039;
BA_ "SPN" SG_ 2566834688 DM_FlashMalfuncIndicatorLamp 3038;
BA_ "SigType" SG_ 2566834688 DTC5 7;
BA_ "SigType" SG_ 2566834688 DTC4 7;
BA_ "SigType" SG_ 2566834688 DTC3 7;
BA_ "SigType" SG_ 2566834688 DTC2 7;
BA_ "SigType" SG_ 2566834688 DTC1 7;
BA_ "SPN" SG_ 2566834688 DM_FlashProtectLamp 3041;
BA_ "SPN" SG_ 2566834688 DM_FlashAmberWarningLamp 3040;
BA_ "SPN" SG_ 2564423168 DM_NumberRequested 1640;
BA_ "SigType" SG_ 2564423168 DM_NumberRequested 1.7E-308;
BA_ "SPN" SG_ 2564423168 DM_PointerType 1641;
BA_ "SigType" SG_ 2564423168 DM_PointerType 1.7E-308;
BA_ "SPN" SG_ 2564423168 DM_Command 1642;
BA_ "SigType" SG_ 2564423168 DM_Command 1.7E-308;
BA_ "SPN" SG_ 2564423168 DM_Pointer 1644;
BA_ "SigType" SG_ 2564423168 DM_Pointer 1.7E-308;
BA_ "SPN" SG_ 2564423168 DM_PointerExtension 1643;
BA_ "SigType" SG_ 2564423168 DM_PointerExtension 1.7E-308;
BA_ "SPN" SG_ 2564423168 DM_UserLevel 1645;
BA_ "SigType" SG_ 2564423168 DM_UserLevel 1.7E-308;
BA_ "GenSigStartValue" SG_ 2564356352 DM15_SAE_Reserved2 1;
BA_ "GenSigStartValue" SG_ 2564356352 DM15_SAE_Reserved 1;
BA_ "SPN" SG_ 2633883392 FrtWheelDriveActuatorStatus 2612;
BA_ "SigType" SG_ 2633883392 FrtWheelDriveActuatorStatus 1.7E-308;
BA_ "SPN" SG_ 2432656640 pOperatorButton29 524060;
BA_ "SPN" SG_ 2432656640 pOperatorButton1 524059;
BA_ "SigType" SG_ 2432656640 pOperatorButton1 1.7E-308;
BA_ "SPN" SG_ 2432656640 pOperatorButton2 524058;
BA_ "SigType" SG_ 2432656640 pOperatorButton2 1.7E-308;
BA_ "SPN" SG_ 2432656640 pOperatorButton3 524057;
BA_ "SigType" SG_ 2432656640 pOperatorButton3 1.7E-308;
BA_ "SPN" SG_ 2432656640 pOperatorButton4 524056;
BA_ "SigType" SG_ 2432656640 pOperatorButton4 1.7E-308;
BA_ "SPN" SG_ 2432656640 pOperatorButton5 524055;
BA_ "SigType" SG_ 2432656640 pOperatorButton5 1.7E-308;
BA_ "SPN" SG_ 2432656640 pOperatorButton6 524054;
BA_ "SigType" SG_ 2432656640 pOperatorButton6 1.7E-308;
BA_ "SPN" SG_ 2432656640 pOperatorButton7 524053;
BA_ "SigType" SG_ 2432656640 pOperatorButton7 1.7E-308;
BA_ "SPN" SG_ 2432656640 pOperatorButton8 524052;
BA_ "SigType" SG_ 2432656640 pOperatorButton8 1.7E-308;
BA_ "SPN" SG_ 2432656640 pOperatorButton9 524051;
BA_ "SigType" SG_ 2432656640 pOperatorButton9 1.7E-308;
BA_ "SPN" SG_ 2432656640 pOperatorButton10 524050;
BA_ "SigType" SG_ 2432656640 pOperatorButton10 1.7E-308;
BA_ "SPN" SG_ 2432656640 pOperatorButton11 524049;
BA_ "SigType" SG_ 2432656640 pOperatorButton11 1.7E-308;
BA_ "SPN" SG_ 2432656640 pOperatorButton12 524048;
BA_ "SigType" SG_ 2432656640 pOperatorButton12 1.7E-308;
BA_ "SPN" SG_ 2432656640 pOperatorButton13 524047;
BA_ "SigType" SG_ 2432656640 pOperatorButton13 1.7E-308;
BA_ "SPN" SG_ 2432656640 pOperatorButton14 524046;
BA_ "SigType" SG_ 2432656640 pOperatorButton14 1.7E-308;
BA_ "SPN" SG_ 2432656640 pOperatorButton15 524045;
BA_ "SigType" SG_ 2432656640 pOperatorButton15 1.7E-308;
BA_ "SPN" SG_ 2432656640 pOperatorButton16 524044;
BA_ "SigType" SG_ 2432656640 pOperatorButton16 1.7E-308;
BA_ "SPN" SG_ 2432656640 pOperatorButton17 524043;
BA_ "SigType" SG_ 2432656640 pOperatorButton17 1.7E-308;
BA_ "SPN" SG_ 2432656640 pOperatorButton18 524042;
BA_ "SigType" SG_ 2432656640 pOperatorButton18 1.7E-308;
BA_ "SPN" SG_ 2432656640 pOperatorButton19 524041;
BA_ "SigType" SG_ 2432656640 pOperatorButton19 1.7E-308;
BA_ "SPN" SG_ 2432656640 pOperatorButton20 524040;
BA_ "SigType" SG_ 2432656640 pOperatorButton20 1.7E-308;
BA_ "SPN" SG_ 2432656640 pOperatorButton21 524039;
BA_ "SigType" SG_ 2432656640 pOperatorButton21 1.7E-308;
BA_ "SPN" SG_ 2432656640 pOperatorButton22 524038;
BA_ "SigType" SG_ 2432656640 pOperatorButton22 1.7E-308;
BA_ "SPN" SG_ 2432656640 pOperatorButton23 524037;
BA_ "SigType" SG_ 2432656640 pOperatorButton23 1.7E-308;
BA_ "SPN" SG_ 2432656640 pOperatorButton24 524036;
BA_ "SigType" SG_ 2432656640 pOperatorButton24 1.7E-308;
BA_ "SPN" SG_ 2432656640 pOperatorButton25 524035;
BA_ "SigType" SG_ 2432656640 pOperatorButton25 1.7E-308;
BA_ "SPN" SG_ 2432656640 pOperatorButton26 524034;
BA_ "SigType" SG_ 2432656640 pOperatorButton26 1.7E-308;
BA_ "SPN" SG_ 2432656640 pOperatorButton27 520322;
BA_ "SigType" SG_ 2432656640 pOperatorButton27 1.7E-308;
BA_ "SPN" SG_ 2432656640 pOperatorButton28 524032;
BA_ "SigType" SG_ 2432656640 pOperatorButton28 1.7E-308;
BA_ "SPN" SG_ 2432656640 pSideStandStatus 524098;
BA_ "SigType" SG_ 2432656640 pSideStandStatus 1.7E-308;
BA_ "SPN" SG_ 2365548032 pHighIdleState 524078;
BA_ "SPN" SG_ 2365548032 pEngineSpeed 524000;
BA_ "SigType" SG_ 2365548032 pEngineSpeed 1.7E-308;
BA_ "SPN" SG_ 2365548032 pStuckThrottle 524001;
BA_ "SigType" SG_ 2365548032 pStuckThrottle 1.7E-308;
BA_ "SPN" SG_ 2365548032 pFuelRange 524088;
BA_ "SigType" SG_ 2365548032 pFuelRange 1.7E-308;
BA_ "SigType" SG_ 2566913792 DL1_EngineThrottlePosition 1.7E-308;
BA_ "SigType" SG_ 2566913792 DL1_EngineSpeed 1.7E-308;
BA_ "SigType" SG_ 2566913792 DL1_EngineCoolantTemperature 1.7E-308;
BA_ "SigType" SG_ 2566913792 DL1_EngIntakeManifoldPressure 1.7E-308;
BA_ "SigType" SG_ 2566913792 DL1_EngineAirInletTemperature 1.7E-308;
BA_ "SigType" SG_ 2566913792 DL1_BatteryPotential 1.7E-308;
BA_ "SigType" SG_ 2566913536 DL2_EngineThrottlePosition 1.7E-308;
BA_ "SigType" SG_ 2566913536 DL2_EngineCoolantTemperature 1.7E-308;
BA_ "SigType" SG_ 2566913536 DL2_EngineAirInletTemperature 1.7E-308;
BA_ "SigType" SG_ 2566913536 DL2_EngIntakeManifoldPressure 1.7E-308;
BA_ "SigType" SG_ 2566913536 DL2_Boost 1.7E-308;
BA_ "SigType" SG_ 2566913536 DL2_BarometricPressure 1.7E-308;
BA_ "SigType" SG_ 2566913536 DL2_Wheel_BasedVehicleSpeed 1.7E-308;
BA_ "SigType" SG_ 2566913536 DL2_BarometricPressure_Volts 1.7E-308;
BA_ "SigType" SG_ 2566913280 DL3_IdleAirCntrlPosition 1.7E-308;
BA_ "SigType" SG_ 2566913280 DL3_DesiredIACPosition 1.7E-308;
BA_ "SigType" SG_ 2566913280 DL3_IdleAirSolenoidDC 1.7E-308;
BA_ "SigType" SG_ 2566913280 DL3_EnginePercentLoad 1.7E-308;
BA_ "SigType" SG_ 2566913280 DL3_IdleTargetRPM 1.7E-308;
BA_ "SigType" SG_ 2566913280 DL3_AbsThrottlePercent 1.7E-308;
BA_ "SigType" SG_ 2566913280 DL3_EngineThrottlePositionHR 1.7E-308;
BA_ "SigType" SG_ 2566911744 DL9_KnockRetardCyl1 1.7E-308;
BA_ "SigType" SG_ 2566911744 DL9_KnockRetardCyl2 1.7E-308;
BA_ "SigType" SG_ 2566911744 DL9_InjDETCorrMAG 1.7E-308;
BA_ "SigType" SG_ 2566911744 DL9_InjDETCorrPTO 1.7E-308;
BA_ "SigType" SG_ 2566911744 DL9_DetonationFreqCyl1 1.7E-308;
BA_ "SigType" SG_ 2566911744 DL9_DetonationFreqCyl2 1.7E-308;
BA_ "SigType" SG_ 2566911744 DL9_IgnitIonVarianceDeg 1.7E-308;
BA_ "SigType" SG_ 2566911744 DL9_FuelVariance 1.7E-308;
BA_ "SigType" SG_ 2566911488 DL10_PurgeValveSolenoidOut 1.7E-308;
BA_ "SigType" SG_ 2566909952 DL11_EngRunTime 1.7E-308;
BA_ "SigType" SG_ 2566909952 DL11_EngRunTimeKeyOn 1.7E-308;
BA_ "SigType" SG_ 2566909696 DL12_LambdaVoltBank2 1.7E-308;
BA_ "SigType" SG_ 2566909696 DL12_ActualLambdaBank2 1.7E-308;
BA_ "SigType" SG_ 2566909696 DL12_DesiredLambdaBank2 1.7E-308;
BA_ "SigType" SG_ 2566909696 DL12_MixAdaptationHiLoadBank2 1.7E-308;
BA_ "SigType" SG_ 2566909696 DL12_MixAdaptationLoLoadBank2 1.7E-308;
BA_ "SigType" SG_ 2566909696 DL12_ClosedLoopAdjFactor2 1.7E-308;
BA_ "SigType" SG_ 2566909696 DL12_LambaSensorHeaterOutBank2 1.7E-308;
BA_ "SigType" SG_ 2566909696 DL12_AirFuelMixStatusBank2 1.7E-308;
BA_ "SigType" SG_ 2566909696 DL12_ClosedLoopMixControlBank2 1.7E-308;
BA_ "SigType" SG_ 2566909440 DL13_PortInjector1Time 1.7E-308;
BA_ "SigType" SG_ 2566909440 DL13_CaseInjector1Time 1.7E-308;
BA_ "SigType" SG_ 2566909440 DL13_Cyl1IgnTiming 1.7E-308;
BA_ "SigType" SG_ 2566909440 DL13_Cyl1BaseIgnTiming 1.7E-308;
BA_ "SigType" SG_ 2566909440 DL13_Cyl1IgnCoilDwell 1.7E-308;
BA_ "SigType" SG_ 2566909184 DL14_PortInjector2Time 1.7E-308;
BA_ "SigType" SG_ 2566909184 DL14_CaseInjector2Time 1.7E-308;
BA_ "SigType" SG_ 2566909184 DL14_Cyl2IgnTiming 1.7E-308;
BA_ "SigType" SG_ 2566909184 DL14_Cyl2BaseIgnTiming 1.7E-308;
BA_ "SigType" SG_ 2566909184 DL14_Cyl2IgnCoilDwell 1.7E-308;
BA_ "SigType" SG_ 2566908928 DL15_ExhaustTemperature 1.7E-308;
BA_ "SigType" SG_ 2566908928 DL15_InjectorIgnitionSupplyVolt 1.7E-308;
BA_ "SigType" SG_ 2566908928 DL15_ElecStartOptBattVolt 1.7E-308;
BA_ "SigType" SG_ 2566908672 DL16_PedalPosSensor1 1.7E-308;
BA_ "SigType" SG_ 2566908672 DL16_PedalPosSensor2 1.7E-308;
BA_ "SigType" SG_ 2566913024 DL4_FuelInjector1PulseWidth 1.7E-308;
BA_ "SigType" SG_ 2566913024 DL4_IgnCoil1Dwell 1.7E-308;
BA_ "SigType" SG_ 2566913024 DL4_Cyl1IgnTiming 1.7E-308;
BA_ "SigType" SG_ 2566913024 DL4_Cyl1AirInjDuration 1.7E-308;
BA_ "SigType" SG_ 2566913024 DL4_FuelInjector2PulseWidth 1.7E-308;
BA_ "SigType" SG_ 2566913024 DL4_IgnCoil2Dwell 1.7E-308;
BA_ "SigType" SG_ 2566913024 DL4_Cyl2IgnTiming 1.7E-308;
BA_ "SigType" SG_ 2566913024 DL4_Cyl2AirInjDuration 1.7E-308;
BA_ "SigType" SG_ 2566912768 DL5_FuelInjector3PulseWidth 1.7E-308;
BA_ "SigType" SG_ 2566912768 DL5_IgnCoil3Dwell 1.7E-308;
BA_ "SigType" SG_ 2566912768 DL5_Cyl3IgnTiming 1.7E-308;
BA_ "SigType" SG_ 2566912768 DL5_Cyl3AirInjDuration 1.7E-308;
BA_ "SigType" SG_ 2566912768 DL5_FuelInjector4PulseWidth 1.7E-308;
BA_ "SigType" SG_ 2566912768 DL5_IgnCoil4Dwell 1.7E-308;
BA_ "SigType" SG_ 2566912768 DL5_Cyl4IgnTiming 1.7E-308;
BA_ "SigType" SG_ 2566912768 DL5_Cyl4AirInjDuration 1.7E-308;
BA_ "SigType" SG_ 2566912512 DL6_GearVolts 1.7E-308;
BA_ "SigType" SG_ 2566912512 DL6_RolloverVolts 1.7E-308;
BA_ "SigType" SG_ 2566912512 DL6_ThrottleReleaseInputVolts 1.7E-308;
BA_ "SigType" SG_ 2566912512 DL6_FuelTypeSensorVolts 1.7E-308;
BA_ "SigType" SG_ 2566912256 DL7_EngineThrottlePosition2 1.7E-308;
BA_ "SigType" SG_ 2566912256 DL7_SensorSupplyVoltage1 1.7E-308;
BA_ "SigType" SG_ 2566912256 DL7_SensorSupplyVoltage2 1.7E-308;
BA_ "SigType" SG_ 2566912256 DL7_SensorSupplyVoltage3 1.7E-308;
BA_ "SigType" SG_ 2566912256 DL7_ECUOutSupplyVoltage1 1.7E-308;
BA_ "SigType" SG_ 2566912256 DL7_ECUOutSupplyVoltage2 1.7E-308;
BA_ "SigType" SG_ 2566912000 DL8_LambdaVoltBank1 1.7E-308;
BA_ "SigType" SG_ 2566912000 DL8_ActualLambdaBank1 1.7E-308;
BA_ "SigType" SG_ 2566912000 DL8_DesiredLambdaBank1 1.7E-308;
BA_ "SigType" SG_ 2566912000 DL8_MixAdaptationHiLoadBank1 1.7E-308;
BA_ "SigType" SG_ 2566912000 DL8_MixAdaptationLoLoadBank1 1.7E-308;
BA_ "SigType" SG_ 2566912000 DL8_ClosedLoopAdjFactor1 1.7E-308;
BA_ "SigType" SG_ 2566912000 DL8_LambaSensorHeaterOutBank1 1.7E-308;
BA_ "SigType" SG_ 2566912000 DL8_AirFuelMixStatusBank1 1.7E-308;
BA_ "SigType" SG_ 2566912000 DL8_ClosedLoopMixControlBank1 1.7E-308;
BA_ "SigType" SG_ 2566911232 FI1_FuelPumpDriverCkt 1.7E-308;
BA_ "SigType" SG_ 2566911232 FI1_RolloverSwitch 1.7E-308;
BA_ "SigType" SG_ 2566911232 FI1_CrankSensorSignal 1.7E-308;
BA_ "SigType" SG_ 2566911232 FI1_CamSensorSignal 1.7E-308;
BA_ "SigType" SG_ 2566911232 FI1_RPMLimitActive 1.7E-308;
BA_ "SigType" SG_ 2566911232 FI1_IdleSwitch 1.7E-308;
BA_ "SigType" SG_ 2566911232 FI1_CycleSynchro 1.7E-308;
BA_ "SigType" SG_ 2566911232 FI1_IdleSpeedControlStatus 1.7E-308;
BA_ "SigType" SG_ 2566911232 FI1_IgnitionSwitchInput 1.7E-308;
BA_ "SigType" SG_ 2566911232 FI1_RunStopSwitchInput 1.7E-308;
BA_ "SigType" SG_ 2566911232 FI1_StartSwitchInput 1.7E-308;
BA_ "SigType" SG_ 2566911232 FI1_ThrottleSafetySwInput 1.7E-308;
BA_ "SigType" SG_ 2566911232 FI1_FanRelayOutput 1.7E-308;
BA_ "SigType" SG_ 2566911232 FI1_IntercoolerFanOutput 1.7E-308;
BA_ "SigType" SG_ 2566911232 FI1_ReverseAlarmOutput 1.7E-308;
BA_ "SigType" SG_ 2566911232 FI1_MainRelayOutput 1.7E-308;
BA_ "SigType" SG_ 2566911232 FI1_StartSolenoidOutput 1.7E-308;
BA_ "SigType" SG_ 2566911232 FI1_IgnitionRelayOutput 1.7E-308;
BA_ "SigType" SG_ 2566911232 FI1_ChassisRelayOutput 1.7E-308;
BA_ "SigType" SG_ 2566911232 FI1_StarterEnableOutput 1.7E-308;
BA_ "SigType" SG_ 2566911232 FI1_ExhaustValveOutput 1.7E-308;
BA_ "SigType" SG_ 2566911232 FI1_BatteryChargeRelayOutput 1.7E-308;
BA_ "SigType" SG_ 2566911232 FI1_HeaterAccRelay 1.7E-308;
BA_ "SigType" SG_ 2566911232 FI1_ClutchSwitchInput 1.7E-308;
BA_ "SigType" SG_ 2566911232 FI1_MILLampOutput 1.7E-308;
BA_ "SigType" SG_ 2566911232 FI1_OverTempLampOutput 1.7E-308;
BA_ "SigType" SG_ 2566911232 FI1_KnockDetLampOutput 1.7E-308;
BA_ "SigType" SG_ 2566911232 FI1_ElecOilPumpDrvrCirc 1.7E-308;
VAL_ 2565799548 ArbitraryAddressCapable 0 "No" 1 "Yes" ;
VAL_ 2565799544 ArbitraryAddressCapable 0 "No" 1 "Yes" ;
VAL_ 2565799673 ArbitraryAddressCapable 0 "No" 1 "Yes" ;
VAL_ 2565799471 ArbitraryAddressCapable 0 "No" 1 "Yes" ;
VAL_ 2566887215 pVehicleEventStatusCornering 3 "Not Available" 2 "Error" 1 "Cornering Event Detected" 0 "No Cornering Event Detected" ;
VAL_ 2566887215 pVehicleEventStatusBraking 3 "Not Available" 2 "Error" 1 "Braking Event Detected" 0 "No Braking Event Detected" ;
VAL_ 2566887215 pVehicleEventStatusAirborne 3 "Not Available" 2 "Error" 1 "Airborne Event Detected" 0 "No Airborne Event Detected" ;
VAL_ 2566887215 pVehicleEventStatusAccel 3 "Not Available" 2 "Error" 1 "Acceleration Event Detected" 0 "No Acceleration Event Detected" ;
VAL_ 2566887215 pSuspensionModeActive 14 "Not Available" 13 "Error State" 12 "Available for future use" 11 "Available for future use" 10 "Available for future use" 9 "Available for future use" 8 "Available for future use" 7 "Available for future use" 6 "Available for future use" 5 "Available for future use" 4 "Semi-Active Damping - Sport" 3 "Semi-Active Damping - Comfort" 2 "Passive - Soft" 1 "Passive - Medium" 0 "Passive - Firm" ;
VAL_ 2432656705 pOperatorButton29 3 "Not Available" 2 "Error" 1 "Button Pressed" 0 "Button Not Pressed" ;
VAL_ 2432656705 pOperatorButton1 0 "Not Pressed" 1 "Pressed" 2 "Error" 3 "Not Available" ;
VAL_ 2432656705 pOperatorButton2 0 "Active" 1 "Inactive" 2 "Error" 3 "Not Available" ;
VAL_ 2432656705 pOperatorButton3 0 "Not Pressed" 1 "Pressed" 2 "Error" 3 "Not Available" ;
VAL_ 2432656705 pOperatorButton4 0 "Not Pressed" 1 "Pressed" 2 "Error" 3 "Not Available" ;
VAL_ 2432656705 pOperatorButton5 0 "Not Pressed" 1 "Pressed" 2 "Error" 3 "Not Available" ;
VAL_ 2432656705 pOperatorButton6 0 "Not Pressed" 1 "Pressed" 2 "Error" 3 "Not Available" ;
VAL_ 2432656705 pOperatorButton7 0 "Not Pressed" 1 "Pressed" 2 "Error" 3 "Not Available" ;
VAL_ 2432656705 pOperatorButton8 0 "Not Pressed" 1 "Pressed" 2 "Error" 3 "Not Available" ;
VAL_ 2432656705 pOperatorButton9 0 "Not Pressed" 1 "Pressed" 2 "Error" 3 "Not Available" ;
VAL_ 2432656705 pOperatorButton10 0 "Not Pressed" 1 "Pressed" 2 "Error" 3 "Not Available" ;
VAL_ 2432656705 pOperatorButton11 0 "Not Pressed" 1 "Pressed" 2 "Error" 3 "Not Available" ;
VAL_ 2432656705 pOperatorButton12 0 "Not Pressed" 1 "Pressed" 2 "Error" 3 "Not Available" ;
VAL_ 2432656705 pOperatorButton13 0 "Not Pressed" 1 "Pressed" 2 "Error" 3 "Not Available" ;
VAL_ 2432656705 pOperatorButton14 0 "Not Pressed" 1 "Pressed" 2 "Error" 3 "Not Available" ;
VAL_ 2432656705 pOperatorButton15 0 "Not Pressed" 1 "Pressed" 2 "Error" 3 "Not Available" ;
VAL_ 2432656705 pOperatorButton16 0 "Not Pressed" 1 "Pressed" 2 "Error" 3 "Not Available" ;
VAL_ 2432656705 pOperatorButton17 0 "Not Pressed" 1 "Pressed" 2 "Error" 3 "Not Available" ;
VAL_ 2432656705 pOperatorButton18 0 "Not Pressed" 1 "Pressed" 2 "Error" 3 "Not Available" ;
VAL_ 2432656705 pOperatorButton19 0 "Not Pressed" 1 "Pressed" 2 "Error" 3 "Not Available" ;
VAL_ 2432656705 pOperatorButton20 0 "Not Pressed" 1 "Pressed" 2 "Error" 3 "Not Available" ;
VAL_ 2432656705 pOperatorButton21 0 "Not Pressed" 1 "Pressed" 2 "Error" 3 "Not Available" ;
VAL_ 2432656705 pOperatorButton22 0 "Not Pressed" 1 "Pressed" 2 "Error" 3 "Not Available" ;
VAL_ 2432656705 pOperatorButton23 0 "Not Pressed" 1 "Pressed" 2 "Error" 3 "Not Available" ;
VAL_ 2432656705 pOperatorButton24 0 "Not Pressed" 1 "Pressed" 2 "Error" 3 "Not Available" ;
VAL_ 2432656705 pOperatorButton25 0 "Not Pressed" 1 "Pressed" 2 "Error" 3 "Not Available" ;
VAL_ 2432656705 pOperatorButton26 0 "Not Pressed" 1 "Pressed" 2 "Error" 3 "Not Available" ;
VAL_ 2432656705 pOperatorButton27 0 "Not Pressed" 1 "Pressed" 2 "Error" 3 "Not Available" ;
VAL_ 2432656705 pOperatorButton28 0 "Not Pressed" 1 "Pressed" 2 "Error" 3 "Not Available" ;
VAL_ 2432656705 pSideStandStatus 3 "Not Available" 2 "Error Indicator" 1 "Side Stand Up" 0 "Side Stand Down" ;
VAL_ 2365523591 pModCtlAppliedState 15 "Not Availble" 14 "Error State" 13 "No Change - Checksum Error" 12 "Future Use" 11 "Future Use" 10 "Future Use" 9 "Future Use" 8 "Future Use" 7 "Future Use" 6 "Future Use" 5 "Future Use" 4 "Stay Awake Applied" 3 "Power Down Applied" 2 "Full Wakeup Applied" 1 "Partial Wakeup Applied" 0 "No Change Applied" ;
VAL_ 2365523591 pModCtlCmdState 15 "Not Available" 14 "Error State" 13 "Future Use" 12 "Future Use" 11 "Future Use" 10 "Future Use" 9 "Future Use" 8 "Future Use" 7 "Future Use" 6 "Future Use" 5 "Future Use" 4 "Stay Awak Requested" 3 "Power Down Requested" 2 "Full Wakeup Requested" 1 "Partial Wakeup Requested" 0 "No Change Requested" ;
VAL_ 2365523590 pModCtlAppliedState 15 "Not Availble" 14 "Error State" 13 "No Change - Checksum Error" 12 "Future Use" 11 "Future Use" 10 "Future Use" 9 "Future Use" 8 "Future Use" 7 "Future Use" 6 "Future Use" 5 "Future Use" 4 "Stay Awake Applied" 3 "Power Down Applied" 2 "Full Wakeup Applied" 1 "Partial Wakeup Applied" 0 "No Change Applied" ;
VAL_ 2365523590 pModCtlCmdState 15 "Not Available" 14 "Error State" 13 "Future Use" 12 "Future Use" 11 "Future Use" 10 "Future Use" 9 "Future Use" 8 "Future Use" 7 "Future Use" 6 "Future Use" 5 "Future Use" 4 "Stay Awak Requested" 3 "Power Down Requested" 2 "Full Wakeup Requested" 1 "Partial Wakeup Requested" 0 "No Change Requested" ;
VAL_ 2566844807 TwoSpeedAxleSwitch 0 "LowSpeedRange" 1 "HighSpeedRange" 2 "Error" 3 "NotAvailable" ;
VAL_ 2566844807 ParkingBrakeSwitch 0 "NotSet" 1 "Set" 2 "Error" 3 "NotAvailable" ;
VAL_ 2566844807 CruiseCtrlActive 0 "SwitchedOff" 1 "SwitchedOn" 2 "Error" 3 "NotAvailable" ;
VAL_ 2566844807 CruiseCtrlEnableSwitch 0 "Disabled" 1 "Enabled" 2 "Error" 3 "NotAvailable" ;
VAL_ 2566844807 BrakeSwitch 0 "PedalReleased" 1 "PedalDepressed" 2 "Error" 3 "NotAvailable" ;
VAL_ 2566844807 ClutchSwitch 0 "PedalReleased" 1 "PedalDepressed" 2 "Error" 3 "NotAvailable" ;
VAL_ 2566844807 CruiseCtrlSetSwitch 0 "NotSet" 1 "Set" 2 "Error" 3 "NotAvailable" ;
VAL_ 2566844807 CruiseCtrlCoastSwitch 0 "NotCoast" 1 "Coast" 2 "Error" 3 "NotAvailable" ;
VAL_ 2566844807 CruiseCtrlResumeSwitch 0 "NotResume" 1 "Resume" 2 "Error" 3 "NotAvailable" ;
VAL_ 2566844807 CruiseCtrlAccelerateSwitch 0 "NotAccelerate" 1 "Accelerate" 2 "Error" 3 "NotAvailable" ;
VAL_ 2566844807 pOdometerDriveBit 0 "State A" 1 "State B" 2 "Error" 3 "Not Available/Initialize" ;
VAL_ 2566844807 CruiseCtrlPauseSw 0 "Off" 1 "On" 2 "Error" 3 "Take No Action" ;
VAL_ 2566844807 pCruiseEnableStatus 0 "Not enabled." 1 "Enabled but not activated." 2 "Reserved" 14 "Error Indicator" 15 "Not Available" ;
VAL_ 2365523495 pModCtlAppliedState 15 "Not Availble" 14 "Error State" 13 "No Change - Checksum Error" 12 "Future Use" 11 "Future Use" 10 "Future Use" 9 "Future Use" 8 "Future Use" 7 "Future Use" 6 "Future Use" 5 "Future Use" 4 "Stay Awake Applied" 3 "Power Down Applied" 2 "Full Wakeup Applied" 1 "Partial Wakeup Applied" 0 "No Change Applied" ;
VAL_ 2365523495 pModCtlCmdState 15 "Not Available" 14 "Error State" 13 "Future Use" 12 "Future Use" 11 "Future Use" 10 "Future Use" 9 "Future Use" 8 "Future Use" 7 "Future Use" 6 "Future Use" 5 "Future Use" 4 "Stay Awak Requested" 3 "Power Down Requested" 2 "Full Wakeup Requested" 1 "Partial Wakeup Requested" 0 "No Change Requested" ;
VAL_ 2566834727 DM_FlashRedStopLamp 3 "Unavailable / Do Not Flash" 2 "Reserved" 1 "Fast Flash (2 Hz, 50% DC)" 0 "Slow Flash (1 Hz, 50% DC)" ;
VAL_ 2566834727 DM_FlashProtectLamp 3 "Unavailable / Do Not Flash" 2 "Reserved" 1 "Fast Flash (2 Hz, 50% DC)" 0 "Slow Flash (1 Hz, 50% DC)" ;
VAL_ 2566834727 DM_FlashMalfuncIndicatorLamp 3 "Unavailable / Do Not Flash" 2 "Reserved" 1 "Fast Flash (2 Hz, 50% DC)" 0 "Slow Flash (1 Hz, 50% DC)" ;
VAL_ 2566834727 DM_FlashAmberWarningLamp 3 "Unavailable / Do Not Flash" 2 "Reserved" 1 "Fast Flash (2 Hz, 50% DC)" 0 "Slow Flash (1 Hz, 50% DC)" ;
VAL_ 2566834727 DM_ProtectLampStatus 0 "Lamp off" 1 "Lamp on" 2 "Reserved" 3 "Not available" ;
VAL_ 2566834727 DM_RedStopLampState 0 "Lamp off" 1 "Lamp on" 2 "Reserved" 3 "Not available" ;
VAL_ 2566834727 DM_AmberWrningLmpStatus 0 "Lamp off" 1 "Lamp on" 2 "Reserved" 3 "Not available" ;
VAL_ 2566834727 DM_MalfuncnIndicatorLampStatus 0 "Lamp off" 1 "Lamp on" 2 "Reserved" 3 "Not available" ;
VAL_ 2365473063 LowBeamHeadlightCommand 3 "Don't Care" 2 "Reserved" 1 "Activate" 0 "De-activate" ;
VAL_ 2365473063 HighBeamHeadlightCommand 3 "Don't Care" 2 "Reserved" 1 "Activate" 0 "De-activate" ;
VAL_ 2365473063 LeftTurnSigLightsCommand 0 "De-activate" 1 "Activate" 2 "Reserved" 3 "Don't Care" ;
VAL_ 2365473063 RightTurnSigLightsCommand 0 "De-activate" 1 "Activate" 2 "Reserved" 3 "Don't Care" ;
VAL_ 2633883431 FrtWheelDriveActuatorStatus 0 "Front Wheel Drive Actuator not e" 1 "Front Wheel Drive Actuator engag" 2 "Error" 3 "Not available" ;
VAL_ 2566877479 pVolumeUnitsSelected 7 "Not Available" 6 "Error" 5 "Reserved" 4 "Reserved" 3 "Reserved" 2 "Imperial Gallons" 1 "Liters" 0 "Gallons" ;
VAL_ 2566877479 pTimeUnitsSelected 3 "Not Available" 2 "Error" 1 "24 Hour" 0 "12 Hour" ;
VAL_ 2566877479 pTemperatureUnitsSelected 3 "Not Avaialable" 2 "Error" 1 "Celsius" 0 "Farenheit" ;
VAL_ 2566877479 pPressureUnitsSelected 3 "Not Available" 2 "Error" 1 "Kilopascal (kPa)" 0 "Pounds Per Square Inch (PSI)" ;
VAL_ 2566877479 pDistanceUnitsSelected 3 "Not Available" 2 "Error" 1 "Kilometers" 0 "Miles" ;
VAL_ 2566877479 pTPMSLearningStatus 0 "Not Started" 1 "Request to start" 2 "Learning Left Front" 3 "Learning Right Front" 4 "Learning Left Rear" 5 "Learning Right Rear" 6 "Learning successfully completed" 13 "Request to end learning" 14 "Error - Failed Learning" 15 "Not Available" ;
VAL_ 2566877479 pDisplayStatus 0 "Info cant overide to full screen" 1 "User requested full screen" 2 "Info can overide to full screen" 14 "Info data is not shown" 15 "Not Available" ;
VAL_ 2566887168 pVehicleEventStatusCornering 3 "Not Available" 2 "Error" 1 "Cornering Event Detected" 0 "No Cornering Event Detected" ;
VAL_ 2566887168 pVehicleEventStatusBraking 3 "Not Available" 2 "Error" 1 "Braking Event Detected" 0 "No Braking Event Detected" ;
VAL_ 2566887168 pVehicleEventStatusAirborne 3 "Not Available" 2 "Error" 1 "Airborne Event Detected" 0 "No Airborne Event Detected" ;
VAL_ 2566887168 pVehicleEventStatusAccel 3 "Not Available" 2 "Error" 1 "Acceleration Event Detected" 0 "No Acceleration Event Detected" ;
VAL_ 2566887168 pSuspensionModeActive 14 "Not Available" 13 "Error State" 12 "Available for future use" 11 "Available for future use" 10 "Available for future use" 9 "Available for future use" 8 "Available for future use" 7 "Available for future use" 6 "Available for future use" 5 "Available for future use" 4 "Semi-Active Damping - Sport" 3 "Semi-Active Damping - Comfort" 2 "Passive - Soft" 1 "Passive - Medium" 0 "Passive - Firm" ;
VAL_ 2431708455 EngineStarter2Feedback 7 "Not Available" 6 "Reserved" 5 "Reserved" 4 "unlatched, aborted by starter" 0 "Starter not commanded" 1 "Command latched, starter active" 2 "unlatched/ complete, rets to 0" 3 "unlachd, abort recvd: arbitrator" ;
VAL_ 2431708455 EngineStarter1Feedback 0 "Start not requested" 1 "Starter active, gear not engaged" 2 "Starter active, gear engaged" 3 "Start finished; starter not acti" 4 "Starter inhibited due to engine " 6 "Starter inhibited due to driveli" 7 "Starter inhibited due to active " 8 "Starter inhibited due to starter" 9 "Reserved" 14 "Error" 15 "Not available" ;
VAL_ 2431708455 EngineStartAbortReq 0 "Abort not requested" 1 "Abort requested" 2 "Reserved" 3 "Don't Care / Take No Action" ;
VAL_ 2431708455 TransShiftSelectRequVehDir 7 "Not Supported" 6 "Error" 5 "4 SAE Reserved" 4 "4 SAE Reserved" 0 "No direction selected - Park" 1 "No direction selected - Neutral" 2 "Forward direction selected" 3 "Reverse direction selected" ;
VAL_ 2431708455 EngineStartReq 0 "Start not requested" 1 "Start Requested, operator type" 2 "Start Requested, automatic type" 3 "Not available" ;
VAL_ 2431708455 EngineStartConsent 7 "Not Available" 6 "Reserved" 5 "Reserved" 4 "Reserved" 0 "No consent" 1 "Consent to operator-req start" 2 "Consent to automatic start only" 3 "Consent to both" ;
VAL_ 2297441583 Vertical_Accel_Ext_Merit 3 "Not Available" 2 "error" 1 "Accel degraded" 0 "Accel fully functional" ;
VAL_ 2297441583 Longitudinal_Accel_Ext_Merit 3 "Not Available" 2 "error" 1 "Accel degraded" 0 "Accel fully functional" ;
VAL_ 2297441583 Lateral_Accel_Ext_Merit 3 "Not Available" 2 "error" 1 "Accel degraded" 0 "Accel fully functional" ;
VAL_ 2297441583 Accel_Sensor_Support_Var 3 "Supports 10ms Tx Rate Only" 2 "20ms rate supported" 1 "Reserved for SAE Assignment" 0 "Reserved for SAE Assignment" ;
VAL_ 2432656774 pOperatorButton29 3 "Not Available" 2 "Error" 1 "Button Pressed" 0 "Button Not Pressed" ;
VAL_ 2432656774 pOperatorButton1 0 "Not Pressed" 1 "Pressed" 2 "Error" 3 "Not Available" ;
VAL_ 2432656774 pOperatorButton2 0 "Active" 1 "Inactive" 2 "Error" 3 "Not Available" ;
VAL_ 2432656774 pOperatorButton3 0 "Not Pressed" 1 "Pressed" 2 "Error" 3 "Not Available" ;
VAL_ 2432656774 pOperatorButton4 0 "Not Pressed" 1 "Pressed" 2 "Error" 3 "Not Available" ;
VAL_ 2432656774 pOperatorButton5 0 "Not Pressed" 1 "Pressed" 2 "Error" 3 "Not Available" ;
VAL_ 2432656774 pOperatorButton6 0 "Not Pressed" 1 "Pressed" 2 "Error" 3 "Not Available" ;
VAL_ 2432656774 pOperatorButton7 0 "Not Pressed" 1 "Pressed" 2 "Error" 3 "Not Available" ;
VAL_ 2432656774 pOperatorButton8 0 "Not Pressed" 1 "Pressed" 2 "Error" 3 "Not Available" ;
VAL_ 2432656774 pOperatorButton9 0 "Not Pressed" 1 "Pressed" 2 "Error" 3 "Not Available" ;
VAL_ 2432656774 pOperatorButton10 0 "Not Pressed" 1 "Pressed" 2 "Error" 3 "Not Available" ;
VAL_ 2432656774 pOperatorButton11 0 "Not Pressed" 1 "Pressed" 2 "Error" 3 "Not Available" ;
VAL_ 2432656774 pOperatorButton12 0 "Not Pressed" 1 "Pressed" 2 "Error" 3 "Not Available" ;
VAL_ 2432656774 pOperatorButton13 0 "Not Pressed" 1 "Pressed" 2 "Error" 3 "Not Available" ;
VAL_ 2432656774 pOperatorButton14 0 "Not Pressed" 1 "Pressed" 2 "Error" 3 "Not Available" ;
VAL_ 2432656774 pOperatorButton15 0 "Not Pressed" 1 "Pressed" 2 "Error" 3 "Not Available" ;
VAL_ 2432656774 pOperatorButton16 0 "Not Pressed" 1 "Pressed" 2 "Error" 3 "Not Available" ;
VAL_ 2432656774 pOperatorButton17 0 "Not Pressed" 1 "Pressed" 2 "Error" 3 "Not Available" ;
VAL_ 2432656774 pOperatorButton18 0 "Not Pressed" 1 "Pressed" 2 "Error" 3 "Not Available" ;
VAL_ 2432656774 pOperatorButton19 0 "Not Pressed" 1 "Pressed" 2 "Error" 3 "Not Available" ;
VAL_ 2432656774 pOperatorButton20 0 "Not Pressed" 1 "Pressed" 2 "Error" 3 "Not Available" ;
VAL_ 2432656774 pOperatorButton21 0 "Not Pressed" 1 "Pressed" 2 "Error" 3 "Not Available" ;
VAL_ 2432656774 pOperatorButton22 0 "Not Pressed" 1 "Pressed" 2 "Error" 3 "Not Available" ;
VAL_ 2432656774 pOperatorButton23 0 "Not Pressed" 1 "Pressed" 2 "Error" 3 "Not Available" ;
VAL_ 2432656774 pOperatorButton24 0 "Not Pressed" 1 "Pressed" 2 "Error" 3 "Not Available" ;
VAL_ 2432656774 pOperatorButton25 0 "Not Pressed" 1 "Pressed" 2 "Error" 3 "Not Available" ;
VAL_ 2432656774 pOperatorButton26 0 "Not Pressed" 1 "Pressed" 2 "Error" 3 "Not Available" ;
VAL_ 2432656774 pOperatorButton27 0 "Not Pressed" 1 "Pressed" 2 "Error" 3 "Not Available" ;
VAL_ 2432656774 pOperatorButton28 0 "Not Pressed" 1 "Pressed" 2 "Error" 3 "Not Available" ;
VAL_ 2432656774 pSideStandStatus 3 "Not Available" 2 "Error Indicator" 1 "Side Stand Up" 0 "Side Stand Down" ;
VAL_ 2565799489 ArbitraryAddressCapable 0 "No" 1 "Yes" ;
VAL_ 2565799453 ArbitraryAddressCapable 0 "No" 1 "Yes" ;
VAL_ 2565799447 ArbitraryAddressCapable 0 "No" 1 "Yes" ;
VAL_ 2565799443 ArbitraryAddressCapable 0 "No" 1 "Yes" ;
VAL_ 2565799435 ArbitraryAddressCapable 0 "No" 1 "Yes" ;
VAL_ 2565799424 ArbitraryAddressCapable 0 "No" 1 "Yes" ;
VAL_ 2631794205 EncryptionIndicatorStates 0 "Encryption seed request" 1 "Encryption code present" 2 "Not defined" 3 "Not available" ;
VAL_ 2631794205 AntiTheftDesiredExitModeStates 0 "Locked upon operator request" 1 "Lock when key off" 2 "Not defined" 3 "Not available" ;
VAL_ 2631794205 AntiTheftCommandStates 0 "Add password" 1 "Delete password" 2 "Change password" 3 "Lock or Unlock" 4 "Check status" 5 "Login" ;
VAL_ 2631794199 EncryptionIndicatorStates 0 "Encryption seed request" 1 "Encryption code present" 2 "Not defined" 3 "Not available" ;
VAL_ 2631794199 AntiTheftDesiredExitModeStates 0 "Locked upon operator request" 1 "Lock when key off" 2 "Not defined" 3 "Not available" ;
VAL_ 2631794199 AntiTheftCommandStates 0 "Add password" 1 "Delete password" 2 "Change password" 3 "Lock or Unlock" 4 "Check status" 5 "Login" ;
VAL_ 2631728640 AntiTheftEncryptSeedPresentInd 0 "Random number is not present" 1 "Random number is present" 2 "Reserved" 3 "Don't care" ;
VAL_ 2631728640 AntiTheftPasswordValidIndicator 0 "Password is not a validated pass" 1 "Password is a validated password" 2 "Reserved" 3 "Don't care" ;
VAL_ 2631728640 AntiTheftModifyPasswordStates 0 "Ok" 1 "Full of passwords" 2 "Empty of passwords" 3 "Not valid" ;
VAL_ 2631728640 AntiTheftComponentStatusInd 0 "Unlocked" 1 "Locked" 2 "Blocked" 3 "Not defined" ;
VAL_ 2561212031 TextDisplayInstructions 0 "Clear Display" 1 "Hold Display" 2 "Append at end of display" 3 "Overwrite display" 4 "Overwrite substring" 5 "Highlight substring" 6 "Blink substring" 7 "Reserved" 15 "Not applicable" ;
VAL_ 2566904832 DL22_pMisfireDetectedMultplSrcs 3 "Not Available" 2 "Error" 1 "Active" 0 "Inactive" ;
VAL_ 2566904832 DL22_pCatDamageMisfireRateExceed 3 "Not Available" 2 "Error" 1 "Active" 0 "Inactive" ;
VAL_ 2432658432 pOperatorButton42 3 "Not Available" 2 "Error" 1 "Button pressed" 0 "Button not pressed" ;
VAL_ 2432658432 pOperatorButton41 3 "Not Available" 2 "Error" 1 "Button pressed" 0 "Button not pressed" ;
VAL_ 2432658432 pOperatorButton39 3 "Not Available" 2 "Error" 1 "Button Pressed" 0 "Button Not Pressed" ;
VAL_ 2432658432 pOperatorButton37 3 "Not Available" 2 "Error" 1 "Button Pressed" 0 "Button Not Pressed" ;
VAL_ 2432658432 pOperatorButton36 3 "Not Available" 2 "Error" 1 "Button Pressed" 0 "Button Not Pressed" ;
VAL_ 2432658432 pOperatorButton40 3 "Not Available" 2 "Error" 1 "Enabled" 0 "Disabled" ;
VAL_ 2432658432 pOperatorButton38 3 "Not Available" 2 "Error" 1 "Button Pressed" 0 "Button Not Pressed" ;
VAL_ 2432658432 pOperatorButton35 3 "Not Available" 2 "Error" 1 "Button Pressed" 0 "Button Not Pressed" ;
VAL_ 2432658432 pOperatorButton34 3 "Not Available" 2 "Error" 1 "Button Pressed" 0 "Button Not Pressed" ;
VAL_ 2432658432 pOperatorButton33 3 "Not Available" 2 "Error" 1 "Button Pressed" 0 "Button Not Pressed" ;
VAL_ 2432658432 pOperatorButton32 3 "Not Available" 2 "Error" 1 "Button Pressed" 0 "Button Not Pressed" ;
VAL_ 2432658432 pOperatorButton31 3 "Not Available" 2 "Error" 1 "Button Pressed" 0 "Button Not Pressed" ;
VAL_ 2432658432 pOperatorButton30 3 "Not Available" 2 "Error" 1 "Button Pressed" 0 "Button Not Pressed" ;
VAL_ 2432658432 pOperatorButton29 3 "Not Available" 2 "Error" 1 "Button Pressed" 0 "Button Not Pressed" ;
VAL_ 2633984512 pHeatedGripEnable 3 "Description for the value '3'" 2 "Error Indicator" 1 "Enabled (Installed)" 0 "Disabled (Not installed)" ;
VAL_ 2633984512 pSideStandStatus 3 "Not Available" 2 "Error Indicator" 1 "Side Stand Up" 0 "Side Stand Down" ;
VAL_ 2633984512 pTetherSwitchStatus 3 "Not Available" 2 "Error" 1 "Tether SW Open (disconnected)" 0 "Tether SW Closed (connected)" ;
VAL_ 2633984512 pLowFuelIndicatorStatus 3 "Not Available" 2 "Error" 1 "Low Fuel Indicator On" 0 "Low Fuel Indicator Off" ;
VAL_ 2633984512 pOperatorNotInOperatingStation 3 "Description for the value '3'" 2 "Error" 1 "Operator Not In OperatorStation" 0 "Operator In OperatorStation" ;
VAL_ 2633984512 pParkBrakeIndicatorStatus 7 "Not Available" 6 "Error Indicator" 5 "Available for future use" 4 "Available for future use" 3 "Park Brake Indicator 2 Hz flash" 2 "Park Brake Indicator 1 Hz flash" 1 "Park Brake Indicator On (Solid)" 0 "Park Brake Indicator Off" ;
VAL_ 2633984512 pADCRequested 3 "Not Available" 2 "Error" 1 "ADC Mode Requested" 0 "ADC Mode not Requested" ;
VAL_ 2633984512 pAWDModeRequested 3 "Not Available" 2 "Error" 1 "AWD Mode Requested" 0 "AWD Mode not Requested" ;
VAL_ 2633984512 pRWDModeRequested 3 "Not Available" 2 "Error" 1 "RWD Mode Requested" 0 "RWD Mode not Requested" ;
VAL_ 2633984512 pTurfModeRequested 3 "Not Available" 2 "Error" 1 "Turf Mode Requested" 0 "Turf Mode not Requested" ;
VAL_ 2633984512 pADCStatus 0 "ADC Actuator Not Engaged" 1 "ADC Actuator Engaged" 2 "Error" 3 "Not available" ;
VAL_ 2633984512 pTreadleNeutralStatus 0 "Treadle Neutral Not Engaged" 1 "Treadle Neutral Engaged" 2 "Error" 3 "Not Available" ;
VAL_ 2633984512 pTreadleReverseStatus 0 "Treadle Reverse Not Engaged" 1 "Treadle Reverse Engaged" 2 "Error" 3 "Not Available" ;
VAL_ 2633984512 pSecurityLightStatus 0 "Off" 1 "On (Solid)" 2 "Error (Flashing)" 3 "Not Available" ;
VAL_ 2633984512 pHighBeamIndicatorStatus 0 "Indicator Off" 1 "Indicator On" 2 "Error (Indicator Flashing)" 3 "Not Available" ;
VAL_ 2633984512 pCruiseControlSetStatus 0 "Cruise Not Set" 1 "Cruise Set" 2 "Error (Lamp Flashing)" 3 "Not Available" ;
VAL_ 2633984512 pSeatBeltIndicatorStatus 0 "Seat_Belt_Indicator_Off" 1 "Seat_Belt_Indicator_On_Solid" 2 "Seat_Belt_Indicator_1Hz" 3 "Seat_Belt_Indicator_2Hz" 4 "Future1" 5 "Future2" 6 "Error" 7 "Not_Available" ;
VAL_ 2565867008 Location 255 "NotAvailable" ;
VAL_ 2565867008 DifferentialLockFrontAxle1 0 "Disengage" 1 "Engage" 2 "Reserved" 3 "NoAction" ;
VAL_ 2565867008 DifferentialLockFrontAxle2 0 "Disengage" 1 "Engage" 2 "Reserved" 3 "NoAction" ;
VAL_ 2565867008 DifferentialLockRearAxle1 0 "Disengage" 1 "Engage" 2 "Reserved" 3 "NoAction" ;
VAL_ 2565867008 DifferentialLockRearAxle2 0 "Disengage" 1 "Engage" 2 "Reserved" 3 "NoAction" ;
VAL_ 2565867008 DifferentialCentral 0 "Disengage" 1 "Engage" 2 "Reserved" 3 "NoAction" ;
VAL_ 2565867008 DifferentialCentralFront 0 "Disengage" 1 "Engage" 2 "Reserved" 3 "NoAction" ;
VAL_ 2565867008 DifferentialCentralRear 0 "Disengage" 1 "Engage" 2 "Reserved" 3 "NoAction" ;
VAL_ 2566834688 DM_ProtectLampStatus 0 "Lamp off" 1 "Lamp on" 2 "Reserved" 3 "Not available" ;
VAL_ 2566834688 DM_RedStopLampState 0 "Lamp off" 1 "Lamp on" 2 "Reserved" 3 "Not available" ;
VAL_ 2566834688 DM_AmberWrningLmpStatus 0 "Lamp off" 1 "Lamp on" 2 "Reserved" 3 "Not available" ;
VAL_ 2566834688 DM_MalfuncnIndicatorLampStatus 0 "Lamp off" 1 "Lamp on" 2 "Reserved" 3 "Not available" ;
VAL_ 2566834688 DM_FlashRedStopLamp 3 "Unavailable / Do Not Flash" 2 "Reserved" 1 "Fast Flash (2 Hz, 50% DC)" 0 "Slow Flash (1 Hz, 50% DC)" ;
VAL_ 2566834688 DM_FlashMalfuncIndicatorLamp 3 "Unavailable / Do Not Flash" 2 "Reserved" 1 "Fast Flash (2 Hz, 50% DC)" 0 "Slow Flash (1 Hz, 50% DC)" ;
VAL_ 2566834688 DM_FlashProtectLamp 3 "Unavailable / Do Not Flash" 2 "Reserved" 1 "Fast Flash (2 Hz, 50% DC)" 0 "Slow Flash (1 Hz, 50% DC)" ;
VAL_ 2566834688 DM_FlashAmberWarningLamp 3 "Unavailable / Do Not Flash" 2 "Reserved" 1 "Fast Flash (2 Hz, 50% DC)" 0 "Slow Flash (1 Hz, 50% DC)" ;
VAL_ 2564356352 DM15_Seed 65535 "No Further Key required of Tool" 1 "Use Long Seed or Key" 0 "Seed Complete - send key" ;
VAL_ 2564356352 DM15_Error_Ind_EDC_Parameter 16777215 "No Error Indicator Available" 65540 "Transport NOT completed in time" 65539 "Transport NOT initiated in time" 65538 "NO response in the time allowed" 65537 "Too Many Retries" 65536 "Abort from external" 4103 "Security Error - NOT in Park" 4102 "Security Error - Engine running" 4101 "Security Error NOT in Dev mode" 4100 "Security Error NOT in Diag mode" 4099 "Security Error Invalid Key" 4098 "Security Error Invalid User Lvl" 4097 "Security Error Invalid Password" 4096 "Security Error General" 266 "DATA Error NAME unexpected value" 265 "DATA Error invalid value ranges" 264 "Addressing Error invalid bounds" 263 "Addressing Error wrong memory" 262 "Addressing Error requires trans" 261 "Addressing Error requires erase" 260 "Addressing Error requires erase" 259 "Addressing Error exceeded memory" 258 "Addressing Error Length invalid" 257 "Addressing Error bounds invalid" 256 "Addressing or DATA General Error" 36 "Internal failure preventing req" 35 "PROM did not verify on Write" 34 "FLASH did not verify on Write" 33 "RAM did not verify on Write" 32 "EDC parm not correct for data" 31 "Currently processing request" 23 "Currently processing Gen Req" 22 "Currently processing Boot Req" 19 "Currently processing Status Req" 18 "Currently processing Write Req" 17 "Currently processing Read Req" 16 "Currently processing Erase Req" 2 "Currently processing for another" 1 "Error NOT identified" 0 "No Error" ;
VAL_ 2564356352 DM15_EDCP_Extension 255 "No Error/EDC Parameter Available" 7 "Data in Error Indicator" 6 "Data in Error Indicator" 3 "More, Lower order EDC Parameter" 2 "More, Higher order EDC Parameter" 0 "Completed" ;
VAL_ 2564356352 DM15_Status 7 "Reserved" 6 "Reserved" 5 "Operation Failed" 4 "Operation Completed" 3 "Reserved" 2 "Reserved" 1 "Busy" 0 "Proceed" ;
VAL_ 2633883392 FrtWheelDriveActuatorStatus 0 "Front Wheel Drive Actuator not e" 1 "Front Wheel Drive Actuator engag" 2 "Error" 3 "Not available" ;
VAL_ 2432656640 pOperatorButton29 3 "Not Available" 2 "Error" 1 "Button Pressed" 0 "Button Not Pressed" ;
VAL_ 2432656640 pOperatorButton1 0 "Not Pressed" 1 "Pressed" 2 "Error" 3 "Not Available" ;
VAL_ 2432656640 pOperatorButton2 0 "Active" 1 "Inactive" 2 "Error" 3 "Not Available" ;
VAL_ 2432656640 pOperatorButton3 0 "Not Pressed" 1 "Pressed" 2 "Error" 3 "Not Available" ;
VAL_ 2432656640 pOperatorButton4 0 "Not Pressed" 1 "Pressed" 2 "Error" 3 "Not Available" ;
VAL_ 2432656640 pOperatorButton5 0 "Not Pressed" 1 "Pressed" 2 "Error" 3 "Not Available" ;
VAL_ 2432656640 pOperatorButton6 0 "Not Pressed" 1 "Pressed" 2 "Error" 3 "Not Available" ;
VAL_ 2432656640 pOperatorButton7 0 "Not Pressed" 1 "Pressed" 2 "Error" 3 "Not Available" ;
VAL_ 2432656640 pOperatorButton8 0 "Not Pressed" 1 "Pressed" 2 "Error" 3 "Not Available" ;
VAL_ 2432656640 pOperatorButton9 0 "Not Pressed" 1 "Pressed" 2 "Error" 3 "Not Available" ;
VAL_ 2432656640 pOperatorButton10 0 "Not Pressed" 1 "Pressed" 2 "Error" 3 "Not Available" ;
VAL_ 2432656640 pOperatorButton11 0 "Not Pressed" 1 "Pressed" 2 "Error" 3 "Not Available" ;
VAL_ 2432656640 pOperatorButton12 0 "Not Pressed" 1 "Pressed" 2 "Error" 3 "Not Available" ;
VAL_ 2432656640 pOperatorButton13 0 "Not Pressed" 1 "Pressed" 2 "Error" 3 "Not Available" ;
VAL_ 2432656640 pOperatorButton14 0 "Not Pressed" 1 "Pressed" 2 "Error" 3 "Not Available" ;
VAL_ 2432656640 pOperatorButton15 0 "Not Pressed" 1 "Pressed" 2 "Error" 3 "Not Available" ;
VAL_ 2432656640 pOperatorButton16 0 "Not Pressed" 1 "Pressed" 2 "Error" 3 "Not Available" ;
VAL_ 2432656640 pOperatorButton17 0 "Not Pressed" 1 "Pressed" 2 "Error" 3 "Not Available" ;
VAL_ 2432656640 pOperatorButton18 0 "Not Pressed" 1 "Pressed" 2 "Error" 3 "Not Available" ;
VAL_ 2432656640 pOperatorButton19 0 "Not Pressed" 1 "Pressed" 2 "Error" 3 "Not Available" ;
VAL_ 2432656640 pOperatorButton20 0 "Not Pressed" 1 "Pressed" 2 "Error" 3 "Not Available" ;
VAL_ 2432656640 pOperatorButton21 0 "Not Pressed" 1 "Pressed" 2 "Error" 3 "Not Available" ;
VAL_ 2432656640 pOperatorButton22 0 "Not Pressed" 1 "Pressed" 2 "Error" 3 "Not Available" ;
VAL_ 2432656640 pOperatorButton23 0 "Not Pressed" 1 "Pressed" 2 "Error" 3 "Not Available" ;
VAL_ 2432656640 pOperatorButton24 0 "Not Pressed" 1 "Pressed" 2 "Error" 3 "Not Available" ;
VAL_ 2432656640 pOperatorButton25 0 "Not Pressed" 1 "Pressed" 2 "Error" 3 "Not Available" ;
VAL_ 2432656640 pOperatorButton26 0 "Not Pressed" 1 "Pressed" 2 "Error" 3 "Not Available" ;
VAL_ 2432656640 pOperatorButton27 0 "Not Pressed" 1 "Pressed" 2 "Error" 3 "Not Available" ;
VAL_ 2432656640 pOperatorButton28 0 "Not Pressed" 1 "Pressed" 2 "Error" 3 "Not Available" ;
VAL_ 2432656640 pSideStandStatus 3 "Not Available" 2 "Error Indicator" 1 "Side Stand Up" 0 "Side Stand Down" ;
VAL_ 2365548032 pHighIdleState 3 "Not Available" 2 "Error" 1 "Active" 0 "Inactive" ;
VAL_ 2365548032 pStuckThrottle 0 "Throttle not Stuck" 1 "Throttle Stuck" 2 "Error" 3 "Not Available" ;
VAL_ 2566909696 DL12_LambaSensorHeaterOutBank2 0 "Active" 1 "Inactive" 2 "Error" 3 "NotAvailable" ;
VAL_ 2566909696 DL12_AirFuelMixStatusBank2 0 "Rich" 1 "Lean" 2 "Error" 3 "NotAvailable" ;
VAL_ 2566909696 DL12_ClosedLoopMixControlBank2 0 "Active" 1 "Inactive" 2 "Error" 3 "NotAvailable" ;
VAL_ 2566912256 DL7_FuelTypSelected 15 "Not Available" 14 "Fuel Type Error" 8 "Fuel Type 1 (E100)" 7 "Fuel Type 1 (E95)" 6 "Fuel Type 1 (E85)" 5 "Fuel Type 1 (E20)" 4 "Fuel Type 1 (E15)" 3 "Fuel Type 1 (E10)" 2 "Fuel Type 1 (E7)" 1 "Fuel Type 1 (E5)" 0 "Fuel Type 1 (E0)" ;
VAL_ 2566912256 DL7_EngRunngMode 1 "Transient" 0 "Steady" ;
VAL_ 2566912000 DL8_LambaSensorHeaterOutBank1 0 "Active" 1 "Inactive" 2 "Error" 3 "NotAvailable" ;
VAL_ 2566912000 DL8_AirFuelMixStatusBank1 0 "Rich" 1 "Lean" 2 "Error" 3 "NotAvailable" ;
VAL_ 2566912000 DL8_ClosedLoopMixControlBank1 0 "Active" 1 "Inactive" 2 "Error" 3 "NotAvailable" ;
VAL_ 2566911232 FI1_FuelPullSolenoidStatus 3 "Not Available" 2 "Error" 1 "Inactive" 0 "Active" ;
VAL_ 2566911232 FI1_ClutchSwitchInput2 3 "Not Available" 2 "Error" 1 "Inactive" 0 "Active" ;
VAL_ 2566911232 FI1_FuelPumpDriverCkt 0 "Active" 1 "Inactive" 2 "Error" 3 "Not Available" ;
VAL_ 2566911232 FI1_RolloverSwitch 0 "Active" 1 "Inactive" 2 "Error" 3 "Not Available" ;
VAL_ 2566911232 FI1_CrankSensorSignal 0 "Present" 1 "Absent" 2 "Error" 3 "Not Available" ;
VAL_ 2566911232 FI1_CamSensorSignal 0 "Present" 1 "Absent" 2 "Error" 3 "Not Available" ;
VAL_ 2566911232 FI1_RPMLimitActive 0 "Active" 1 "Inactive" 2 "Error" 3 "Not Available" ;
VAL_ 2566911232 FI1_IdleSwitch 0 "Active" 1 "Inactive" 2 "Error" 3 "Not Available" ;
VAL_ 2566911232 FI1_CycleSynchro 0 "Sync" 1 "No-Sync" 2 "Error" 3 "Not Available" ;
VAL_ 2566911232 FI1_IdleSpeedControlStatus 0 "Active" 1 "Inactive" 2 "Error" 3 "Not Available" ;
VAL_ 2566911232 FI1_IgnitionSwitchInput 0 "Input High" 1 "Input Low" 2 "Error" 3 "Not Available" ;
VAL_ 2566911232 FI1_RunStopSwitchInput 0 "Input High" 1 "Input Low" 2 "Error" 3 "Not Available" ;
VAL_ 2566911232 FI1_StartSwitchInput 0 "Input High" 1 "Input Low" 2 "Error" 3 "Not Available" ;
VAL_ 2566911232 FI1_ThrottleSafetySwInput 0 "Input High" 1 "Input Low" 2 "Error" 3 "Not Available" ;
VAL_ 2566911232 FI1_FanRelayOutput 0 "Active" 1 "Inactive" 2 "Error" 3 "Not Available" ;
VAL_ 2566911232 FI1_IntercoolerFanOutput 0 "Active" 1 "Inactive" 2 "Error" 3 "Not Available" ;
VAL_ 2566911232 FI1_ReverseAlarmOutput 0 "Active" 1 "Inactive" 2 "Error" 3 "Not Available" ;
VAL_ 2566911232 FI1_MainRelayOutput 0 "Active" 1 "Inactive" 2 "Error" 3 "Not Available" ;
VAL_ 2566911232 FI1_StartSolenoidOutput 0 "Active" 1 "Inactive" 2 "Error" 3 "Not Available" ;
VAL_ 2566911232 FI1_IgnitionRelayOutput 0 "Active" 1 "Inactive" 2 "Error" 3 "Not Available" ;
VAL_ 2566911232 FI1_ChassisRelayOutput 0 "Active" 1 "Inactive" 2 "Error" 3 "Not Available" ;
VAL_ 2566911232 FI1_StarterEnableOutput 0 "Active" 1 "Inactive" 2 "Error" 3 "Not Available" ;
VAL_ 2566911232 FI1_ExhaustValveOutput 0 "Active" 1 "Inactive" 2 "Error" 3 "Not Available" ;
VAL_ 2566911232 FI1_BatteryChargeRelayOutput 0 "Active" 1 "Inactive" 2 "Error" 3 "Not Available" ;
VAL_ 2566911232 FI1_HeaterAccRelay 0 "Active" 1 "Inactive" 2 "Error" 3 "Not Available" ;
VAL_ 2566911232 FI1_ClutchSwitchInput 0 "Input High" 1 "Input Low" 2 "Error" 3 "Not Available" ;
VAL_ 2566911232 FI1_MILLampOutput 0 "Active" 1 "Inactive" 2 "Error" 3 "Not Available" ;
VAL_ 2566911232 FI1_OverTempLampOutput 0 "Active" 1 "Inactive" 2 "Error" 3 "Not Available" ;
VAL_ 2566911232 FI1_KnockDetLampOutput 0 "Active" 1 "Inactive" 2 "Error" 3 "Not Available" ;
VAL_ 2566911232 FI1_ElecOilPumpDrvrCirc 0 "Active" 1 "Inactive" 2 "Error" 3 "Not Available" ;
